VERSION ""

NS_ :

BS_:

BU_:  Inverter  Battery  Charger  Host

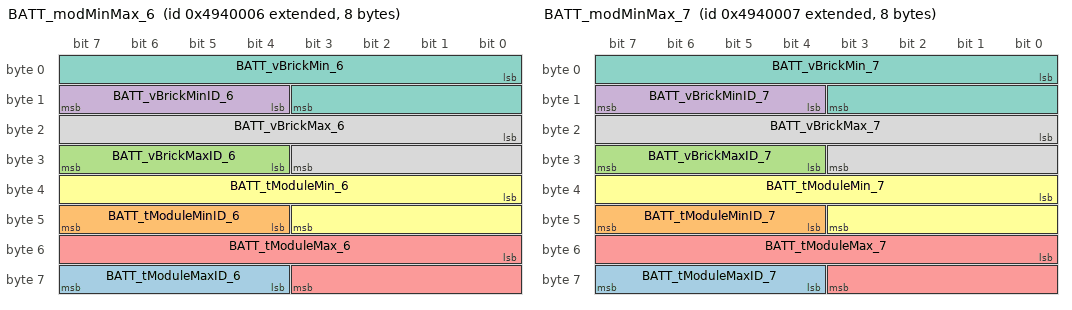
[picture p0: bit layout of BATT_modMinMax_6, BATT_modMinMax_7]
BO_ 2224291846 BATT_modMinMax_6: 8 Battery
 SG_ BATT_tModuleMaxID_6 : 60|4@1+ (1,0) [0|14] "" Battery,Host
 SG_ BATT_tModuleMinID_6 : 44|4@1+ (1,0) [0|14] "" Battery,Host
 SG_ BATT_vBrickMaxID_6 : 28|4@1+ (1,0) [0|14] "" Battery,Host
 SG_ BATT_vBrickMinID_6 : 12|4@1+ (1,0) [0|14] "" Battery,Host
 SG_ BATT_tModuleMax_6 : 48|12@1- (0.1,0) [-40|125] "deg C" Battery,Host
 SG_ BATT_tModuleMin_6 : 32|12@1- (0.1,0) [-40|125] "deg C" Battery,Host
 SG_ BATT_vBrickMin_6 : 0|12@1+ (0.002,0) [0|4.98066] "V" Battery,Host
 SG_ BATT_vBrickMax_6 : 16|12@1+ (0.002,0) [0|4.98066] "V" Battery,Host

BO_ 2224291847 BATT_modMinMax_7: 8 Battery
 SG_ BATT_tModuleMaxID_7 : 60|4@1+ (1,0) [0|14] "" Battery,Host
 SG_ BATT_tModuleMinID_7 : 44|4@1+ (1,0) [0|14] "" Battery,Host
 SG_ BATT_vBrickMaxID_7 : 28|4@1+ (1,0) [0|14] "" Battery,Host
 SG_ BATT_vBrickMinID_7 : 12|4@1+ (1,0) [0|14] "" Battery,Host
 SG_ BATT_tModuleMax_7 : 48|12@1- (0.1,0) [-40|125] "deg C" Battery,Host
 SG_ BATT_tModuleMin_7 : 32|12@1- (0.1,0) [-40|125] "deg C" Battery,Host
 SG_ BATT_vBrickMin_7 : 0|12@1+ (0.002,0) [0|4.98066] "V" Battery,Host
 SG_ BATT_vBrickMax_7 : 16|12@1+ (0.002,0) [0|4.98066] "V" Battery,Host

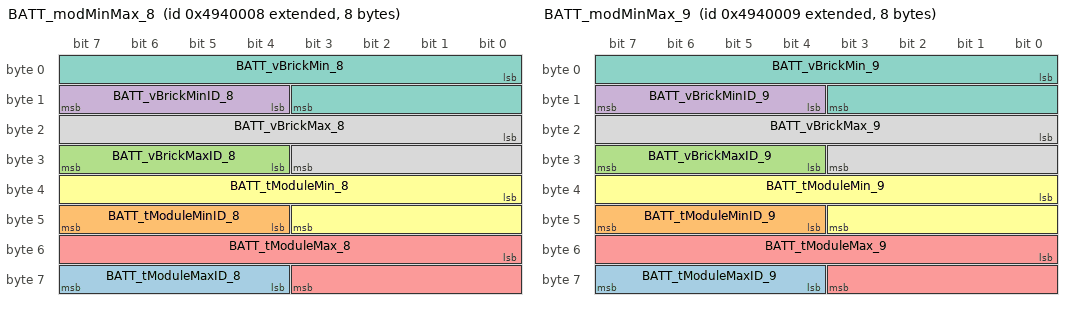
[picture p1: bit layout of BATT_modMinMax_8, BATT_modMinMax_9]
BO_ 2224291848 BATT_modMinMax_8: 8 Battery
 SG_ BATT_tModuleMaxID_8 : 60|4@1+ (1,0) [0|14] "" Battery,Host
 SG_ BATT_tModuleMinID_8 : 44|4@1+ (1,0) [0|14] "" Battery,Host
 SG_ BATT_vBrickMaxID_8 : 28|4@1+ (1,0) [0|14] "" Battery,Host
 SG_ BATT_vBrickMinID_8 : 12|4@1+ (1,0) [0|14] "" Battery,Host
 SG_ BATT_tModuleMax_8 : 48|12@1- (0.1,0) [-40|125] "deg C" Battery,Host
 SG_ BATT_tModuleMin_8 : 32|12@1- (0.1,0) [-40|125] "deg C" Battery,Host
 SG_ BATT_vBrickMin_8 : 0|12@1+ (0.002,0) [0|4.98066] "V" Battery,Host
 SG_ BATT_vBrickMax_8 : 16|12@1+ (0.002,0) [0|4.98066] "V" Battery,Host

BO_ 2224291849 BATT_modMinMax_9: 8 Battery
 SG_ BATT_tModuleMaxID_9 : 60|4@1+ (1,0) [0|14] "" Battery,Host
 SG_ BATT_tModuleMinID_9 : 44|4@1+ (1,0) [0|14] "" Battery,Host
 SG_ BATT_vBrickMaxID_9 : 28|4@1+ (1,0) [0|14] "" Battery,Host
 SG_ BATT_vBrickMinID_9 : 12|4@1+ (1,0) [0|14] "" Battery,Host
 SG_ BATT_tModuleMax_9 : 48|12@1- (0.1,0) [-40|125] "deg C" Battery,Host
 SG_ BATT_tModuleMin_9 : 32|12@1- (0.1,0) [-40|125] "deg C" Battery,Host
 SG_ BATT_vBrickMin_9 : 0|12@1+ (0.002,0) [0|4.98066] "V" Battery,Host
 SG_ BATT_vBrickMax_9 : 16|12@1+ (0.002,0) [0|4.98066] "V" Battery,Host

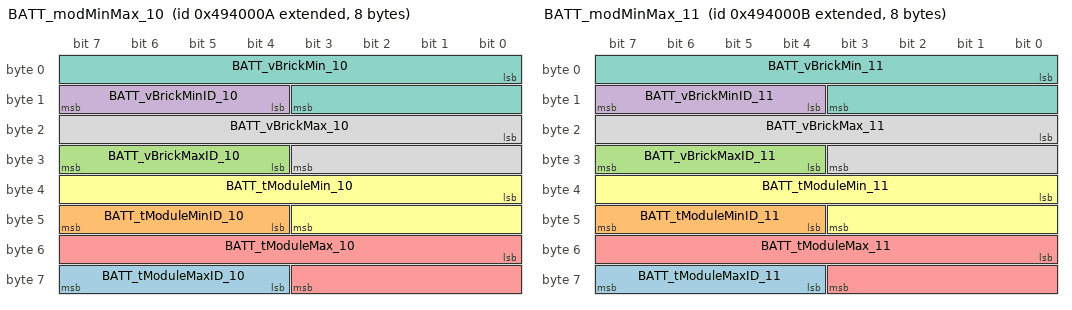
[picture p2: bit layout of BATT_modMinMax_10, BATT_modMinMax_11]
BO_ 2224291850 BATT_modMinMax_10: 8 Battery
 SG_ BATT_tModuleMaxID_10 : 60|4@1+ (1,0) [0|14] "" Battery,Host
 SG_ BATT_tModuleMinID_10 : 44|4@1+ (1,0) [0|14] "" Battery,Host
 SG_ BATT_vBrickMaxID_10 : 28|4@1+ (1,0) [0|14] "" Battery,Host
 SG_ BATT_vBrickMinID_10 : 12|4@1+ (1,0) [0|14] "" Battery,Host
 SG_ BATT_tModuleMax_10 : 48|12@1- (0.1,0) [-40|125] "deg C" Battery,Host
 SG_ BATT_tModuleMin_10 : 32|12@1- (0.1,0) [-40|125] "deg C" Battery,Host
 SG_ BATT_vBrickMin_10 : 0|12@1+ (0.002,0) [0|4.98066] "V" Battery,Host
 SG_ BATT_vBrickMax_10 : 16|12@1+ (0.002,0) [0|4.98066] "V" Battery,Host

BO_ 2224291851 BATT_modMinMax_11: 8 Battery
 SG_ BATT_tModuleMaxID_11 : 60|4@1+ (1,0) [0|14] "" Battery,Host
 SG_ BATT_tModuleMinID_11 : 44|4@1+ (1,0) [0|14] "" Battery,Host
 SG_ BATT_vBrickMaxID_11 : 28|4@1+ (1,0) [0|14] "" Battery,Host
 SG_ BATT_vBrickMinID_11 : 12|4@1+ (1,0) [0|14] "" Battery,Host
 SG_ BATT_tModuleMax_11 : 48|12@1- (0.1,0) [-40|125] "deg C" Battery,Host
 SG_ BATT_tModuleMin_11 : 32|12@1- (0.1,0) [-40|125] "deg C" Battery,Host
 SG_ BATT_vBrickMin_11 : 0|12@1+ (0.002,0) [0|4.98066] "V" Battery,Host
 SG_ BATT_vBrickMax_11 : 16|12@1+ (0.002,0) [0|4.98066] "V" Battery,Host

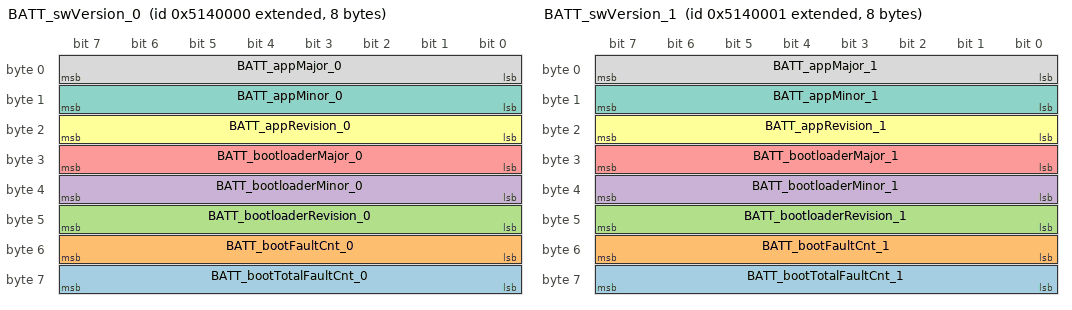
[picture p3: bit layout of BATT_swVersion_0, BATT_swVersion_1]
BO_ 2232680448 BATT_swVersion_0: 8 Battery
 SG_ BATT_bootTotalFaultCnt_0 : 56|8@1+ (1,0) [0|255] "" Host
 SG_ BATT_bootFaultCnt_0 : 48|8@1+ (1,0) [0|255] "" Host
 SG_ BATT_bootloaderRevision_0 : 40|8@1+ (1,0) [0|255] "" Host
 SG_ BATT_bootloaderMinor_0 : 32|8@1+ (1,0) [0|255] "" Host
 SG_ BATT_bootloaderMajor_0 : 24|8@1+ (1,0) [0|255] "" Host
 SG_ BATT_appRevision_0 : 16|8@1+ (1,0) [0|255] "" Host
 SG_ BATT_appMinor_0 : 8|8@1+ (1,0) [0|255] "" Host
 SG_ BATT_appMajor_0 : 0|8@1+ (1,0) [0|255] "" Host

BO_ 2232680449 BATT_swVersion_1: 8 Battery
 SG_ BATT_bootTotalFaultCnt_1 : 56|8@1+ (1,0) [0|255] "" Host
 SG_ BATT_bootFaultCnt_1 : 48|8@1+ (1,0) [0|255] "" Host
 SG_ BATT_bootloaderRevision_1 : 40|8@1+ (1,0) [0|255] "" Host
 SG_ BATT_bootloaderMinor_1 : 32|8@1+ (1,0) [0|255] "" Host
 SG_ BATT_bootloaderMajor_1 : 24|8@1+ (1,0) [0|255] "" Host
 SG_ BATT_appRevision_1 : 16|8@1+ (1,0) [0|255] "" Host
 SG_ BATT_appMinor_1 : 8|8@1+ (1,0) [0|255] "" Host
 SG_ BATT_appMajor_1 : 0|8@1+ (1,0) [0|255] "" Host

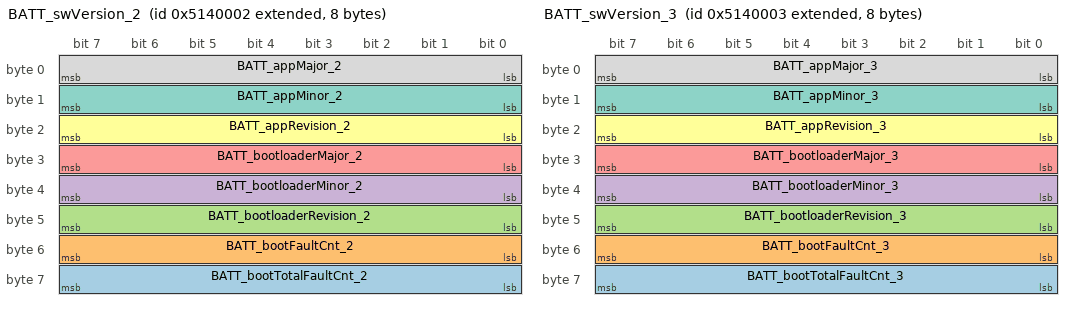
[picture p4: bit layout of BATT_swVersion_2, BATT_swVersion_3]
BO_ 2232680450 BATT_swVersion_2: 8 Battery
 SG_ BATT_bootTotalFaultCnt_2 : 56|8@1+ (1,0) [0|255] "" Host
 SG_ BATT_bootFaultCnt_2 : 48|8@1+ (1,0) [0|255] "" Host
 SG_ BATT_bootloaderRevision_2 : 40|8@1+ (1,0) [0|255] "" Host
 SG_ BATT_bootloaderMinor_2 : 32|8@1+ (1,0) [0|255] "" Host
 SG_ BATT_bootloaderMajor_2 : 24|8@1+ (1,0) [0|255] "" Host
 SG_ BATT_appRevision_2 : 16|8@1+ (1,0) [0|255] "" Host
 SG_ BATT_appMinor_2 : 8|8@1+ (1,0) [0|255] "" Host
 SG_ BATT_appMajor_2 : 0|8@1+ (1,0) [0|255] "" Host

BO_ 2232680451 BATT_swVersion_3: 8 Battery
 SG_ BATT_bootTotalFaultCnt_3 : 56|8@1+ (1,0) [0|255] "" Host
 SG_ BATT_bootFaultCnt_3 : 48|8@1+ (1,0) [0|255] "" Host
 SG_ BATT_bootloaderRevision_3 : 40|8@1+ (1,0) [0|255] "" Host
 SG_ BATT_bootloaderMinor_3 : 32|8@1+ (1,0) [0|255] "" Host
 SG_ BATT_bootloaderMajor_3 : 24|8@1+ (1,0) [0|255] "" Host
 SG_ BATT_appRevision_3 : 16|8@1+ (1,0) [0|255] "" Host
 SG_ BATT_appMinor_3 : 8|8@1+ (1,0) [0|255] "" Host
 SG_ BATT_appMajor_3 : 0|8@1+ (1,0) [0|255] "" Host

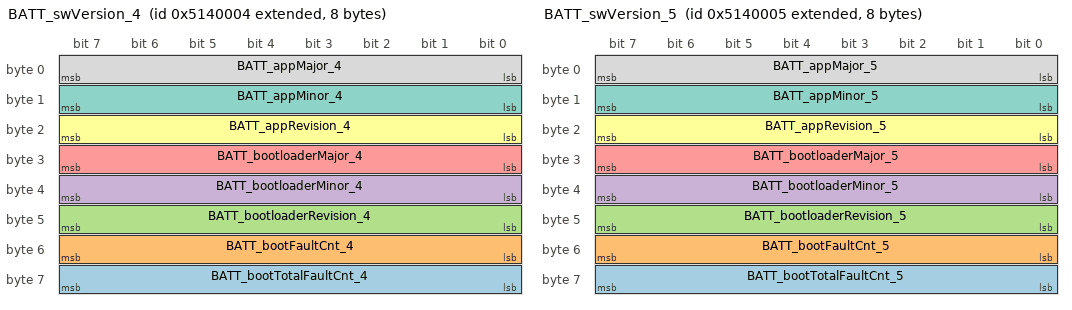
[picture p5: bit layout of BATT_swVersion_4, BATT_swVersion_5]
BO_ 2232680452 BATT_swVersion_4: 8 Battery
 SG_ BATT_bootTotalFaultCnt_4 : 56|8@1+ (1,0) [0|255] "" Host
 SG_ BATT_bootFaultCnt_4 : 48|8@1+ (1,0) [0|255] "" Host
 SG_ BATT_bootloaderRevision_4 : 40|8@1+ (1,0) [0|255] "" Host
 SG_ BATT_bootloaderMinor_4 : 32|8@1+ (1,0) [0|255] "" Host
 SG_ BATT_bootloaderMajor_4 : 24|8@1+ (1,0) [0|255] "" Host
 SG_ BATT_appRevision_4 : 16|8@1+ (1,0) [0|255] "" Host
 SG_ BATT_appMinor_4 : 8|8@1+ (1,0) [0|255] "" Host
 SG_ BATT_appMajor_4 : 0|8@1+ (1,0) [0|255] "" Host

BO_ 2232680453 BATT_swVersion_5: 8 Battery
 SG_ BATT_bootTotalFaultCnt_5 : 56|8@1+ (1,0) [0|255] "" Host
 SG_ BATT_bootFaultCnt_5 : 48|8@1+ (1,0) [0|255] "" Host
 SG_ BATT_bootloaderRevision_5 : 40|8@1+ (1,0) [0|255] "" Host
 SG_ BATT_bootloaderMinor_5 : 32|8@1+ (1,0) [0|255] "" Host
 SG_ BATT_bootloaderMajor_5 : 24|8@1+ (1,0) [0|255] "" Host
 SG_ BATT_appRevision_5 : 16|8@1+ (1,0) [0|255] "" Host
 SG_ BATT_appMinor_5 : 8|8@1+ (1,0) [0|255] "" Host
 SG_ BATT_appMajor_5 : 0|8@1+ (1,0) [0|255] "" Host

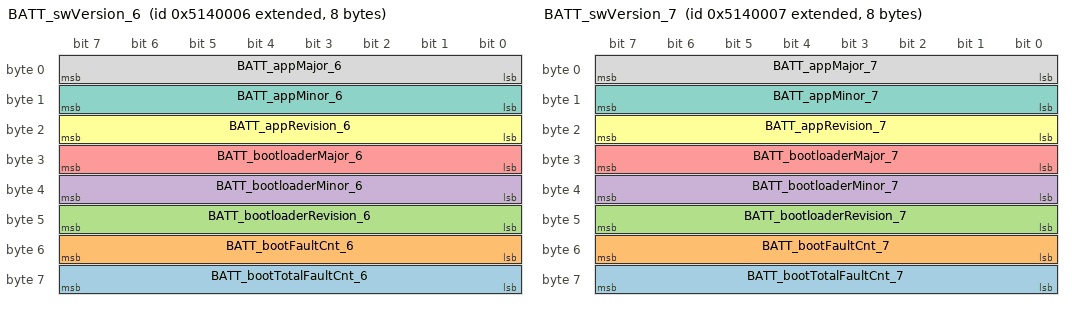
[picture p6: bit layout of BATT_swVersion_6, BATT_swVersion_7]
BO_ 2232680454 BATT_swVersion_6: 8 Battery
 SG_ BATT_bootTotalFaultCnt_6 : 56|8@1+ (1,0) [0|255] "" Host
 SG_ BATT_bootFaultCnt_6 : 48|8@1+ (1,0) [0|255] "" Host
 SG_ BATT_bootloaderRevision_6 : 40|8@1+ (1,0) [0|255] "" Host
 SG_ BATT_bootloaderMinor_6 : 32|8@1+ (1,0) [0|255] "" Host
 SG_ BATT_bootloaderMajor_6 : 24|8@1+ (1,0) [0|255] "" Host
 SG_ BATT_appRevision_6 : 16|8@1+ (1,0) [0|255] "" Host
 SG_ BATT_appMinor_6 : 8|8@1+ (1,0) [0|255] "" Host
 SG_ BATT_appMajor_6 : 0|8@1+ (1,0) [0|255] "" Host

BO_ 2232680455 BATT_swVersion_7: 8 Battery
 SG_ BATT_bootTotalFaultCnt_7 : 56|8@1+ (1,0) [0|255] "" Host
 SG_ BATT_bootFaultCnt_7 : 48|8@1+ (1,0) [0|255] "" Host
 SG_ BATT_bootloaderRevision_7 : 40|8@1+ (1,0) [0|255] "" Host
 SG_ BATT_bootloaderMinor_7 : 32|8@1+ (1,0) [0|255] "" Host
 SG_ BATT_bootloaderMajor_7 : 24|8@1+ (1,0) [0|255] "" Host
 SG_ BATT_appRevision_7 : 16|8@1+ (1,0) [0|255] "" Host
 SG_ BATT_appMinor_7 : 8|8@1+ (1,0) [0|255] "" Host
 SG_ BATT_appMajor_7 : 0|8@1+ (1,0) [0|255] "" Host

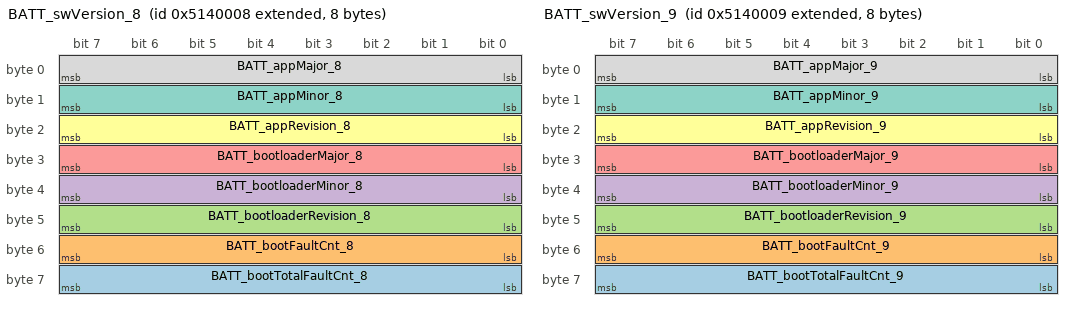
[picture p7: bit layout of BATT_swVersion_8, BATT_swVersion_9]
BO_ 2232680456 BATT_swVersion_8: 8 Battery
 SG_ BATT_bootTotalFaultCnt_8 : 56|8@1+ (1,0) [0|255] "" Host
 SG_ BATT_bootFaultCnt_8 : 48|8@1+ (1,0) [0|255] "" Host
 SG_ BATT_bootloaderRevision_8 : 40|8@1+ (1,0) [0|255] "" Host
 SG_ BATT_bootloaderMinor_8 : 32|8@1+ (1,0) [0|255] "" Host
 SG_ BATT_bootloaderMajor_8 : 24|8@1+ (1,0) [0|255] "" Host
 SG_ BATT_appRevision_8 : 16|8@1+ (1,0) [0|255] "" Host
 SG_ BATT_appMinor_8 : 8|8@1+ (1,0) [0|255] "" Host
 SG_ BATT_appMajor_8 : 0|8@1+ (1,0) [0|255] "" Host

BO_ 2232680457 BATT_swVersion_9: 8 Battery
 SG_ BATT_bootTotalFaultCnt_9 : 56|8@1+ (1,0) [0|255] "" Host
 SG_ BATT_bootFaultCnt_9 : 48|8@1+ (1,0) [0|255] "" Host
 SG_ BATT_bootloaderRevision_9 : 40|8@1+ (1,0) [0|255] "" Host
 SG_ BATT_bootloaderMinor_9 : 32|8@1+ (1,0) [0|255] "" Host
 SG_ BATT_bootloaderMajor_9 : 24|8@1+ (1,0) [0|255] "" Host
 SG_ BATT_appRevision_9 : 16|8@1+ (1,0) [0|255] "" Host
 SG_ BATT_appMinor_9 : 8|8@1+ (1,0) [0|255] "" Host
 SG_ BATT_appMajor_9 : 0|8@1+ (1,0) [0|255] "" Host

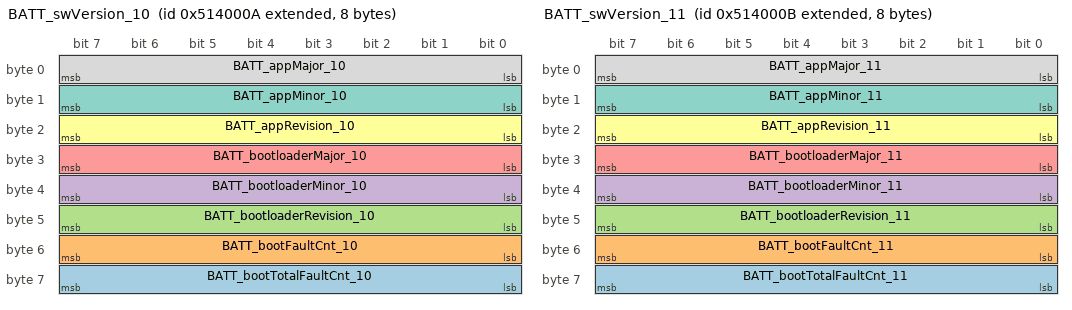
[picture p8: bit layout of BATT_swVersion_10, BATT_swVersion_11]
BO_ 2232680458 BATT_swVersion_10: 8 Battery
 SG_ BATT_bootTotalFaultCnt_10 : 56|8@1+ (1,0) [0|255] "" Host
 SG_ BATT_bootFaultCnt_10 : 48|8@1+ (1,0) [0|255] "" Host
 SG_ BATT_bootloaderRevision_10 : 40|8@1+ (1,0) [0|255] "" Host
 SG_ BATT_bootloaderMinor_10 : 32|8@1+ (1,0) [0|255] "" Host
 SG_ BATT_bootloaderMajor_10 : 24|8@1+ (1,0) [0|255] "" Host
 SG_ BATT_appRevision_10 : 16|8@1+ (1,0) [0|255] "" Host
 SG_ BATT_appMinor_10 : 8|8@1+ (1,0) [0|255] "" Host
 SG_ BATT_appMajor_10 : 0|8@1+ (1,0) [0|255] "" Host

BO_ 2232680459 BATT_swVersion_11: 8 Battery
 SG_ BATT_bootTotalFaultCnt_11 : 56|8@1+ (1,0) [0|255] "" Host
 SG_ BATT_bootFaultCnt_11 : 48|8@1+ (1,0) [0|255] "" Host
 SG_ BATT_bootloaderRevision_11 : 40|8@1+ (1,0) [0|255] "" Host
 SG_ BATT_bootloaderMinor_11 : 32|8@1+ (1,0) [0|255] "" Host
 SG_ BATT_bootloaderMajor_11 : 24|8@1+ (1,0) [0|255] "" Host
 SG_ BATT_appRevision_11 : 16|8@1+ (1,0) [0|255] "" Host
 SG_ BATT_appMinor_11 : 8|8@1+ (1,0) [0|255] "" Host
 SG_ BATT_appMajor_11 : 0|8@1+ (1,0) [0|255] "" Host

BO_ 2236874752 BATT_hardwareVersion_0: 8 Battery
 SG_ BATT_hardwareVersion_0 : 0|32@1+ (1,0) [0|4294967295] "" Host

BO_ 2236874753 BATT_hardwareVersion_1: 8 Battery
 SG_ BATT_hardwareVersion_1 : 0|32@1+ (1,0) [0|4294967295] "" Host

BO_ 2236874754 BATT_hardwareVersion_2: 8 Battery
 SG_ BATT_hardwareVersion_2 : 0|32@1+ (1,0) [0|4294967295] "" Host

BO_ 2236874755 BATT_hardwareVersion_3: 8 Battery
 SG_ BATT_hardwareVersion_3 : 0|32@1+ (1,0) [0|4294967295] "" Host

BO_ 2236874756 BATT_hardwareVersion_4: 8 Battery
 SG_ BATT_hardwareVersion_4 : 0|32@1+ (1,0) [0|4294967295] "" Host

BO_ 2236874757 BATT_hardwareVersion_5: 8 Battery
 SG_ BATT_hardwareVersion_5 : 0|32@1+ (1,0) [0|4294967295] "" Host

BO_ 2236874758 BATT_hardwareVersion_6: 8 Battery
 SG_ BATT_hardwareVersion_6 : 0|32@1+ (1,0) [0|4294967295] "" Host

BO_ 2236874759 BATT_hardwareVersion_7: 8 Battery
 SG_ BATT_hardwareVersion_7 : 0|32@1+ (1,0) [0|4294967295] "" Host

BO_ 2236874760 BATT_hardwareVersion_8: 8 Battery
 SG_ BATT_hardwareVersion_8 : 0|32@1+ (1,0) [0|4294967295] "" Host

BO_ 2236874761 BATT_hardwareVersion_9: 8 Battery
 SG_ BATT_hardwareVersion_9 : 0|32@1+ (1,0) [0|4294967295] "" Host

BO_ 2236874762 BATT_hardwareVersion_10: 8 Battery
 SG_ BATT_hardwareVersion_10 : 0|32@1+ (1,0) [0|4294967295] "" Host

BO_ 2236874763 BATT_hardwareVersion_11: 8 Battery
 SG_ BATT_hardwareVersion_11 : 0|32@1+ (1,0) [0|4294967295] "" Host

BO_ 2483290112 BATT_modStatus_0: 8 Battery
 SG_ BATT_modNumModsDataValid_0 : 60|4@1+ (1,0) [0|15] "" Battery,Host
 SG_ BATT_modNumModsOnNetwork_0 : 52|4@1+ (1,0) [0|15] "" Battery,Host
 SG_ BATT_modNumModsOnHvBus_0 : 56|4@1+ (1,0) [0|15] "" Battery,Host
 SG_ BATT_modNumModsConfigured_0 : 48|4@1+ (1,0) [0|15] "" Battery,Host
 SG_ BATT_ArbitrationComplete_0 : 15|1@1+ (1,0) [0|1] "" Battery,Host
 SG_ BATT_modStateRequested_0 : 46|2@1+ (1,0) [0|3] "" Battery,Host
 SG_ BATT_modDataValid_0 : 7|1@1+ (1,0) [0|1] "" Battery,Host
 SG_ BATT_prechargeState_0 : 43|3@1+ (1,0) [0|7] "" Battery,Host
 SG_ BATT_fetPchgCommand_0 : 42|1@1+ (1,0) [0|1] "" Battery,Host
 SG_ BATT_fetDsgCommand_0 : 40|1@1+ (1,0) [0|1] "" Battery,Host
 SG_ BATT_fetChgCommand_0 : 41|1@1+ (1,0) [0|1] "" Battery,Host
 SG_ BATT_fetDsgStatus_0 : 36|4@1+ (1,0) [0|15] "" Battery,Host
 SG_ BATT_fetChgStatus_0 : 32|4@1+ (1,0) [0|15] "" Battery,Host
 SG_ BATT_timeRampdown_0 : 24|6@1+ (1,0) [0|63] "seconds" Battery,Host
 SG_ BATT_inhRegen_0 : 31|1@1+ (1,0) [0|1] "" Battery,Host
 SG_ BATT_inhFullPower_0 : 23|1@1+ (1,0) [0|1] "" Battery,Host
 SG_ BATT_inhDriveEntry_0 : 22|1@1+ (1,0) [0|1] "" Battery,Host
 SG_ BATT_inhDrive_0 : 21|1@1+ (1,0) [0|1] "" Battery,Host
 SG_ BATT_inhContPower_0 : 30|1@1+ (1,0) [0|1] "" Battery,Host
 SG_ BATT_inhChargeEntry_0 : 19|1@1+ (1,0) [0|1] "" Battery,Host
 SG_ BATT_inhCharge_0 : 20|1@1+ (1,0) [0|1] "" Battery,Host
 SG_ BATT_modPackState_0 : 8|4@1+ (1,0) [0|15] "" Battery,Host
 SG_ BATT_modPchgChargeID_0 : 12|3@1+ (1,0) [0|7] "" Battery,Host
 SG_ BATT_modChildState_0 : 3|4@1+ (1,0) [0|15] "" Battery,Host
 SG_ BATT_modPchgDriveID_0 : 16|3@1+ (1,0) [0|7] "" Battery,Host
 SG_ BATT_modParentState_0 : 0|3@1+ (1,0) [0|4] "" Battery,Host

BO_ 2483290113 BATT_modStatus_1: 8 Battery
 SG_ BATT_modNumModsDataValid_1 : 60|4@1+ (1,0) [0|15] "" Battery,Host
 SG_ BATT_modNumModsOnNetwork_1 : 52|4@1+ (1,0) [0|15] "" Battery,Host
 SG_ BATT_modNumModsOnHvBus_1 : 56|4@1+ (1,0) [0|15] "" Battery,Host
 SG_ BATT_modNumModsConfigured_1 : 48|4@1+ (1,0) [0|15] "" Battery,Host
 SG_ BATT_ArbitrationComplete_1 : 15|1@1+ (1,0) [0|1] "" Battery,Host
 SG_ BATT_modStateRequested_1 : 46|2@1+ (1,0) [0|3] "" Battery,Host
 SG_ BATT_modDataValid_1 : 7|1@1+ (1,0) [0|1] "" Battery,Host
 SG_ BATT_prechargeState_1 : 43|3@1+ (1,0) [0|7] "" Battery,Host
 SG_ BATT_fetPchgCommand_1 : 42|1@1+ (1,0) [0|1] "" Battery,Host
 SG_ BATT_fetDsgCommand_1 : 40|1@1+ (1,0) [0|1] "" Battery,Host
 SG_ BATT_fetChgCommand_1 : 41|1@1+ (1,0) [0|1] "" Battery,Host
 SG_ BATT_fetDsgStatus_1 : 36|4@1+ (1,0) [0|15] "" Battery,Host
 SG_ BATT_fetChgStatus_1 : 32|4@1+ (1,0) [0|15] "" Battery,Host
 SG_ BATT_timeRampdown_1 : 24|6@1+ (1,0) [0|63] "seconds" Battery,Host
 SG_ BATT_inhRegen_1 : 31|1@1+ (1,0) [0|1] "" Battery,Host
 SG_ BATT_inhFullPower_1 : 23|1@1+ (1,0) [0|1] "" Battery,Host
 SG_ BATT_inhDriveEntry_1 : 22|1@1+ (1,0) [0|1] "" Battery,Host
 SG_ BATT_inhDrive_1 : 21|1@1+ (1,0) [0|1] "" Battery,Host
 SG_ BATT_inhContPower_1 : 30|1@1+ (1,0) [0|1] "" Battery,Host
 SG_ BATT_inhChargeEntry_1 : 19|1@1+ (1,0) [0|1] "" Battery,Host
 SG_ BATT_inhCharge_1 : 20|1@1+ (1,0) [0|1] "" Battery,Host
 SG_ BATT_modPackState_1 : 8|4@1+ (1,0) [0|15] "" Battery,Host
 SG_ BATT_modPchgChargeID_1 : 12|3@1+ (1,0) [0|7] "" Battery,Host
 SG_ BATT_modChildState_1 : 3|4@1+ (1,0) [0|15] "" Battery,Host
 SG_ BATT_modPchgDriveID_1 : 16|3@1+ (1,0) [0|7] "" Battery,Host
 SG_ BATT_modParentState_1 : 0|3@1+ (1,0) [0|4] "" Battery,Host

BO_ 2483290114 BATT_modStatus_2: 8 Battery
 SG_ BATT_modNumModsDataValid_2 : 60|4@1+ (1,0) [0|15] "" Battery,Host
 SG_ BATT_modNumModsOnNetwork_2 : 52|4@1+ (1,0) [0|15] "" Battery,Host
 SG_ BATT_modNumModsOnHvBus_2 : 56|4@1+ (1,0) [0|15] "" Battery,Host
 SG_ BATT_modNumModsConfigured_2 : 48|4@1+ (1,0) [0|15] "" Battery,Host
 SG_ BATT_ArbitrationComplete_2 : 15|1@1+ (1,0) [0|1] "" Battery,Host
 SG_ BATT_modStateRequested_2 : 46|2@1+ (1,0) [0|3] "" Battery,Host
 SG_ BATT_modDataValid_2 : 7|1@1+ (1,0) [0|1] "" Battery,Host
 SG_ BATT_prechargeState_2 : 43|3@1+ (1,0) [0|7] "" Battery,Host
 SG_ BATT_fetPchgCommand_2 : 42|1@1+ (1,0) [0|1] "" Battery,Host
 SG_ BATT_fetDsgCommand_2 : 40|1@1+ (1,0) [0|1] "" Battery,Host
 SG_ BATT_fetChgCommand_2 : 41|1@1+ (1,0) [0|1] "" Battery,Host
 SG_ BATT_fetDsgStatus_2 : 36|4@1+ (1,0) [0|15] "" Battery,Host
 SG_ BATT_fetChgStatus_2 : 32|4@1+ (1,0) [0|15] "" Battery,Host
 SG_ BATT_timeRampdown_2 : 24|6@1+ (1,0) [0|63] "seconds" Battery,Host
 SG_ BATT_inhRegen_2 : 31|1@1+ (1,0) [0|1] "" Battery,Host
 SG_ BATT_inhFullPower_2 : 23|1@1+ (1,0) [0|1] "" Battery,Host
 SG_ BATT_inhDriveEntry_2 : 22|1@1+ (1,0) [0|1] "" Battery,Host
 SG_ BATT_inhDrive_2 : 21|1@1+ (1,0) [0|1] "" Battery,Host
 SG_ BATT_inhContPower_2 : 30|1@1+ (1,0) [0|1] "" Battery,Host
 SG_ BATT_inhChargeEntry_2 : 19|1@1+ (1,0) [0|1] "" Battery,Host
 SG_ BATT_inhCharge_2 : 20|1@1+ (1,0) [0|1] "" Battery,Host
 SG_ BATT_modPackState_2 : 8|4@1+ (1,0) [0|15] "" Battery,Host
 SG_ BATT_modPchgChargeID_2 : 12|3@1+ (1,0) [0|7] "" Battery,Host
 SG_ BATT_modChildState_2 : 3|4@1+ (1,0) [0|15] "" Battery,Host
 SG_ BATT_modPchgDriveID_2 : 16|3@1+ (1,0) [0|7] "" Battery,Host
 SG_ BATT_modParentState_2 : 0|3@1+ (1,0) [0|4] "" Battery,Host

BO_ 2483290115 BATT_modStatus_3: 8 Battery
 SG_ BATT_modNumModsDataValid_3 : 60|4@1+ (1,0) [0|15] "" Battery,Host
 SG_ BATT_modNumModsOnNetwork_3 : 52|4@1+ (1,0) [0|15] "" Battery,Host
 SG_ BATT_modNumModsOnHvBus_3 : 56|4@1+ (1,0) [0|15] "" Battery,Host
 SG_ BATT_modNumModsConfigured_3 : 48|4@1+ (1,0) [0|15] "" Battery,Host
 SG_ BATT_ArbitrationComplete_3 : 15|1@1+ (1,0) [0|1] "" Battery,Host
 SG_ BATT_modStateRequested_3 : 46|2@1+ (1,0) [0|3] "" Battery,Host
 SG_ BATT_modDataValid_3 : 7|1@1+ (1,0) [0|1] "" Battery,Host
 SG_ BATT_prechargeState_3 : 43|3@1+ (1,0) [0|7] "" Battery,Host
 SG_ BATT_fetPchgCommand_3 : 42|1@1+ (1,0) [0|1] "" Battery,Host
 SG_ BATT_fetDsgCommand_3 : 40|1@1+ (1,0) [0|1] "" Battery,Host
 SG_ BATT_fetChgCommand_3 : 41|1@1+ (1,0) [0|1] "" Battery,Host
 SG_ BATT_fetDsgStatus_3 : 36|4@1+ (1,0) [0|15] "" Battery,Host
 SG_ BATT_fetChgStatus_3 : 32|4@1+ (1,0) [0|15] "" Battery,Host
 SG_ BATT_timeRampdown_3 : 24|6@1+ (1,0) [0|63] "seconds" Battery,Host
 SG_ BATT_inhRegen_3 : 31|1@1+ (1,0) [0|1] "" Battery,Host
 SG_ BATT_inhFullPower_3 : 23|1@1+ (1,0) [0|1] "" Battery,Host
 SG_ BATT_inhDriveEntry_3 : 22|1@1+ (1,0) [0|1] "" Battery,Host
 SG_ BATT_inhDrive_3 : 21|1@1+ (1,0) [0|1] "" Battery,Host
 SG_ BATT_inhContPower_3 : 30|1@1+ (1,0) [0|1] "" Battery,Host
 SG_ BATT_inhChargeEntry_3 : 19|1@1+ (1,0) [0|1] "" Battery,Host
 SG_ BATT_inhCharge_3 : 20|1@1+ (1,0) [0|1] "" Battery,Host
 SG_ BATT_modPackState_3 : 8|4@1+ (1,0) [0|15] "" Battery,Host
 SG_ BATT_modPchgChargeID_3 : 12|3@1+ (1,0) [0|7] "" Battery,Host
 SG_ BATT_modChildState_3 : 3|4@1+ (1,0) [0|15] "" Battery,Host
 SG_ BATT_modPchgDriveID_3 : 16|3@1+ (1,0) [0|7] "" Battery,Host
 SG_ BATT_modParentState_3 : 0|3@1+ (1,0) [0|4] "" Battery,Host

BO_ 2483290116 BATT_modStatus_4: 8 Battery
 SG_ BATT_modNumModsDataValid_4 : 60|4@1+ (1,0) [0|15] "" Battery,Host
 SG_ BATT_modNumModsOnNetwork_4 : 52|4@1+ (1,0) [0|15] "" Battery,Host
 SG_ BATT_modNumModsOnHvBus_4 : 56|4@1+ (1,0) [0|15] "" Battery,Host
 SG_ BATT_modNumModsConfigured_4 : 48|4@1+ (1,0) [0|15] "" Battery,Host
 SG_ BATT_ArbitrationComplete_4 : 15|1@1+ (1,0) [0|1] "" Battery,Host
 SG_ BATT_modStateRequested_4 : 46|2@1+ (1,0) [0|3] "" Battery,Host
 SG_ BATT_modDataValid_4 : 7|1@1+ (1,0) [0|1] "" Battery,Host
 SG_ BATT_prechargeState_4 : 43|3@1+ (1,0) [0|7] "" Battery,Host
 SG_ BATT_fetPchgCommand_4 : 42|1@1+ (1,0) [0|1] "" Battery,Host
 SG_ BATT_fetDsgCommand_4 : 40|1@1+ (1,0) [0|1] "" Battery,Host
 SG_ BATT_fetChgCommand_4 : 41|1@1+ (1,0) [0|1] "" Battery,Host
 SG_ BATT_fetDsgStatus_4 : 36|4@1+ (1,0) [0|15] "" Battery,Host
 SG_ BATT_fetChgStatus_4 : 32|4@1+ (1,0) [0|15] "" Battery,Host
 SG_ BATT_timeRampdown_4 : 24|6@1+ (1,0) [0|63] "seconds" Battery,Host
 SG_ BATT_inhRegen_4 : 31|1@1+ (1,0) [0|1] "" Battery,Host
 SG_ BATT_inhFullPower_4 : 23|1@1+ (1,0) [0|1] "" Battery,Host
 SG_ BATT_inhDriveEntry_4 : 22|1@1+ (1,0) [0|1] "" Battery,Host
 SG_ BATT_inhDrive_4 : 21|1@1+ (1,0) [0|1] "" Battery,Host
 SG_ BATT_inhContPower_4 : 30|1@1+ (1,0) [0|1] "" Battery,Host
 SG_ BATT_inhChargeEntry_4 : 19|1@1+ (1,0) [0|1] "" Battery,Host
 SG_ BATT_inhCharge_4 : 20|1@1+ (1,0) [0|1] "" Battery,Host
 SG_ BATT_modPackState_4 : 8|4@1+ (1,0) [0|15] "" Battery,Host
 SG_ BATT_modPchgChargeID_4 : 12|3@1+ (1,0) [0|7] "" Battery,Host
 SG_ BATT_modChildState_4 : 3|4@1+ (1,0) [0|15] "" Battery,Host
 SG_ BATT_modPchgDriveID_4 : 16|3@1+ (1,0) [0|7] "" Battery,Host
 SG_ BATT_modParentState_4 : 0|3@1+ (1,0) [0|4] "" Battery,Host

BO_ 2483290117 BATT_modStatus_5: 8 Battery
 SG_ BATT_modNumModsDataValid_5 : 60|4@1+ (1,0) [0|15] "" Battery,Host
 SG_ BATT_modNumModsOnNetwork_5 : 52|4@1+ (1,0) [0|15] "" Battery,Host
 SG_ BATT_modNumModsOnHvBus_5 : 56|4@1+ (1,0) [0|15] "" Battery,Host
 SG_ BATT_modNumModsConfigured_5 : 48|4@1+ (1,0) [0|15] "" Battery,Host
 SG_ BATT_ArbitrationComplete_5 : 15|1@1+ (1,0) [0|1] "" Battery,Host
 SG_ BATT_modStateRequested_5 : 46|2@1+ (1,0) [0|3] "" Battery,Host
 SG_ BATT_modDataValid_5 : 7|1@1+ (1,0) [0|1] "" Battery,Host
 SG_ BATT_prechargeState_5 : 43|3@1+ (1,0) [0|7] "" Battery,Host
 SG_ BATT_fetPchgCommand_5 : 42|1@1+ (1,0) [0|1] "" Battery,Host
 SG_ BATT_fetDsgCommand_5 : 40|1@1+ (1,0) [0|1] "" Battery,Host
 SG_ BATT_fetChgCommand_5 : 41|1@1+ (1,0) [0|1] "" Battery,Host
 SG_ BATT_fetDsgStatus_5 : 36|4@1+ (1,0) [0|15] "" Battery,Host
 SG_ BATT_fetChgStatus_5 : 32|4@1+ (1,0) [0|15] "" Battery,Host
 SG_ BATT_timeRampdown_5 : 24|6@1+ (1,0) [0|63] "seconds" Battery,Host
 SG_ BATT_inhRegen_5 : 31|1@1+ (1,0) [0|1] "" Battery,Host
 SG_ BATT_inhFullPower_5 : 23|1@1+ (1,0) [0|1] "" Battery,Host
 SG_ BATT_inhDriveEntry_5 : 22|1@1+ (1,0) [0|1] "" Battery,Host
 SG_ BATT_inhDrive_5 : 21|1@1+ (1,0) [0|1] "" Battery,Host
 SG_ BATT_inhContPower_5 : 30|1@1+ (1,0) [0|1] "" Battery,Host
 SG_ BATT_inhChargeEntry_5 : 19|1@1+ (1,0) [0|1] "" Battery,Host
 SG_ BATT_inhCharge_5 : 20|1@1+ (1,0) [0|1] "" Battery,Host
 SG_ BATT_modPackState_5 : 8|4@1+ (1,0) [0|15] "" Battery,Host
 SG_ BATT_modPchgChargeID_5 : 12|3@1+ (1,0) [0|7] "" Battery,Host
 SG_ BATT_modChildState_5 : 3|4@1+ (1,0) [0|15] "" Battery,Host
 SG_ BATT_modPchgDriveID_5 : 16|3@1+ (1,0) [0|7] "" Battery,Host
 SG_ BATT_modParentState_5 : 0|3@1+ (1,0) [0|4] "" Battery,Host

BO_ 2483290118 BATT_modStatus_6: 8 Battery
 SG_ BATT_modNumModsDataValid_6 : 60|4@1+ (1,0) [0|15] "" Battery,Host
 SG_ BATT_modNumModsOnNetwork_6 : 52|4@1+ (1,0) [0|15] "" Battery,Host
 SG_ BATT_modNumModsOnHvBus_6 : 56|4@1+ (1,0) [0|15] "" Battery,Host
 SG_ BATT_modNumModsConfigured_6 : 48|4@1+ (1,0) [0|15] "" Battery,Host
 SG_ BATT_ArbitrationComplete_6 : 15|1@1+ (1,0) [0|1] "" Battery,Host
 SG_ BATT_modStateRequested_6 : 46|2@1+ (1,0) [0|3] "" Battery,Host
 SG_ BATT_modDataValid_6 : 7|1@1+ (1,0) [0|1] "" Battery,Host
 SG_ BATT_prechargeState_6 : 43|3@1+ (1,0) [0|7] "" Battery,Host
 SG_ BATT_fetPchgCommand_6 : 42|1@1+ (1,0) [0|1] "" Battery,Host
 SG_ BATT_fetDsgCommand_6 : 40|1@1+ (1,0) [0|1] "" Battery,Host
 SG_ BATT_fetChgCommand_6 : 41|1@1+ (1,0) [0|1] "" Battery,Host
 SG_ BATT_fetDsgStatus_6 : 36|4@1+ (1,0) [0|15] "" Battery,Host
 SG_ BATT_fetChgStatus_6 : 32|4@1+ (1,0) [0|15] "" Battery,Host
 SG_ BATT_timeRampdown_6 : 24|6@1+ (1,0) [0|63] "seconds" Battery,Host
 SG_ BATT_inhRegen_6 : 31|1@1+ (1,0) [0|1] "" Battery,Host
 SG_ BATT_inhFullPower_6 : 23|1@1+ (1,0) [0|1] "" Battery,Host
 SG_ BATT_inhDriveEntry_6 : 22|1@1+ (1,0) [0|1] "" Battery,Host
 SG_ BATT_inhDrive_6 : 21|1@1+ (1,0) [0|1] "" Battery,Host
 SG_ BATT_inhContPower_6 : 30|1@1+ (1,0) [0|1] "" Battery,Host
 SG_ BATT_inhChargeEntry_6 : 19|1@1+ (1,0) [0|1] "" Battery,Host
 SG_ BATT_inhCharge_6 : 20|1@1+ (1,0) [0|1] "" Battery,Host
 SG_ BATT_modPackState_6 : 8|4@1+ (1,0) [0|15] "" Battery,Host
 SG_ BATT_modPchgChargeID_6 : 12|3@1+ (1,0) [0|7] "" Battery,Host
 SG_ BATT_modChildState_6 : 3|4@1+ (1,0) [0|15] "" Battery,Host
 SG_ BATT_modPchgDriveID_6 : 16|3@1+ (1,0) [0|7] "" Battery,Host
 SG_ BATT_modParentState_6 : 0|3@1+ (1,0) [0|4] "" Battery,Host

BO_ 2483290119 BATT_modStatus_7: 8 Battery
 SG_ BATT_modNumModsDataValid_7 : 60|4@1+ (1,0) [0|15] "" Battery,Host
 SG_ BATT_modNumModsOnNetwork_7 : 52|4@1+ (1,0) [0|15] "" Battery,Host
 SG_ BATT_modNumModsOnHvBus_7 : 56|4@1+ (1,0) [0|15] "" Battery,Host
 SG_ BATT_modNumModsConfigured_7 : 48|4@1+ (1,0) [0|15] "" Battery,Host
 SG_ BATT_ArbitrationComplete_7 : 15|1@1+ (1,0) [0|1] "" Battery,Host
 SG_ BATT_modStateRequested_7 : 46|2@1+ (1,0) [0|3] "" Battery,Host
 SG_ BATT_modDataValid_7 : 7|1@1+ (1,0) [0|1] "" Battery,Host
 SG_ BATT_prechargeState_7 : 43|3@1+ (1,0) [0|7] "" Battery,Host
 SG_ BATT_fetPchgCommand_7 : 42|1@1+ (1,0) [0|1] "" Battery,Host
 SG_ BATT_fetDsgCommand_7 : 40|1@1+ (1,0) [0|1] "" Battery,Host
 SG_ BATT_fetChgCommand_7 : 41|1@1+ (1,0) [0|1] "" Battery,Host
 SG_ BATT_fetDsgStatus_7 : 36|4@1+ (1,0) [0|15] "" Battery,Host
 SG_ BATT_fetChgStatus_7 : 32|4@1+ (1,0) [0|15] "" Battery,Host
 SG_ BATT_timeRampdown_7 : 24|6@1+ (1,0) [0|63] "seconds" Battery,Host
 SG_ BATT_inhRegen_7 : 31|1@1+ (1,0) [0|1] "" Battery,Host
 SG_ BATT_inhFullPower_7 : 23|1@1+ (1,0) [0|1] "" Battery,Host
 SG_ BATT_inhDriveEntry_7 : 22|1@1+ (1,0) [0|1] "" Battery,Host
 SG_ BATT_inhDrive_7 : 21|1@1+ (1,0) [0|1] "" Battery,Host
 SG_ BATT_inhContPower_7 : 30|1@1+ (1,0) [0|1] "" Battery,Host
 SG_ BATT_inhChargeEntry_7 : 19|1@1+ (1,0) [0|1] "" Battery,Host
 SG_ BATT_inhCharge_7 : 20|1@1+ (1,0) [0|1] "" Battery,Host
 SG_ BATT_modPackState_7 : 8|4@1+ (1,0) [0|15] "" Battery,Host
 SG_ BATT_modPchgChargeID_7 : 12|3@1+ (1,0) [0|7] "" Battery,Host
 SG_ BATT_modChildState_7 : 3|4@1+ (1,0) [0|15] "" Battery,Host
 SG_ BATT_modPchgDriveID_7 : 16|3@1+ (1,0) [0|7] "" Battery,Host
 SG_ BATT_modParentState_7 : 0|3@1+ (1,0) [0|4] "" Battery,Host

BO_ 2483290120 BATT_modStatus_8: 8 Battery
 SG_ BATT_modNumModsDataValid_8 : 60|4@1+ (1,0) [0|15] "" Battery,Host
 SG_ BATT_modNumModsOnNetwork_8 : 52|4@1+ (1,0) [0|15] "" Battery,Host
 SG_ BATT_modNumModsOnHvBus_8 : 56|4@1+ (1,0) [0|15] "" Battery,Host
 SG_ BATT_modNumModsConfigured_8 : 48|4@1+ (1,0) [0|15] "" Battery,Host
 SG_ BATT_ArbitrationComplete_8 : 15|1@1+ (1,0) [0|1] "" Battery,Host
 SG_ BATT_modStateRequested_8 : 46|2@1+ (1,0) [0|3] "" Battery,Host
 SG_ BATT_modDataValid_8 : 7|1@1+ (1,0) [0|1] "" Battery,Host
 SG_ BATT_prechargeState_8 : 43|3@1+ (1,0) [0|7] "" Battery,Host
 SG_ BATT_fetPchgCommand_8 : 42|1@1+ (1,0) [0|1] "" Battery,Host
 SG_ BATT_fetDsgCommand_8 : 40|1@1+ (1,0) [0|1] "" Battery,Host
 SG_ BATT_fetChgCommand_8 : 41|1@1+ (1,0) [0|1] "" Battery,Host
 SG_ BATT_fetDsgStatus_8 : 36|4@1+ (1,0) [0|15] "" Battery,Host
 SG_ BATT_fetChgStatus_8 : 32|4@1+ (1,0) [0|15] "" Battery,Host
 SG_ BATT_timeRampdown_8 : 24|6@1+ (1,0) [0|63] "seconds" Battery,Host
 SG_ BATT_inhRegen_8 : 31|1@1+ (1,0) [0|1] "" Battery,Host
 SG_ BATT_inhFullPower_8 : 23|1@1+ (1,0) [0|1] "" Battery,Host
 SG_ BATT_inhDriveEntry_8 : 22|1@1+ (1,0) [0|1] "" Battery,Host
 SG_ BATT_inhDrive_8 : 21|1@1+ (1,0) [0|1] "" Battery,Host
 SG_ BATT_inhContPower_8 : 30|1@1+ (1,0) [0|1] "" Battery,Host
 SG_ BATT_inhChargeEntry_8 : 19|1@1+ (1,0) [0|1] "" Battery,Host
 SG_ BATT_inhCharge_8 : 20|1@1+ (1,0) [0|1] "" Battery,Host
 SG_ BATT_modPackState_8 : 8|4@1+ (1,0) [0|15] "" Battery,Host
 SG_ BATT_modPchgChargeID_8 : 12|3@1+ (1,0) [0|7] "" Battery,Host
 SG_ BATT_modChildState_8 : 3|4@1+ (1,0) [0|15] "" Battery,Host
 SG_ BATT_modPchgDriveID_8 : 16|3@1+ (1,0) [0|7] "" Battery,Host
 SG_ BATT_modParentState_8 : 0|3@1+ (1,0) [0|4] "" Battery,Host

BO_ 2483290121 BATT_modStatus_9: 8 Battery
 SG_ BATT_modNumModsDataValid_9 : 60|4@1+ (1,0) [0|15] "" Battery,Host
 SG_ BATT_modNumModsOnNetwork_9 : 52|4@1+ (1,0) [0|15] "" Battery,Host
 SG_ BATT_modNumModsOnHvBus_9 : 56|4@1+ (1,0) [0|15] "" Battery,Host
 SG_ BATT_modNumModsConfigured_9 : 48|4@1+ (1,0) [0|15] "" Battery,Host
 SG_ BATT_ArbitrationComplete_9 : 15|1@1+ (1,0) [0|1] "" Battery,Host
 SG_ BATT_modStateRequested_9 : 46|2@1+ (1,0) [0|3] "" Battery,Host
 SG_ BATT_modDataValid_9 : 7|1@1+ (1,0) [0|1] "" Battery,Host
 SG_ BATT_prechargeState_9 : 43|3@1+ (1,0) [0|7] "" Battery,Host
 SG_ BATT_fetPchgCommand_9 : 42|1@1+ (1,0) [0|1] "" Battery,Host
 SG_ BATT_fetDsgCommand_9 : 40|1@1+ (1,0) [0|1] "" Battery,Host
 SG_ BATT_fetChgCommand_9 : 41|1@1+ (1,0) [0|1] "" Battery,Host
 SG_ BATT_fetDsgStatus_9 : 36|4@1+ (1,0) [0|15] "" Battery,Host
 SG_ BATT_fetChgStatus_9 : 32|4@1+ (1,0) [0|15] "" Battery,Host
 SG_ BATT_timeRampdown_9 : 24|6@1+ (1,0) [0|63] "seconds" Battery,Host
 SG_ BATT_inhRegen_9 : 31|1@1+ (1,0) [0|1] "" Battery,Host
 SG_ BATT_inhFullPower_9 : 23|1@1+ (1,0) [0|1] "" Battery,Host
 SG_ BATT_inhDriveEntry_9 : 22|1@1+ (1,0) [0|1] "" Battery,Host
 SG_ BATT_inhDrive_9 : 21|1@1+ (1,0) [0|1] "" Battery,Host
 SG_ BATT_inhContPower_9 : 30|1@1+ (1,0) [0|1] "" Battery,Host
 SG_ BATT_inhChargeEntry_9 : 19|1@1+ (1,0) [0|1] "" Battery,Host
 SG_ BATT_inhCharge_9 : 20|1@1+ (1,0) [0|1] "" Battery,Host
 SG_ BATT_modPackState_9 : 8|4@1+ (1,0) [0|15] "" Battery,Host
 SG_ BATT_modPchgChargeID_9 : 12|3@1+ (1,0) [0|7] "" Battery,Host
 SG_ BATT_modChildState_9 : 3|4@1+ (1,0) [0|15] "" Battery,Host
 SG_ BATT_modPchgDriveID_9 : 16|3@1+ (1,0) [0|7] "" Battery,Host
 SG_ BATT_modParentState_9 : 0|3@1+ (1,0) [0|4] "" Battery,Host

BO_ 2483290122 BATT_modStatus_10: 8 Battery
 SG_ BATT_modNumModsDataValid_10 : 60|4@1+ (1,0) [0|15] "" Battery,Host
 SG_ BATT_modNumModsOnNetwork_10 : 52|4@1+ (1,0) [0|15] "" Battery,Host
 SG_ BATT_modNumModsOnHvBus_10 : 56|4@1+ (1,0) [0|15] "" Battery,Host
 SG_ BATT_modNumModsConfigured_10 : 48|4@1+ (1,0) [0|15] "" Battery,Host
 SG_ BATT_ArbitrationComplete_10 : 15|1@1+ (1,0) [0|1] "" Battery,Host
 SG_ BATT_modStateRequested_10 : 46|2@1+ (1,0) [0|3] "" Battery,Host
 SG_ BATT_modDataValid_10 : 7|1@1+ (1,0) [0|1] "" Battery,Host
 SG_ BATT_prechargeState_10 : 43|3@1+ (1,0) [0|7] "" Battery,Host
 SG_ BATT_fetPchgCommand_10 : 42|1@1+ (1,0) [0|1] "" Battery,Host
 SG_ BATT_fetDsgCommand_10 : 40|1@1+ (1,0) [0|1] "" Battery,Host
 SG_ BATT_fetChgCommand_10 : 41|1@1+ (1,0) [0|1] "" Battery,Host
 SG_ BATT_fetDsgStatus_10 : 36|4@1+ (1,0) [0|15] "" Battery,Host
 SG_ BATT_fetChgStatus_10 : 32|4@1+ (1,0) [0|15] "" Battery,Host
 SG_ BATT_timeRampdown_10 : 24|6@1+ (1,0) [0|63] "seconds" Battery,Host
 SG_ BATT_inhRegen_10 : 31|1@1+ (1,0) [0|1] "" Battery,Host
 SG_ BATT_inhFullPower_10 : 23|1@1+ (1,0) [0|1] "" Battery,Host
 SG_ BATT_inhDriveEntry_10 : 22|1@1+ (1,0) [0|1] "" Battery,Host
 SG_ BATT_inhDrive_10 : 21|1@1+ (1,0) [0|1] "" Battery,Host
 SG_ BATT_inhContPower_10 : 30|1@1+ (1,0) [0|1] "" Battery,Host
 SG_ BATT_inhChargeEntry_10 : 19|1@1+ (1,0) [0|1] "" Battery,Host
 SG_ BATT_inhCharge_10 : 20|1@1+ (1,0) [0|1] "" Battery,Host
 SG_ BATT_modPackState_10 : 8|4@1+ (1,0) [0|15] "" Battery,Host
 SG_ BATT_modPchgChargeID_10 : 12|3@1+ (1,0) [0|7] "" Battery,Host
 SG_ BATT_modChildState_10 : 3|4@1+ (1,0) [0|15] "" Battery,Host
 SG_ BATT_modPchgDriveID_10 : 16|3@1+ (1,0) [0|7] "" Battery,Host
 SG_ BATT_modParentState_10 : 0|3@1+ (1,0) [0|4] "" Battery,Host

BO_ 2483290123 BATT_modStatus_11: 8 Battery
 SG_ BATT_modNumModsDataValid_11 : 60|4@1+ (1,0) [0|15] "" Battery,Host
 SG_ BATT_modNumModsOnNetwork_11 : 52|4@1+ (1,0) [0|15] "" Battery,Host
 SG_ BATT_modNumModsOnHvBus_11 : 56|4@1+ (1,0) [0|15] "" Battery,Host
 SG_ BATT_modNumModsConfigured_11 : 48|4@1+ (1,0) [0|15] "" Battery,Host
 SG_ BATT_ArbitrationComplete_11 : 15|1@1+ (1,0) [0|1] "" Battery,Host
 SG_ BATT_modStateRequested_11 : 46|2@1+ (1,0) [0|3] "" Battery,Host
 SG_ BATT_modDataValid_11 : 7|1@1+ (1,0) [0|1] "" Battery,Host
 SG_ BATT_prechargeState_11 : 43|3@1+ (1,0) [0|7] "" Battery,Host
 SG_ BATT_fetPchgCommand_11 : 42|1@1+ (1,0) [0|1] "" Battery,Host
 SG_ BATT_fetDsgCommand_11 : 40|1@1+ (1,0) [0|1] "" Battery,Host
 SG_ BATT_fetChgCommand_11 : 41|1@1+ (1,0) [0|1] "" Battery,Host
 SG_ BATT_fetDsgStatus_11 : 36|4@1+ (1,0) [0|15] "" Battery,Host
 SG_ BATT_fetChgStatus_11 : 32|4@1+ (1,0) [0|15] "" Battery,Host
 SG_ BATT_timeRampdown_11 : 24|6@1+ (1,0) [0|63] "seconds" Battery,Host
 SG_ BATT_inhRegen_11 : 31|1@1+ (1,0) [0|1] "" Battery,Host
 SG_ BATT_inhFullPower_11 : 23|1@1+ (1,0) [0|1] "" Battery,Host
 SG_ BATT_inhDriveEntry_11 : 22|1@1+ (1,0) [0|1] "" Battery,Host
 SG_ BATT_inhDrive_11 : 21|1@1+ (1,0) [0|1] "" Battery,Host
 SG_ BATT_inhContPower_11 : 30|1@1+ (1,0) [0|1] "" Battery,Host
 SG_ BATT_inhChargeEntry_11 : 19|1@1+ (1,0) [0|1] "" Battery,Host
 SG_ BATT_inhCharge_11 : 20|1@1+ (1,0) [0|1] "" Battery,Host
 SG_ BATT_modPackState_11 : 8|4@1+ (1,0) [0|15] "" Battery,Host
 SG_ BATT_modPchgChargeID_11 : 12|3@1+ (1,0) [0|7] "" Battery,Host
 SG_ BATT_modChildState_11 : 3|4@1+ (1,0) [0|15] "" Battery,Host
 SG_ BATT_modPchgDriveID_11 : 16|3@1+ (1,0) [0|7] "" Battery,Host
 SG_ BATT_modParentState_11 : 0|3@1+ (1,0) [0|4] "" Battery,Host

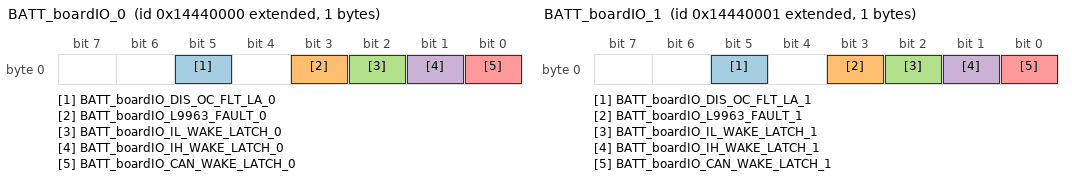
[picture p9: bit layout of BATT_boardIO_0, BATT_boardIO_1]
BO_ 2487484416 BATT_boardIO_0: 1 Battery
 SG_ BATT_boardIO_DIS_OC_FLT_LA_0 : 5|1@1+ (1,0) [0|1] "" Host
 SG_ BATT_boardIO_L9963_FAULT_0 : 3|1@1+ (1,0) [0|1] "" Host
 SG_ BATT_boardIO_IL_WAKE_LATCH_0 : 2|1@1+ (1,0) [0|1] "" Host
 SG_ BATT_boardIO_IH_WAKE_LATCH_0 : 1|1@1+ (1,0) [0|1] "" Host
 SG_ BATT_boardIO_CAN_WAKE_LATCH_0 : 0|1@1+ (1,0) [0|1] "" Host

BO_ 2487484417 BATT_boardIO_1: 1 Battery
 SG_ BATT_boardIO_DIS_OC_FLT_LA_1 : 5|1@1+ (1,0) [0|1] "" Host
 SG_ BATT_boardIO_L9963_FAULT_1 : 3|1@1+ (1,0) [0|1] "" Host
 SG_ BATT_boardIO_IL_WAKE_LATCH_1 : 2|1@1+ (1,0) [0|1] "" Host
 SG_ BATT_boardIO_IH_WAKE_LATCH_1 : 1|1@1+ (1,0) [0|1] "" Host
 SG_ BATT_boardIO_CAN_WAKE_LATCH_1 : 0|1@1+ (1,0) [0|1] "" Host

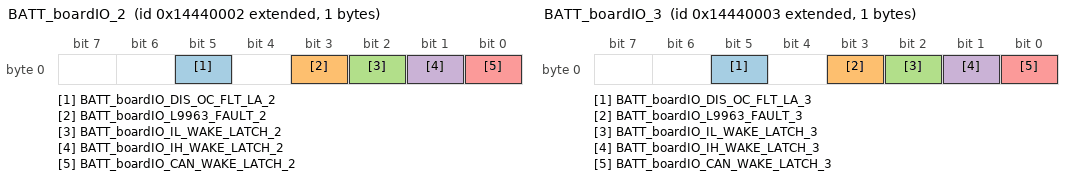
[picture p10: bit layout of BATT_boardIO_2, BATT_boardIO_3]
BO_ 2487484418 BATT_boardIO_2: 1 Battery
 SG_ BATT_boardIO_DIS_OC_FLT_LA_2 : 5|1@1+ (1,0) [0|1] "" Host
 SG_ BATT_boardIO_L9963_FAULT_2 : 3|1@1+ (1,0) [0|1] "" Host
 SG_ BATT_boardIO_IL_WAKE_LATCH_2 : 2|1@1+ (1,0) [0|1] "" Host
 SG_ BATT_boardIO_IH_WAKE_LATCH_2 : 1|1@1+ (1,0) [0|1] "" Host
 SG_ BATT_boardIO_CAN_WAKE_LATCH_2 : 0|1@1+ (1,0) [0|1] "" Host

BO_ 2487484419 BATT_boardIO_3: 1 Battery
 SG_ BATT_boardIO_DIS_OC_FLT_LA_3 : 5|1@1+ (1,0) [0|1] "" Host
 SG_ BATT_boardIO_L9963_FAULT_3 : 3|1@1+ (1,0) [0|1] "" Host
 SG_ BATT_boardIO_IL_WAKE_LATCH_3 : 2|1@1+ (1,0) [0|1] "" Host
 SG_ BATT_boardIO_IH_WAKE_LATCH_3 : 1|1@1+ (1,0) [0|1] "" Host
 SG_ BATT_boardIO_CAN_WAKE_LATCH_3 : 0|1@1+ (1,0) [0|1] "" Host

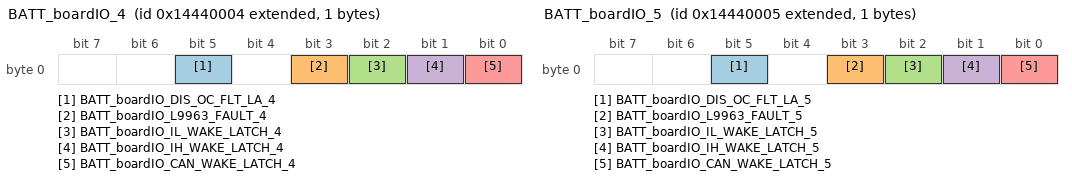
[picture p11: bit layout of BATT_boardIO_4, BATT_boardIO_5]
BO_ 2487484420 BATT_boardIO_4: 1 Battery
 SG_ BATT_boardIO_DIS_OC_FLT_LA_4 : 5|1@1+ (1,0) [0|1] "" Host
 SG_ BATT_boardIO_L9963_FAULT_4 : 3|1@1+ (1,0) [0|1] "" Host
 SG_ BATT_boardIO_IL_WAKE_LATCH_4 : 2|1@1+ (1,0) [0|1] "" Host
 SG_ BATT_boardIO_IH_WAKE_LATCH_4 : 1|1@1+ (1,0) [0|1] "" Host
 SG_ BATT_boardIO_CAN_WAKE_LATCH_4 : 0|1@1+ (1,0) [0|1] "" Host

BO_ 2487484421 BATT_boardIO_5: 1 Battery
 SG_ BATT_boardIO_DIS_OC_FLT_LA_5 : 5|1@1+ (1,0) [0|1] "" Host
 SG_ BATT_boardIO_L9963_FAULT_5 : 3|1@1+ (1,0) [0|1] "" Host
 SG_ BATT_boardIO_IL_WAKE_LATCH_5 : 2|1@1+ (1,0) [0|1] "" Host
 SG_ BATT_boardIO_IH_WAKE_LATCH_5 : 1|1@1+ (1,0) [0|1] "" Host
 SG_ BATT_boardIO_CAN_WAKE_LATCH_5 : 0|1@1+ (1,0) [0|1] "" Host

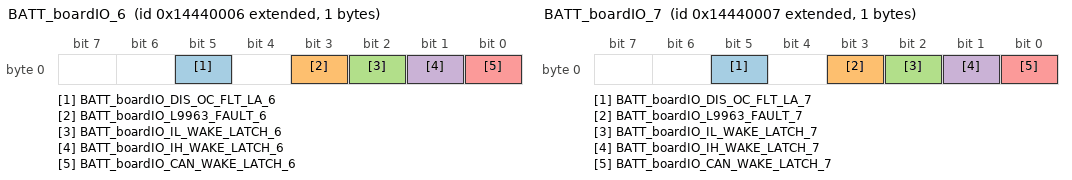
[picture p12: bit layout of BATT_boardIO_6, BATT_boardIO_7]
BO_ 2487484422 BATT_boardIO_6: 1 Battery
 SG_ BATT_boardIO_DIS_OC_FLT_LA_6 : 5|1@1+ (1,0) [0|1] "" Host
 SG_ BATT_boardIO_L9963_FAULT_6 : 3|1@1+ (1,0) [0|1] "" Host
 SG_ BATT_boardIO_IL_WAKE_LATCH_6 : 2|1@1+ (1,0) [0|1] "" Host
 SG_ BATT_boardIO_IH_WAKE_LATCH_6 : 1|1@1+ (1,0) [0|1] "" Host
 SG_ BATT_boardIO_CAN_WAKE_LATCH_6 : 0|1@1+ (1,0) [0|1] "" Host

BO_ 2487484423 BATT_boardIO_7: 1 Battery
 SG_ BATT_boardIO_DIS_OC_FLT_LA_7 : 5|1@1+ (1,0) [0|1] "" Host
 SG_ BATT_boardIO_L9963_FAULT_7 : 3|1@1+ (1,0) [0|1] "" Host
 SG_ BATT_boardIO_IL_WAKE_LATCH_7 : 2|1@1+ (1,0) [0|1] "" Host
 SG_ BATT_boardIO_IH_WAKE_LATCH_7 : 1|1@1+ (1,0) [0|1] "" Host
 SG_ BATT_boardIO_CAN_WAKE_LATCH_7 : 0|1@1+ (1,0) [0|1] "" Host

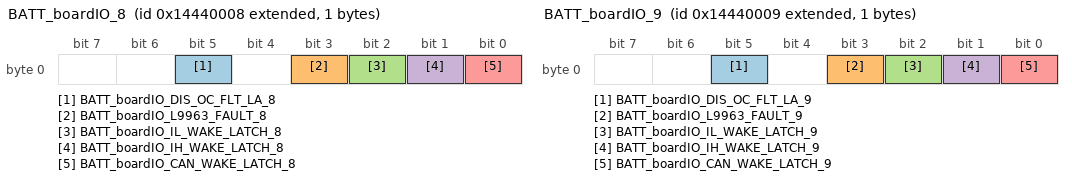
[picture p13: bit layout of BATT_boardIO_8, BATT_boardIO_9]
BO_ 2487484424 BATT_boardIO_8: 1 Battery
 SG_ BATT_boardIO_DIS_OC_FLT_LA_8 : 5|1@1+ (1,0) [0|1] "" Host
 SG_ BATT_boardIO_L9963_FAULT_8 : 3|1@1+ (1,0) [0|1] "" Host
 SG_ BATT_boardIO_IL_WAKE_LATCH_8 : 2|1@1+ (1,0) [0|1] "" Host
 SG_ BATT_boardIO_IH_WAKE_LATCH_8 : 1|1@1+ (1,0) [0|1] "" Host
 SG_ BATT_boardIO_CAN_WAKE_LATCH_8 : 0|1@1+ (1,0) [0|1] "" Host

BO_ 2487484425 BATT_boardIO_9: 1 Battery
 SG_ BATT_boardIO_DIS_OC_FLT_LA_9 : 5|1@1+ (1,0) [0|1] "" Host
 SG_ BATT_boardIO_L9963_FAULT_9 : 3|1@1+ (1,0) [0|1] "" Host
 SG_ BATT_boardIO_IL_WAKE_LATCH_9 : 2|1@1+ (1,0) [0|1] "" Host
 SG_ BATT_boardIO_IH_WAKE_LATCH_9 : 1|1@1+ (1,0) [0|1] "" Host
 SG_ BATT_boardIO_CAN_WAKE_LATCH_9 : 0|1@1+ (1,0) [0|1] "" Host

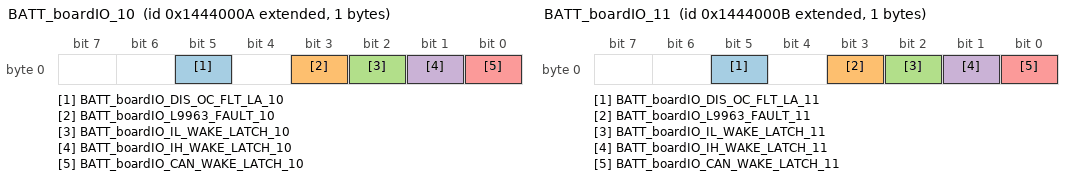
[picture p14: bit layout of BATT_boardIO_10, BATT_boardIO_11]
BO_ 2487484426 BATT_boardIO_10: 1 Battery
 SG_ BATT_boardIO_DIS_OC_FLT_LA_10 : 5|1@1+ (1,0) [0|1] "" Host
 SG_ BATT_boardIO_L9963_FAULT_10 : 3|1@1+ (1,0) [0|1] "" Host
 SG_ BATT_boardIO_IL_WAKE_LATCH_10 : 2|1@1+ (1,0) [0|1] "" Host
 SG_ BATT_boardIO_IH_WAKE_LATCH_10 : 1|1@1+ (1,0) [0|1] "" Host
 SG_ BATT_boardIO_CAN_WAKE_LATCH_10 : 0|1@1+ (1,0) [0|1] "" Host

BO_ 2487484427 BATT_boardIO_11: 1 Battery
 SG_ BATT_boardIO_DIS_OC_FLT_LA_11 : 5|1@1+ (1,0) [0|1] "" Host
 SG_ BATT_boardIO_L9963_FAULT_11 : 3|1@1+ (1,0) [0|1] "" Host
 SG_ BATT_boardIO_IL_WAKE_LATCH_11 : 2|1@1+ (1,0) [0|1] "" Host
 SG_ BATT_boardIO_IH_WAKE_LATCH_11 : 1|1@1+ (1,0) [0|1] "" Host
 SG_ BATT_boardIO_CAN_WAKE_LATCH_11 : 0|1@1+ (1,0) [0|1] "" Host

BO_ 2508193792 BATT_bootUp_0: 6 Battery
 SG_ BATT_bootloaderRevision_bootup_0 : 40|8@1+ (1,0) [0|255] "" Host
 SG_ BATT_bootloaderMinor_bootup_0 : 32|8@1+ (1,0) [0|255] "" Host
 SG_ BATT_bootloaderMajor_bootup_0 : 24|8@1+ (1,0) [0|255] "" Host
 SG_ BATT_appRevision_bootup_0 : 16|8@1+ (1,0) [0|255] "" Host
 SG_ BATT_appMinor_bootup_0 : 8|8@1+ (1,0) [0|255] "" Host
 SG_ BATT_appMajor_bootup_0 : 0|8@1+ (1,0) [0|255] "" Host

BO_ 2508193793 BATT_bootUp_1: 6 Battery
 SG_ BATT_bootloaderRevision_bootup_1 : 40|8@1+ (1,0) [0|255] "" Host
 SG_ BATT_bootloaderMinor_bootup_1 : 32|8@1+ (1,0) [0|255] "" Host
 SG_ BATT_bootloaderMajor_bootup_1 : 24|8@1+ (1,0) [0|255] "" Host
 SG_ BATT_appRevision_bootup_1 : 16|8@1+ (1,0) [0|255] "" Host
 SG_ BATT_appMinor_bootup_1 : 8|8@1+ (1,0) [0|255] "" Host
 SG_ BATT_appMajor_bootup_1 : 0|8@1+ (1,0) [0|255] "" Host

BO_ 2508193794 BATT_bootUp_2: 6 Battery
 SG_ BATT_bootloaderRevision_bootup_2 : 40|8@1+ (1,0) [0|255] "" Host
 SG_ BATT_bootloaderMinor_bootup_2 : 32|8@1+ (1,0) [0|255] "" Host
 SG_ BATT_bootloaderMajor_bootup_2 : 24|8@1+ (1,0) [0|255] "" Host
 SG_ BATT_appRevision_bootup_2 : 16|8@1+ (1,0) [0|255] "" Host
 SG_ BATT_appMinor_bootup_2 : 8|8@1+ (1,0) [0|255] "" Host
 SG_ BATT_appMajor_bootup_2 : 0|8@1+ (1,0) [0|255] "" Host

BO_ 2508193795 BATT_bootUp_3: 6 Battery
 SG_ BATT_bootloaderRevision_bootup_3 : 40|8@1+ (1,0) [0|255] "" Host
 SG_ BATT_bootloaderMinor_bootup_3 : 32|8@1+ (1,0) [0|255] "" Host
 SG_ BATT_bootloaderMajor_bootup_3 : 24|8@1+ (1,0) [0|255] "" Host
 SG_ BATT_appRevision_bootup_3 : 16|8@1+ (1,0) [0|255] "" Host
 SG_ BATT_appMinor_bootup_3 : 8|8@1+ (1,0) [0|255] "" Host
 SG_ BATT_appMajor_bootup_3 : 0|8@1+ (1,0) [0|255] "" Host

BO_ 2508193796 BATT_bootUp_4: 6 Battery
 SG_ BATT_bootloaderRevision_bootup_4 : 40|8@1+ (1,0) [0|255] "" Host
 SG_ BATT_bootloaderMinor_bootup_4 : 32|8@1+ (1,0) [0|255] "" Host
 SG_ BATT_bootloaderMajor_bootup_4 : 24|8@1+ (1,0) [0|255] "" Host
 SG_ BATT_appRevision_bootup_4 : 16|8@1+ (1,0) [0|255] "" Host
 SG_ BATT_appMinor_bootup_4 : 8|8@1+ (1,0) [0|255] "" Host
 SG_ BATT_appMajor_bootup_4 : 0|8@1+ (1,0) [0|255] "" Host

BO_ 2508193797 BATT_bootUp_5: 6 Battery
 SG_ BATT_bootloaderRevision_bootup_5 : 40|8@1+ (1,0) [0|255] "" Host
 SG_ BATT_bootloaderMinor_bootup_5 : 32|8@1+ (1,0) [0|255] "" Host
 SG_ BATT_bootloaderMajor_bootup_5 : 24|8@1+ (1,0) [0|255] "" Host
 SG_ BATT_appRevision_bootup_5 : 16|8@1+ (1,0) [0|255] "" Host
 SG_ BATT_appMinor_bootup_5 : 8|8@1+ (1,0) [0|255] "" Host
 SG_ BATT_appMajor_bootup_5 : 0|8@1+ (1,0) [0|255] "" Host

BO_ 2508193798 BATT_bootUp_6: 6 Battery
 SG_ BATT_bootloaderRevision_bootup_6 : 40|8@1+ (1,0) [0|255] "" Host
 SG_ BATT_bootloaderMinor_bootup_6 : 32|8@1+ (1,0) [0|255] "" Host
 SG_ BATT_bootloaderMajor_bootup_6 : 24|8@1+ (1,0) [0|255] "" Host
 SG_ BATT_appRevision_bootup_6 : 16|8@1+ (1,0) [0|255] "" Host
 SG_ BATT_appMinor_bootup_6 : 8|8@1+ (1,0) [0|255] "" Host
 SG_ BATT_appMajor_bootup_6 : 0|8@1+ (1,0) [0|255] "" Host

BO_ 2508193799 BATT_bootUp_7: 6 Battery
 SG_ BATT_bootloaderRevision_bootup_7 : 40|8@1+ (1,0) [0|255] "" Host
 SG_ BATT_bootloaderMinor_bootup_7 : 32|8@1+ (1,0) [0|255] "" Host
 SG_ BATT_bootloaderMajor_bootup_7 : 24|8@1+ (1,0) [0|255] "" Host
 SG_ BATT_appRevision_bootup_7 : 16|8@1+ (1,0) [0|255] "" Host
 SG_ BATT_appMinor_bootup_7 : 8|8@1+ (1,0) [0|255] "" Host
 SG_ BATT_appMajor_bootup_7 : 0|8@1+ (1,0) [0|255] "" Host

BO_ 2508193800 BATT_bootUp_8: 6 Battery
 SG_ BATT_bootloaderRevision_bootup_8 : 40|8@1+ (1,0) [0|255] "" Host
 SG_ BATT_bootloaderMinor_bootup_8 : 32|8@1+ (1,0) [0|255] "" Host
 SG_ BATT_bootloaderMajor_bootup_8 : 24|8@1+ (1,0) [0|255] "" Host
 SG_ BATT_appRevision_bootup_8 : 16|8@1+ (1,0) [0|255] "" Host
 SG_ BATT_appMinor_bootup_8 : 8|8@1+ (1,0) [0|255] "" Host
 SG_ BATT_appMajor_bootup_8 : 0|8@1+ (1,0) [0|255] "" Host

BO_ 2508193801 BATT_bootUp_9: 6 Battery
 SG_ BATT_bootloaderRevision_bootup_9 : 40|8@1+ (1,0) [0|255] "" Host
 SG_ BATT_bootloaderMinor_bootup_9 : 32|8@1+ (1,0) [0|255] "" Host
 SG_ BATT_bootloaderMajor_bootup_9 : 24|8@1+ (1,0) [0|255] "" Host
 SG_ BATT_appRevision_bootup_9 : 16|8@1+ (1,0) [0|255] "" Host
 SG_ BATT_appMinor_bootup_9 : 8|8@1+ (1,0) [0|255] "" Host
 SG_ BATT_appMajor_bootup_9 : 0|8@1+ (1,0) [0|255] "" Host

BO_ 2508193802 BATT_bootUp_10: 6 Battery
 SG_ BATT_bootloaderRevision_bootup_10 : 40|8@1+ (1,0) [0|255] "" Host
 SG_ BATT_bootloaderMinor_bootup_10 : 32|8@1+ (1,0) [0|255] "" Host
 SG_ BATT_bootloaderMajor_bootup_10 : 24|8@1+ (1,0) [0|255] "" Host
 SG_ BATT_appRevision_bootup_10 : 16|8@1+ (1,0) [0|255] "" Host
 SG_ BATT_appMinor_bootup_10 : 8|8@1+ (1,0) [0|255] "" Host
 SG_ BATT_appMajor_bootup_10 : 0|8@1+ (1,0) [0|255] "" Host

BO_ 2508193803 BATT_bootUp_11: 6 Battery
 SG_ BATT_bootloaderRevision_bootup_11 : 40|8@1+ (1,0) [0|255] "" Host
 SG_ BATT_bootloaderMinor_bootup_11 : 32|8@1+ (1,0) [0|255] "" Host
 SG_ BATT_bootloaderMajor_bootup_11 : 24|8@1+ (1,0) [0|255] "" Host
 SG_ BATT_appRevision_bootup_11 : 16|8@1+ (1,0) [0|255] "" Host
 SG_ BATT_appMinor_bootup_11 : 8|8@1+ (1,0) [0|255] "" Host
 SG_ BATT_appMajor_bootup_11 : 0|8@1+ (1,0) [0|255] "" Host

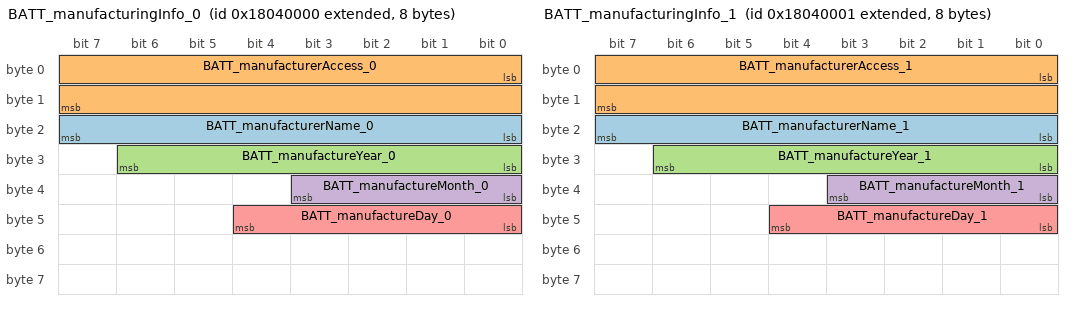
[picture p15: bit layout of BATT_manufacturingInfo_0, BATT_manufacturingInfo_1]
BO_ 2550398976 BATT_manufacturingInfo_0: 8 Battery
 SG_ BATT_manufacturerName_0 : 16|8@1+ (1,0) [0|255] "STRING" Host
 SG_ BATT_manufacturerAccess_0 : 0|16@1+ (1,0) [0|65535] "" Host
 SG_ BATT_manufactureYear_0 : 24|7@1+ (1,0) [0|127] "" Host
 SG_ BATT_manufactureMonth_0 : 32|4@1+ (1,0) [1|12] "" Host
 SG_ BATT_manufactureDay_0 : 40|5@1+ (1,0) [1|31] "" Host

BO_ 2550398977 BATT_manufacturingInfo_1: 8 Battery
 SG_ BATT_manufacturerName_1 : 16|8@1+ (1,0) [0|255] "STRING" Host
 SG_ BATT_manufacturerAccess_1 : 0|16@1+ (1,0) [0|65535] "" Host
 SG_ BATT_manufactureYear_1 : 24|7@1+ (1,0) [0|127] "" Host
 SG_ BATT_manufactureMonth_1 : 32|4@1+ (1,0) [1|12] "" Host
 SG_ BATT_manufactureDay_1 : 40|5@1+ (1,0) [1|31] "" Host

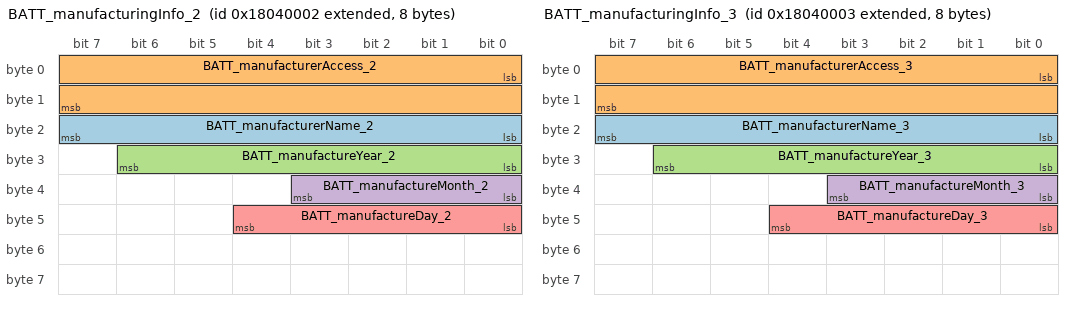
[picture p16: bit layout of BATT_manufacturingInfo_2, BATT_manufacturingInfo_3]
BO_ 2550398978 BATT_manufacturingInfo_2: 8 Battery
 SG_ BATT_manufacturerName_2 : 16|8@1+ (1,0) [0|255] "STRING" Host
 SG_ BATT_manufacturerAccess_2 : 0|16@1+ (1,0) [0|65535] "" Host
 SG_ BATT_manufactureYear_2 : 24|7@1+ (1,0) [0|127] "" Host
 SG_ BATT_manufactureMonth_2 : 32|4@1+ (1,0) [1|12] "" Host
 SG_ BATT_manufactureDay_2 : 40|5@1+ (1,0) [1|31] "" Host

BO_ 2550398979 BATT_manufacturingInfo_3: 8 Battery
 SG_ BATT_manufacturerName_3 : 16|8@1+ (1,0) [0|255] "STRING" Host
 SG_ BATT_manufacturerAccess_3 : 0|16@1+ (1,0) [0|65535] "" Host
 SG_ BATT_manufactureYear_3 : 24|7@1+ (1,0) [0|127] "" Host
 SG_ BATT_manufactureMonth_3 : 32|4@1+ (1,0) [1|12] "" Host
 SG_ BATT_manufactureDay_3 : 40|5@1+ (1,0) [1|31] "" Host

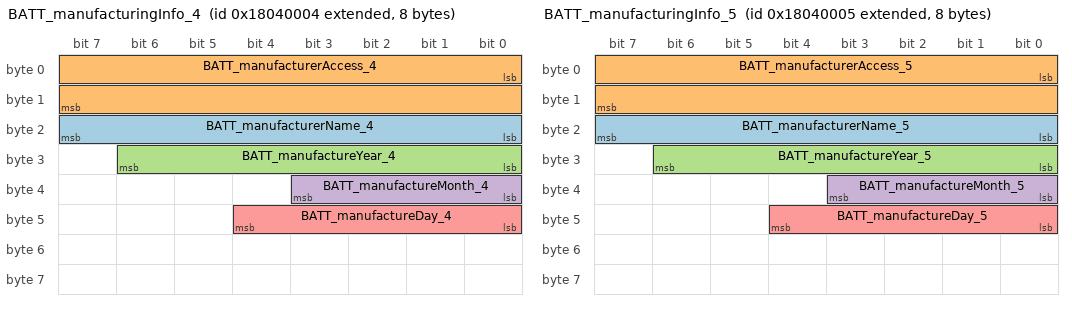
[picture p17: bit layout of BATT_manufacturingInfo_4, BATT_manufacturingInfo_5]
BO_ 2550398980 BATT_manufacturingInfo_4: 8 Battery
 SG_ BATT_manufacturerName_4 : 16|8@1+ (1,0) [0|255] "STRING" Host
 SG_ BATT_manufacturerAccess_4 : 0|16@1+ (1,0) [0|65535] "" Host
 SG_ BATT_manufactureYear_4 : 24|7@1+ (1,0) [0|127] "" Host
 SG_ BATT_manufactureMonth_4 : 32|4@1+ (1,0) [1|12] "" Host
 SG_ BATT_manufactureDay_4 : 40|5@1+ (1,0) [1|31] "" Host

BO_ 2550398981 BATT_manufacturingInfo_5: 8 Battery
 SG_ BATT_manufacturerName_5 : 16|8@1+ (1,0) [0|255] "STRING" Host
 SG_ BATT_manufacturerAccess_5 : 0|16@1+ (1,0) [0|65535] "" Host
 SG_ BATT_manufactureYear_5 : 24|7@1+ (1,0) [0|127] "" Host
 SG_ BATT_manufactureMonth_5 : 32|4@1+ (1,0) [1|12] "" Host
 SG_ BATT_manufactureDay_5 : 40|5@1+ (1,0) [1|31] "" Host

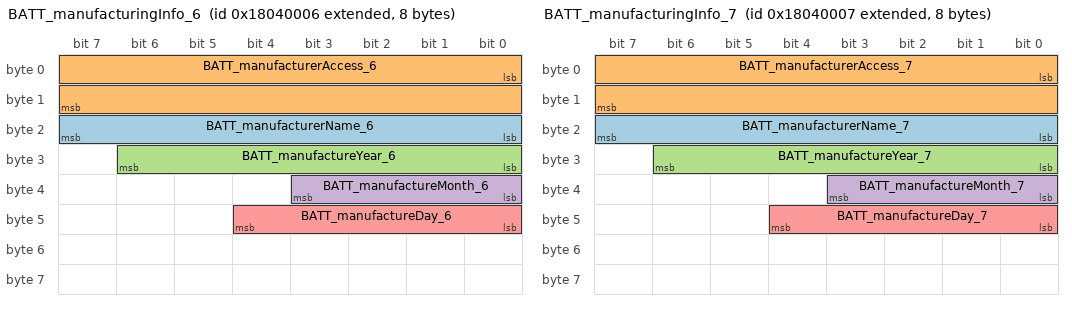
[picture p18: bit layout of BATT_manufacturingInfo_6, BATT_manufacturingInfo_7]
BO_ 2550398982 BATT_manufacturingInfo_6: 8 Battery
 SG_ BATT_manufacturerName_6 : 16|8@1+ (1,0) [0|255] "STRING" Host
 SG_ BATT_manufacturerAccess_6 : 0|16@1+ (1,0) [0|65535] "" Host
 SG_ BATT_manufactureYear_6 : 24|7@1+ (1,0) [0|127] "" Host
 SG_ BATT_manufactureMonth_6 : 32|4@1+ (1,0) [1|12] "" Host
 SG_ BATT_manufactureDay_6 : 40|5@1+ (1,0) [1|31] "" Host

BO_ 2550398983 BATT_manufacturingInfo_7: 8 Battery
 SG_ BATT_manufacturerName_7 : 16|8@1+ (1,0) [0|255] "STRING" Host
 SG_ BATT_manufacturerAccess_7 : 0|16@1+ (1,0) [0|65535] "" Host
 SG_ BATT_manufactureYear_7 : 24|7@1+ (1,0) [0|127] "" Host
 SG_ BATT_manufactureMonth_7 : 32|4@1+ (1,0) [1|12] "" Host
 SG_ BATT_manufactureDay_7 : 40|5@1+ (1,0) [1|31] "" Host

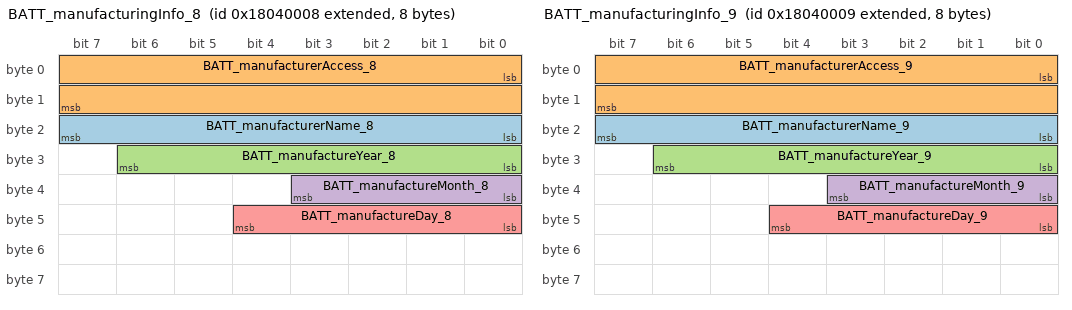
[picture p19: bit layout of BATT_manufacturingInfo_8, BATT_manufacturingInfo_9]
BO_ 2550398984 BATT_manufacturingInfo_8: 8 Battery
 SG_ BATT_manufacturerName_8 : 16|8@1+ (1,0) [0|255] "STRING" Host
 SG_ BATT_manufacturerAccess_8 : 0|16@1+ (1,0) [0|65535] "" Host
 SG_ BATT_manufactureYear_8 : 24|7@1+ (1,0) [0|127] "" Host
 SG_ BATT_manufactureMonth_8 : 32|4@1+ (1,0) [1|12] "" Host
 SG_ BATT_manufactureDay_8 : 40|5@1+ (1,0) [1|31] "" Host

BO_ 2550398985 BATT_manufacturingInfo_9: 8 Battery
 SG_ BATT_manufacturerName_9 : 16|8@1+ (1,0) [0|255] "STRING" Host
 SG_ BATT_manufacturerAccess_9 : 0|16@1+ (1,0) [0|65535] "" Host
 SG_ BATT_manufactureYear_9 : 24|7@1+ (1,0) [0|127] "" Host
 SG_ BATT_manufactureMonth_9 : 32|4@1+ (1,0) [1|12] "" Host
 SG_ BATT_manufactureDay_9 : 40|5@1+ (1,0) [1|31] "" Host

BO_ 2550398986 BATT_manufacturingInfo_10: 8 Battery
 SG_ BATT_manufacturerName_10 : 16|8@1+ (1,0) [0|255] "STRING" Host
 SG_ BATT_manufacturerAccess_10 : 0|16@1+ (1,0) [0|65535] "" Host
 SG_ BATT_manufactureYear_10 : 24|7@1+ (1,0) [0|127] "" Host
 SG_ BATT_manufactureMonth_10 : 32|4@1+ (1,0) [1|12] "" Host
 SG_ BATT_manufactureDay_10 : 40|5@1+ (1,0) [1|31] "" Host

BO_ 2550398987 BATT_manufacturingInfo_11: 8 Battery
 SG_ BATT_manufacturerName_11 : 16|8@1+ (1,0) [0|255] "STRING" Host
 SG_ BATT_manufacturerAccess_11 : 0|16@1+ (1,0) [0|65535] "" Host
 SG_ BATT_manufactureYear_11 : 24|7@1+ (1,0) [0|127] "" Host
 SG_ BATT_manufactureMonth_11 : 32|4@1+ (1,0) [1|12] "" Host
 SG_ BATT_manufactureDay_11 : 40|5@1+ (1,0) [1|31] "" Host

BO_ 2550661120 BATT_deviceInfo_0: 8 Battery
 SG_ BATT_IGNLO_Status_0 : 13|2@1+ (1,0) [0|3] "" Battery,Host
 SG_ BATT_serialNumber_0 : 16|48@1+ (1,0) [0|281474976710655] "" Battery,Host
 SG_ BATT_expectedModule_0 : 8|4@1+ (1,0) [0|15] "" Battery,Host
 SG_ BATT_deviceChemistry_0 : 0|8@1+ (1,0) [0|255] "" Battery,Host

BO_ 2550661121 BATT_deviceInfo_1: 8 Battery
 SG_ BATT_IGNLO_Status_1 : 13|2@1+ (1,0) [0|3] "" Battery,Host
 SG_ BATT_serialNumber_1 : 16|48@1+ (1,0) [0|281474976710655] "" Battery,Host
 SG_ BATT_expectedModule_1 : 8|4@1+ (1,0) [0|15] "" Battery,Host
 SG_ BATT_deviceChemistry_1 : 0|8@1+ (1,0) [0|255] "" Battery,Host

BO_ 2550661122 BATT_deviceInfo_2: 8 Battery
 SG_ BATT_IGNLO_Status_2 : 13|2@1+ (1,0) [0|3] "" Battery,Host
 SG_ BATT_serialNumber_2 : 16|48@1+ (1,0) [0|281474976710655] "" Battery,Host
 SG_ BATT_expectedModule_2 : 8|4@1+ (1,0) [0|15] "" Battery,Host
 SG_ BATT_deviceChemistry_2 : 0|8@1+ (1,0) [0|255] "" Battery,Host

BO_ 2550661123 BATT_deviceInfo_3: 8 Battery
 SG_ BATT_IGNLO_Status_3 : 13|2@1+ (1,0) [0|3] "" Battery,Host
 SG_ BATT_serialNumber_3 : 16|48@1+ (1,0) [0|281474976710655] "" Battery,Host
 SG_ BATT_expectedModule_3 : 8|4@1+ (1,0) [0|15] "" Battery,Host
 SG_ BATT_deviceChemistry_3 : 0|8@1+ (1,0) [0|255] "" Battery,Host

BO_ 2550661124 BATT_deviceInfo_4: 8 Battery
 SG_ BATT_IGNLO_Status_4 : 13|2@1+ (1,0) [0|3] "" Battery,Host
 SG_ BATT_serialNumber_4 : 16|48@1+ (1,0) [0|281474976710655] "" Battery,Host
 SG_ BATT_expectedModule_4 : 8|4@1+ (1,0) [0|15] "" Battery,Host
 SG_ BATT_deviceChemistry_4 : 0|8@1+ (1,0) [0|255] "" Battery,Host

BO_ 2550661125 BATT_deviceInfo_5: 8 Battery
 SG_ BATT_IGNLO_Status_5 : 13|2@1+ (1,0) [0|3] "" Battery,Host
 SG_ BATT_serialNumber_5 : 16|48@1+ (1,0) [0|281474976710655] "" Battery,Host
 SG_ BATT_expectedModule_5 : 8|4@1+ (1,0) [0|15] "" Battery,Host
 SG_ BATT_deviceChemistry_5 : 0|8@1+ (1,0) [0|255] "" Battery,Host

BO_ 2550661126 BATT_deviceInfo_6: 8 Battery
 SG_ BATT_IGNLO_Status_6 : 13|2@1+ (1,0) [0|3] "" Battery,Host
 SG_ BATT_serialNumber_6 : 16|48@1+ (1,0) [0|281474976710655] "" Battery,Host
 SG_ BATT_expectedModule_6 : 8|4@1+ (1,0) [0|15] "" Battery,Host
 SG_ BATT_deviceChemistry_6 : 0|8@1+ (1,0) [0|255] "" Battery,Host

BO_ 2550661127 BATT_deviceInfo_7: 8 Battery
 SG_ BATT_IGNLO_Status_7 : 13|2@1+ (1,0) [0|3] "" Battery,Host
 SG_ BATT_serialNumber_7 : 16|48@1+ (1,0) [0|281474976710655] "" Battery,Host
 SG_ BATT_expectedModule_7 : 8|4@1+ (1,0) [0|15] "" Battery,Host
 SG_ BATT_deviceChemistry_7 : 0|8@1+ (1,0) [0|255] "" Battery,Host

BO_ 2550661128 BATT_deviceInfo_8: 8 Battery
 SG_ BATT_IGNLO_Status_8 : 13|2@1+ (1,0) [0|3] "" Battery,Host
 SG_ BATT_serialNumber_8 : 16|48@1+ (1,0) [0|281474976710655] "" Battery,Host
 SG_ BATT_expectedModule_8 : 8|4@1+ (1,0) [0|15] "" Battery,Host
 SG_ BATT_deviceChemistry_8 : 0|8@1+ (1,0) [0|255] "" Battery,Host

BO_ 2550661129 BATT_deviceInfo_9: 8 Battery
 SG_ BATT_IGNLO_Status_9 : 13|2@1+ (1,0) [0|3] "" Battery,Host
 SG_ BATT_serialNumber_9 : 16|48@1+ (1,0) [0|281474976710655] "" Battery,Host
 SG_ BATT_expectedModule_9 : 8|4@1+ (1,0) [0|15] "" Battery,Host
 SG_ BATT_deviceChemistry_9 : 0|8@1+ (1,0) [0|255] "" Battery,Host

BO_ 2550661130 BATT_deviceInfo_10: 8 Battery
 SG_ BATT_IGNLO_Status_10 : 13|2@1+ (1,0) [0|3] "" Battery,Host
 SG_ BATT_serialNumber_10 : 16|48@1+ (1,0) [0|281474976710655] "" Battery,Host
 SG_ BATT_expectedModule_10 : 8|4@1+ (1,0) [0|15] "" Battery,Host
 SG_ BATT_deviceChemistry_10 : 0|8@1+ (1,0) [0|255] "" Battery,Host

BO_ 2550661131 BATT_deviceInfo_11: 8 Battery
 SG_ BATT_IGNLO_Status_11 : 13|2@1+ (1,0) [0|3] "" Battery,Host
 SG_ BATT_serialNumber_11 : 16|48@1+ (1,0) [0|281474976710655] "" Battery,Host
 SG_ BATT_expectedModule_11 : 8|4@1+ (1,0) [0|15] "" Battery,Host
 SG_ BATT_deviceChemistry_11 : 0|8@1+ (1,0) [0|255] "" Battery,Host

BO_ 2551447552 BATT_rtcTimeDate_0: 8 Battery
 SG_ BATT_rtcSeconds_0 : 48|8@1+ (1,0) [0|59] "" Host
 SG_ BATT_rtcMinutes_0 : 40|8@1+ (1,0) [0|59] "" Host
 SG_ BATT_rtcHour_0 : 32|8@1+ (1,0) [0|23] "" Host
 SG_ BATT_rtcDay_0 : 24|8@1+ (1,0) [1|31] "" Host
 SG_ BATT_rtcMonth_0 : 16|8@1+ (1,0) [1|12] "" Host
 SG_ BATT_rtcYear_0 : 0|16@1+ (1,0) [2016|2099] "" Host

BO_ 2551447553 BATT_rtcTimeDate_1: 8 Battery
 SG_ BATT_rtcSeconds_1 : 48|8@1+ (1,0) [0|59] "" Host
 SG_ BATT_rtcMinutes_1 : 40|8@1+ (1,0) [0|59] "" Host
 SG_ BATT_rtcHour_1 : 32|8@1+ (1,0) [0|23] "" Host
 SG_ BATT_rtcDay_1 : 24|8@1+ (1,0) [1|31] "" Host
 SG_ BATT_rtcMonth_1 : 16|8@1+ (1,0) [1|12] "" Host
 SG_ BATT_rtcYear_1 : 0|16@1+ (1,0) [2016|2099] "" Host

BO_ 2551447554 BATT_rtcTimeDate_2: 8 Battery
 SG_ BATT_rtcSeconds_2 : 48|8@1+ (1,0) [0|59] "" Host
 SG_ BATT_rtcMinutes_2 : 40|8@1+ (1,0) [0|59] "" Host
 SG_ BATT_rtcHour_2 : 32|8@1+ (1,0) [0|23] "" Host
 SG_ BATT_rtcDay_2 : 24|8@1+ (1,0) [1|31] "" Host
 SG_ BATT_rtcMonth_2 : 16|8@1+ (1,0) [1|12] "" Host
 SG_ BATT_rtcYear_2 : 0|16@1+ (1,0) [2016|2099] "" Host

BO_ 2551447555 BATT_rtcTimeDate_3: 8 Battery
 SG_ BATT_rtcSeconds_3 : 48|8@1+ (1,0) [0|59] "" Host
 SG_ BATT_rtcMinutes_3 : 40|8@1+ (1,0) [0|59] "" Host
 SG_ BATT_rtcHour_3 : 32|8@1+ (1,0) [0|23] "" Host
 SG_ BATT_rtcDay_3 : 24|8@1+ (1,0) [1|31] "" Host
 SG_ BATT_rtcMonth_3 : 16|8@1+ (1,0) [1|12] "" Host
 SG_ BATT_rtcYear_3 : 0|16@1+ (1,0) [2016|2099] "" Host

BO_ 2551447556 BATT_rtcTimeDate_4: 8 Battery
 SG_ BATT_rtcSeconds_4 : 48|8@1+ (1,0) [0|59] "" Host
 SG_ BATT_rtcMinutes_4 : 40|8@1+ (1,0) [0|59] "" Host
 SG_ BATT_rtcHour_4 : 32|8@1+ (1,0) [0|23] "" Host
 SG_ BATT_rtcDay_4 : 24|8@1+ (1,0) [1|31] "" Host
 SG_ BATT_rtcMonth_4 : 16|8@1+ (1,0) [1|12] "" Host
 SG_ BATT_rtcYear_4 : 0|16@1+ (1,0) [2016|2099] "" Host

BO_ 2551447557 BATT_rtcTimeDate_5: 8 Battery
 SG_ BATT_rtcSeconds_5 : 48|8@1+ (1,0) [0|59] "" Host
 SG_ BATT_rtcMinutes_5 : 40|8@1+ (1,0) [0|59] "" Host
 SG_ BATT_rtcHour_5 : 32|8@1+ (1,0) [0|23] "" Host
 SG_ BATT_rtcDay_5 : 24|8@1+ (1,0) [1|31] "" Host
 SG_ BATT_rtcMonth_5 : 16|8@1+ (1,0) [1|12] "" Host
 SG_ BATT_rtcYear_5 : 0|16@1+ (1,0) [2016|2099] "" Host

BO_ 2551447558 BATT_rtcTimeDate_6: 8 Battery
 SG_ BATT_rtcSeconds_6 : 48|8@1+ (1,0) [0|59] "" Host
 SG_ BATT_rtcMinutes_6 : 40|8@1+ (1,0) [0|59] "" Host
 SG_ BATT_rtcHour_6 : 32|8@1+ (1,0) [0|23] "" Host
 SG_ BATT_rtcDay_6 : 24|8@1+ (1,0) [1|31] "" Host
 SG_ BATT_rtcMonth_6 : 16|8@1+ (1,0) [1|12] "" Host
 SG_ BATT_rtcYear_6 : 0|16@1+ (1,0) [2016|2099] "" Host

BO_ 2551447559 BATT_rtcTimeDate_7: 8 Battery
 SG_ BATT_rtcSeconds_7 : 48|8@1+ (1,0) [0|59] "" Host
 SG_ BATT_rtcMinutes_7 : 40|8@1+ (1,0) [0|59] "" Host
 SG_ BATT_rtcHour_7 : 32|8@1+ (1,0) [0|23] "" Host
 SG_ BATT_rtcDay_7 : 24|8@1+ (1,0) [1|31] "" Host
 SG_ BATT_rtcMonth_7 : 16|8@1+ (1,0) [1|12] "" Host
 SG_ BATT_rtcYear_7 : 0|16@1+ (1,0) [2016|2099] "" Host

BO_ 2551447560 BATT_rtcTimeDate_8: 8 Battery
 SG_ BATT_rtcSeconds_8 : 48|8@1+ (1,0) [0|59] "" Host
 SG_ BATT_rtcMinutes_8 : 40|8@1+ (1,0) [0|59] "" Host
 SG_ BATT_rtcHour_8 : 32|8@1+ (1,0) [0|23] "" Host
 SG_ BATT_rtcDay_8 : 24|8@1+ (1,0) [1|31] "" Host
 SG_ BATT_rtcMonth_8 : 16|8@1+ (1,0) [1|12] "" Host
 SG_ BATT_rtcYear_8 : 0|16@1+ (1,0) [2016|2099] "" Host

BO_ 2551447561 BATT_rtcTimeDate_9: 8 Battery
 SG_ BATT_rtcSeconds_9 : 48|8@1+ (1,0) [0|59] "" Host
 SG_ BATT_rtcMinutes_9 : 40|8@1+ (1,0) [0|59] "" Host
 SG_ BATT_rtcHour_9 : 32|8@1+ (1,0) [0|23] "" Host
 SG_ BATT_rtcDay_9 : 24|8@1+ (1,0) [1|31] "" Host
 SG_ BATT_rtcMonth_9 : 16|8@1+ (1,0) [1|12] "" Host
 SG_ BATT_rtcYear_9 : 0|16@1+ (1,0) [2016|2099] "" Host

BO_ 2551447562 BATT_rtcTimeDate_10: 8 Battery
 SG_ BATT_rtcSeconds_10 : 48|8@1+ (1,0) [0|59] "" Host
 SG_ BATT_rtcMinutes_10 : 40|8@1+ (1,0) [0|59] "" Host
 SG_ BATT_rtcHour_10 : 32|8@1+ (1,0) [0|23] "" Host
 SG_ BATT_rtcDay_10 : 24|8@1+ (1,0) [1|31] "" Host
 SG_ BATT_rtcMonth_10 : 16|8@1+ (1,0) [1|12] "" Host
 SG_ BATT_rtcYear_10 : 0|16@1+ (1,0) [2016|2099] "" Host

BO_ 2551447563 BATT_rtcTimeDate_11: 8 Battery
 SG_ BATT_rtcSeconds_11 : 48|8@1+ (1,0) [0|59] "" Host
 SG_ BATT_rtcMinutes_11 : 40|8@1+ (1,0) [0|59] "" Host
 SG_ BATT_rtcHour_11 : 32|8@1+ (1,0) [0|23] "" Host
 SG_ BATT_rtcDay_11 : 24|8@1+ (1,0) [1|31] "" Host
 SG_ BATT_rtcMonth_11 : 16|8@1+ (1,0) [1|12] "" Host
 SG_ BATT_rtcYear_11 : 0|16@1+ (1,0) [2016|2099] "" Host

CM_ BO_ 2224291846 "Battery min-max data";
CM_ SG_ 2224291846 BATT_tModuleMaxID_6 "ID of maximum Battery temperature ";
CM_ SG_ 2224291846 BATT_tModuleMinID_6 "ID of minimum Battery temperature ";
CM_ SG_ 2224291846 BATT_vBrickMaxID_6 "ID of maximum brick voltage ";
CM_ SG_ 2224291846 BATT_vBrickMinID_6 "ID of minimum brick voltage ";
CM_ SG_ 2224291846 BATT_tModuleMax_6 "Maximum Battery temperature";
CM_ SG_ 2224291846 BATT_tModuleMin_6 "Minimum Battery temperature";
CM_ SG_ 2224291846 BATT_vBrickMin_6 "Minimum brick voltage ";
CM_ SG_ 2224291846 BATT_vBrickMax_6 "Maximum brick voltage ";
CM_ BO_ 2224291847 "Battery min-max data";
CM_ SG_ 2224291847 BATT_tModuleMaxID_7 "ID of maximum Battery temperature ";
CM_ SG_ 2224291847 BATT_tModuleMinID_7 "ID of minimum Battery temperature ";
CM_ SG_ 2224291847 BATT_vBrickMaxID_7 "ID of maximum brick voltage ";
CM_ SG_ 2224291847 BATT_vBrickMinID_7 "ID of minimum brick voltage ";
CM_ SG_ 2224291847 BATT_tModuleMax_7 "Maximum Battery temperature";
CM_ SG_ 2224291847 BATT_tModuleMin_7 "Minimum Battery temperature";
CM_ SG_ 2224291847 BATT_vBrickMin_7 "Minimum brick voltage ";
CM_ SG_ 2224291847 BATT_vBrickMax_7 "Maximum brick voltage ";
CM_ BO_ 2224291848 "Battery min-max data";
CM_ SG_ 2224291848 BATT_tModuleMaxID_8 "ID of maximum Battery temperature ";
CM_ SG_ 2224291848 BATT_tModuleMinID_8 "ID of minimum Battery temperature ";
CM_ SG_ 2224291848 BATT_vBrickMaxID_8 "ID of maximum brick voltage ";
CM_ SG_ 2224291848 BATT_vBrickMinID_8 "ID of minimum brick voltage ";
CM_ SG_ 2224291848 BATT_tModuleMax_8 "Maximum Battery temperature";
CM_ SG_ 2224291848 BATT_tModuleMin_8 "Minimum Battery temperature";
CM_ SG_ 2224291848 BATT_vBrickMin_8 "Minimum brick voltage ";
CM_ SG_ 2224291848 BATT_vBrickMax_8 "Maximum brick voltage ";
CM_ BO_ 2224291849 "Battery min-max data";
CM_ SG_ 2224291849 BATT_tModuleMaxID_9 "ID of maximum Battery temperature ";
CM_ SG_ 2224291849 BATT_tModuleMinID_9 "ID of minimum Battery temperature ";
CM_ SG_ 2224291849 BATT_vBrickMaxID_9 "ID of maximum brick voltage ";
CM_ SG_ 2224291849 BATT_vBrickMinID_9 "ID of minimum brick voltage ";
CM_ SG_ 2224291849 BATT_tModuleMax_9 "Maximum Battery temperature";
CM_ SG_ 2224291849 BATT_tModuleMin_9 "Minimum Battery temperature";
CM_ SG_ 2224291849 BATT_vBrickMin_9 "Minimum brick voltage ";
CM_ SG_ 2224291849 BATT_vBrickMax_9 "Maximum brick voltage ";
CM_ BO_ 2224291850 "Battery min-max data";
CM_ SG_ 2224291850 BATT_tModuleMaxID_10 "ID of maximum Battery temperature ";
CM_ SG_ 2224291850 BATT_tModuleMinID_10 "ID of minimum Battery temperature ";
CM_ SG_ 2224291850 BATT_vBrickMaxID_10 "ID of maximum brick voltage ";
CM_ SG_ 2224291850 BATT_vBrickMinID_10 "ID of minimum brick voltage ";
CM_ SG_ 2224291850 BATT_tModuleMax_10 "Maximum Battery temperature";
CM_ SG_ 2224291850 BATT_tModuleMin_10 "Minimum Battery temperature";
CM_ SG_ 2224291850 BATT_vBrickMin_10 "Minimum brick voltage ";
CM_ SG_ 2224291850 BATT_vBrickMax_10 "Maximum brick voltage ";
CM_ BO_ 2224291851 "Battery min-max data";
CM_ SG_ 2224291851 BATT_tModuleMaxID_11 "ID of maximum Battery temperature ";
CM_ SG_ 2224291851 BATT_tModuleMinID_11 "ID of minimum Battery temperature ";
CM_ SG_ 2224291851 BATT_vBrickMaxID_11 "ID of maximum brick voltage ";
CM_ SG_ 2224291851 BATT_vBrickMinID_11 "ID of minimum brick voltage ";
CM_ SG_ 2224291851 BATT_tModuleMax_11 "Maximum Battery temperature";
CM_ SG_ 2224291851 BATT_tModuleMin_11 "Minimum Battery temperature";
CM_ SG_ 2224291851 BATT_vBrickMin_11 "Minimum brick voltage ";
CM_ SG_ 2224291851 BATT_vBrickMax_11 "Maximum brick voltage ";
CM_ BO_ 2232680448 "BMS application firmware versions
0 - 2 bytes = Application version
3 - 5 bytes = Bootloader version
6 - 7 bytes =  Build revision";
CM_ SG_ 2232680448 BATT_bootTotalFaultCnt_0 "Total Boot fault cnt ";
CM_ SG_ 2232680448 BATT_bootFaultCnt_0 "Boot fault cnt (block app jump from bootloader if cnt >=3)";
CM_ SG_ 2232680448 BATT_bootloaderRevision_0 "Revision bootloader version for BMS";
CM_ SG_ 2232680448 BATT_bootloaderMinor_0 "Minor bootloader version for BMS";
CM_ SG_ 2232680448 BATT_bootloaderMajor_0 "Major bootloader version for BMS";
CM_ SG_ 2232680448 BATT_appRevision_0 "Revision app version for BMS";
CM_ SG_ 2232680448 BATT_appMinor_0 "Minor app version for BMS";
CM_ SG_ 2232680448 BATT_appMajor_0 "Major app version for BMS";
CM_ BO_ 2232680449 "BMS application firmware versions
0 - 2 bytes = Application version
3 - 5 bytes = Bootloader version
6 - 7 bytes =  Build revision";
CM_ SG_ 2232680449 BATT_bootTotalFaultCnt_1 "Total Boot fault cnt ";
CM_ SG_ 2232680449 BATT_bootFaultCnt_1 "Boot fault cnt (block app jump from bootloader if cnt >=3)";
CM_ SG_ 2232680449 BATT_bootloaderRevision_1 "Revision bootloader version for BMS";
CM_ SG_ 2232680449 BATT_bootloaderMinor_1 "Minor bootloader version for BMS";
CM_ SG_ 2232680449 BATT_bootloaderMajor_1 "Major bootloader version for BMS";
CM_ SG_ 2232680449 BATT_appRevision_1 "Revision app version for BMS";
CM_ SG_ 2232680449 BATT_appMinor_1 "Minor app version for BMS";
CM_ SG_ 2232680449 BATT_appMajor_1 "Major app version for BMS";
CM_ BO_ 2232680450 "BMS application firmware versions
0 - 2 bytes = Application version
3 - 5 bytes = Bootloader version
6 - 7 bytes =  Build revision";
CM_ SG_ 2232680450 BATT_bootTotalFaultCnt_2 "Total Boot fault cnt ";
CM_ SG_ 2232680450 BATT_bootFaultCnt_2 "Boot fault cnt (block app jump from bootloader if cnt >=3)";
CM_ SG_ 2232680450 BATT_bootloaderRevision_2 "Revision bootloader version for BMS";
CM_ SG_ 2232680450 BATT_bootloaderMinor_2 "Minor bootloader version for BMS";
CM_ SG_ 2232680450 BATT_bootloaderMajor_2 "Major bootloader version for BMS";
CM_ SG_ 2232680450 BATT_appRevision_2 "Revision app version for BMS";
CM_ SG_ 2232680450 BATT_appMinor_2 "Minor app version for BMS";
CM_ SG_ 2232680450 BATT_appMajor_2 "Major app version for BMS";
CM_ BO_ 2232680451 "BMS application firmware versions
0 - 2 bytes = Application version
3 - 5 bytes = Bootloader version
6 - 7 bytes =  Build revision";
CM_ SG_ 2232680451 BATT_bootTotalFaultCnt_3 "Total Boot fault cnt ";
CM_ SG_ 2232680451 BATT_bootFaultCnt_3 "Boot fault cnt (block app jump from bootloader if cnt >=3)";
CM_ SG_ 2232680451 BATT_bootloaderRevision_3 "Revision bootloader version for BMS";
CM_ SG_ 2232680451 BATT_bootloaderMinor_3 "Minor bootloader version for BMS";
CM_ SG_ 2232680451 BATT_bootloaderMajor_3 "Major bootloader version for BMS";
CM_ SG_ 2232680451 BATT_appRevision_3 "Revision app version for BMS";
CM_ SG_ 2232680451 BATT_appMinor_3 "Minor app version for BMS";
CM_ SG_ 2232680451 BATT_appMajor_3 "Major app version for BMS";
CM_ BO_ 2232680452 "BMS application firmware versions
0 - 2 bytes = Application version
3 - 5 bytes = Bootloader version
6 - 7 bytes =  Build revision";
CM_ SG_ 2232680452 BATT_bootTotalFaultCnt_4 "Total Boot fault cnt ";
CM_ SG_ 2232680452 BATT_bootFaultCnt_4 "Boot fault cnt (block app jump from bootloader if cnt >=3)";
CM_ SG_ 2232680452 BATT_bootloaderRevision_4 "Revision bootloader version for BMS";
CM_ SG_ 2232680452 BATT_bootloaderMinor_4 "Minor bootloader version for BMS";
CM_ SG_ 2232680452 BATT_bootloaderMajor_4 "Major bootloader version for BMS";
CM_ SG_ 2232680452 BATT_appRevision_4 "Revision app version for BMS";
CM_ SG_ 2232680452 BATT_appMinor_4 "Minor app version for BMS";
CM_ SG_ 2232680452 BATT_appMajor_4 "Major app version for BMS";
CM_ BO_ 2232680453 "BMS application firmware versions
0 - 2 bytes = Application version
3 - 5 bytes = Bootloader version
6 - 7 bytes =  Build revision";
CM_ SG_ 2232680453 BATT_bootTotalFaultCnt_5 "Total Boot fault cnt ";
CM_ SG_ 2232680453 BATT_bootFaultCnt_5 "Boot fault cnt (block app jump from bootloader if cnt >=3)";
CM_ SG_ 2232680453 BATT_bootloaderRevision_5 "Revision bootloader version for BMS";
CM_ SG_ 2232680453 BATT_bootloaderMinor_5 "Minor bootloader version for BMS";
CM_ SG_ 2232680453 BATT_bootloaderMajor_5 "Major bootloader version for BMS";
CM_ SG_ 2232680453 BATT_appRevision_5 "Revision app version for BMS";
CM_ SG_ 2232680453 BATT_appMinor_5 "Minor app version for BMS";
CM_ SG_ 2232680453 BATT_appMajor_5 "Major app version for BMS";
CM_ BO_ 2232680454 "BMS application firmware versions
0 - 2 bytes = Application version
3 - 5 bytes = Bootloader version
6 - 7 bytes =  Build revision";
CM_ SG_ 2232680454 BATT_bootTotalFaultCnt_6 "Total Boot fault cnt ";
CM_ SG_ 2232680454 BATT_bootFaultCnt_6 "Boot fault cnt (block app jump from bootloader if cnt >=3)";
CM_ SG_ 2232680454 BATT_bootloaderRevision_6 "Revision bootloader version for BMS";
CM_ SG_ 2232680454 BATT_bootloaderMinor_6 "Minor bootloader version for BMS";
CM_ SG_ 2232680454 BATT_bootloaderMajor_6 "Major bootloader version for BMS";
CM_ SG_ 2232680454 BATT_appRevision_6 "Revision app version for BMS";
CM_ SG_ 2232680454 BATT_appMinor_6 "Minor app version for BMS";
CM_ SG_ 2232680454 BATT_appMajor_6 "Major app version for BMS";
CM_ BO_ 2232680455 "BMS application firmware versions
0 - 2 bytes = Application version
3 - 5 bytes = Bootloader version
6 - 7 bytes =  Build revision";
CM_ SG_ 2232680455 BATT_bootTotalFaultCnt_7 "Total Boot fault cnt ";
CM_ SG_ 2232680455 BATT_bootFaultCnt_7 "Boot fault cnt (block app jump from bootloader if cnt >=3)";
CM_ SG_ 2232680455 BATT_bootloaderRevision_7 "Revision bootloader version for BMS";
CM_ SG_ 2232680455 BATT_bootloaderMinor_7 "Minor bootloader version for BMS";
CM_ SG_ 2232680455 BATT_bootloaderMajor_7 "Major bootloader version for BMS";
CM_ SG_ 2232680455 BATT_appRevision_7 "Revision app version for BMS";
CM_ SG_ 2232680455 BATT_appMinor_7 "Minor app version for BMS";
CM_ SG_ 2232680455 BATT_appMajor_7 "Major app version for BMS";
CM_ BO_ 2232680456 "BMS application firmware versions
0 - 2 bytes = Application version
3 - 5 bytes = Bootloader version
6 - 7 bytes =  Build revision";
CM_ SG_ 2232680456 BATT_bootTotalFaultCnt_8 "Total Boot fault cnt ";
CM_ SG_ 2232680456 BATT_bootFaultCnt_8 "Boot fault cnt (block app jump from bootloader if cnt >=3)";
CM_ SG_ 2232680456 BATT_bootloaderRevision_8 "Revision bootloader version for BMS";
CM_ SG_ 2232680456 BATT_bootloaderMinor_8 "Minor bootloader version for BMS";
CM_ SG_ 2232680456 BATT_bootloaderMajor_8 "Major bootloader version for BMS";
CM_ SG_ 2232680456 BATT_appRevision_8 "Revision app version for BMS";
CM_ SG_ 2232680456 BATT_appMinor_8 "Minor app version for BMS";
CM_ SG_ 2232680456 BATT_appMajor_8 "Major app version for BMS";
CM_ BO_ 2232680457 "BMS application firmware versions
0 - 2 bytes = Application version
3 - 5 bytes = Bootloader version
6 - 7 bytes =  Build revision";
CM_ SG_ 2232680457 BATT_bootTotalFaultCnt_9 "Total Boot fault cnt ";
CM_ SG_ 2232680457 BATT_bootFaultCnt_9 "Boot fault cnt (block app jump from bootloader if cnt >=3)";
CM_ SG_ 2232680457 BATT_bootloaderRevision_9 "Revision bootloader version for BMS";
CM_ SG_ 2232680457 BATT_bootloaderMinor_9 "Minor bootloader version for BMS";
CM_ SG_ 2232680457 BATT_bootloaderMajor_9 "Major bootloader version for BMS";
CM_ SG_ 2232680457 BATT_appRevision_9 "Revision app version for BMS";
CM_ SG_ 2232680457 BATT_appMinor_9 "Minor app version for BMS";
CM_ SG_ 2232680457 BATT_appMajor_9 "Major app version for BMS";
CM_ BO_ 2232680458 "BMS application firmware versions
0 - 2 bytes = Application version
3 - 5 bytes = Bootloader version
6 - 7 bytes =  Build revision";
CM_ SG_ 2232680458 BATT_bootTotalFaultCnt_10 "Total Boot fault cnt ";
CM_ SG_ 2232680458 BATT_bootFaultCnt_10 "Boot fault cnt (block app jump from bootloader if cnt >=3)";
CM_ SG_ 2232680458 BATT_bootloaderRevision_10 "Revision bootloader version for BMS";
CM_ SG_ 2232680458 BATT_bootloaderMinor_10 "Minor bootloader version for BMS";
CM_ SG_ 2232680458 BATT_bootloaderMajor_10 "Major bootloader version for BMS";
CM_ SG_ 2232680458 BATT_appRevision_10 "Revision app version for BMS";
CM_ SG_ 2232680458 BATT_appMinor_10 "Minor app version for BMS";
CM_ SG_ 2232680458 BATT_appMajor_10 "Major app version for BMS";
CM_ BO_ 2232680459 "BMS application firmware versions
0 - 2 bytes = Application version
3 - 5 bytes = Bootloader version
6 - 7 bytes =  Build revision";
CM_ SG_ 2232680459 BATT_bootTotalFaultCnt_11 "Total Boot fault cnt ";
CM_ SG_ 2232680459 BATT_bootFaultCnt_11 "Boot fault cnt (block app jump from bootloader if cnt >=3)";
CM_ SG_ 2232680459 BATT_bootloaderRevision_11 "Revision bootloader version for BMS";
CM_ SG_ 2232680459 BATT_bootloaderMinor_11 "Minor bootloader version for BMS";
CM_ SG_ 2232680459 BATT_bootloaderMajor_11 "Major bootloader version for BMS";
CM_ SG_ 2232680459 BATT_appRevision_11 "Revision app version for BMS";
CM_ SG_ 2232680459 BATT_appMinor_11 "Minor app version for BMS";
CM_ SG_ 2232680459 BATT_appMajor_11 "Major app version for BMS";
CM_ SG_ 2236874752 BATT_hardwareVersion_0 "Hardware version for BMS";
CM_ SG_ 2236874753 BATT_hardwareVersion_1 "Hardware version for BMS";
CM_ SG_ 2236874754 BATT_hardwareVersion_2 "Hardware version for BMS";
CM_ SG_ 2236874755 BATT_hardwareVersion_3 "Hardware version for BMS";
CM_ SG_ 2236874756 BATT_hardwareVersion_4 "Hardware version for BMS";
CM_ SG_ 2236874757 BATT_hardwareVersion_5 "Hardware version for BMS";
CM_ SG_ 2236874758 BATT_hardwareVersion_6 "Hardware version for BMS";
CM_ SG_ 2236874759 BATT_hardwareVersion_7 "Hardware version for BMS";
CM_ SG_ 2236874760 BATT_hardwareVersion_8 "Hardware version for BMS";
CM_ SG_ 2236874761 BATT_hardwareVersion_9 "Hardware version for BMS";
CM_ SG_ 2236874762 BATT_hardwareVersion_10 "Hardware version for BMS";
CM_ SG_ 2236874763 BATT_hardwareVersion_11 "Hardware version for BMS";
CM_ BO_ 2483290112 "Battery status";
CM_ SG_ 2483290112 BATT_modNumModsDataValid_0 "Number of parallel modules with valid data";
CM_ SG_ 2483290112 BATT_modNumModsOnNetwork_0 "Number of modules on the network";
CM_ SG_ 2483290112 BATT_modNumModsOnHvBus_0 "Number of modules on the HV bus";
CM_ SG_ 2483290112 BATT_modNumModsConfigured_0 "Number of parallel modules configured for the Module";
CM_ SG_ 2483290112 BATT_ArbitrationComplete_0 "1 - Node ID Arbitration Completed (default)
0 - Node ID Arbitration Active";
CM_ SG_ 2483290112 BATT_modStateRequested_0 "Reports the requested battery state ";
CM_ SG_ 2483290112 BATT_modDataValid_0 "Module data valid";
CM_ SG_ 2483290112 BATT_prechargeState_0 "Precharge state";
CM_ SG_ 2483290112 BATT_fetPchgCommand_0 "PCHG FET commanded state";
CM_ SG_ 2483290112 BATT_fetDsgCommand_0 "DSG FETs commanded state";
CM_ SG_ 2483290112 BATT_fetChgCommand_0 "CHG FETs commanded state";
CM_ SG_ 2483290112 BATT_fetDsgStatus_0 "DSG FETs status";
CM_ SG_ 2483290112 BATT_fetChgStatus_0 "CHG FETs status";
CM_ SG_ 2483290112 BATT_timeRampdown_0 "Ramp down time";
CM_ SG_ 2483290112 BATT_inhRegen_0 "Inhibit Regen";
CM_ SG_ 2483290112 BATT_inhFullPower_0 "Inhibit Full Power";
CM_ SG_ 2483290112 BATT_inhDriveEntry_0 "Inhibit Drive Entry";
CM_ SG_ 2483290112 BATT_inhDrive_0 "Inhibit Drive";
CM_ SG_ 2483290112 BATT_inhContPower_0 "Inhibit Continuous Power";
CM_ SG_ 2483290112 BATT_inhChargeEntry_0 "Inhibit Charge Entry";
CM_ SG_ 2483290112 BATT_inhCharge_0 "Inhibit Charge";
CM_ SG_ 2483290112 BATT_modPackState_0 "Module reported pack state";
CM_ SG_ 2483290112 BATT_modPchgChargeID_0 "ID of module calculated to do pre-charge";
CM_ SG_ 2483290112 BATT_modChildState_0 "Reports the current state of the battery";
CM_ SG_ 2483290112 BATT_modPchgDriveID_0 "ID of module calculated to do pre-charge";
CM_ SG_ 2483290112 BATT_modParentState_0 "Reports the current state of the battery";
CM_ BO_ 2483290113 "Battery status";
CM_ SG_ 2483290113 BATT_modNumModsDataValid_1 "Number of parallel modules with valid data";
CM_ SG_ 2483290113 BATT_modNumModsOnNetwork_1 "Number of modules on the network";
CM_ SG_ 2483290113 BATT_modNumModsOnHvBus_1 "Number of modules on the HV bus";
CM_ SG_ 2483290113 BATT_modNumModsConfigured_1 "Number of parallel modules configured for the Module";
CM_ SG_ 2483290113 BATT_ArbitrationComplete_1 "1 - Node ID Arbitration Completed (default)
0 - Node ID Arbitration Active";
CM_ SG_ 2483290113 BATT_modStateRequested_1 "Reports the requested battery state ";
CM_ SG_ 2483290113 BATT_modDataValid_1 "Module data valid";
CM_ SG_ 2483290113 BATT_prechargeState_1 "Precharge state";
CM_ SG_ 2483290113 BATT_fetPchgCommand_1 "PCHG FET commanded state";
CM_ SG_ 2483290113 BATT_fetDsgCommand_1 "DSG FETs commanded state";
CM_ SG_ 2483290113 BATT_fetChgCommand_1 "CHG FETs commanded state";
CM_ SG_ 2483290113 BATT_fetDsgStatus_1 "DSG FETs status";
CM_ SG_ 2483290113 BATT_fetChgStatus_1 "CHG FETs status";
CM_ SG_ 2483290113 BATT_timeRampdown_1 "Ramp down time";
CM_ SG_ 2483290113 BATT_inhRegen_1 "Inhibit Regen";
CM_ SG_ 2483290113 BATT_inhFullPower_1 "Inhibit Full Power";
CM_ SG_ 2483290113 BATT_inhDriveEntry_1 "Inhibit Drive Entry";
CM_ SG_ 2483290113 BATT_inhDrive_1 "Inhibit Drive";
CM_ SG_ 2483290113 BATT_inhContPower_1 "Inhibit Continuous Power";
CM_ SG_ 2483290113 BATT_inhChargeEntry_1 "Inhibit Charge Entry";
CM_ SG_ 2483290113 BATT_inhCharge_1 "Inhibit Charge";
CM_ SG_ 2483290113 BATT_modPackState_1 "Module reported pack state";
CM_ SG_ 2483290113 BATT_modPchgChargeID_1 "ID of module calculated to do pre-charge";
CM_ SG_ 2483290113 BATT_modChildState_1 "Reports the current state of the battery";
CM_ SG_ 2483290113 BATT_modPchgDriveID_1 "ID of module calculated to do pre-charge";
CM_ SG_ 2483290113 BATT_modParentState_1 "Reports the current state of the battery";
CM_ BO_ 2483290114 "Battery status";
CM_ SG_ 2483290114 BATT_modNumModsDataValid_2 "Number of parallel modules with valid data";
CM_ SG_ 2483290114 BATT_modNumModsOnNetwork_2 "Number of modules on the network";
CM_ SG_ 2483290114 BATT_modNumModsOnHvBus_2 "Number of modules on the HV bus";
CM_ SG_ 2483290114 BATT_modNumModsConfigured_2 "Number of parallel modules configured for the Module";
CM_ SG_ 2483290114 BATT_ArbitrationComplete_2 "1 - Node ID Arbitration Completed (default)
0 - Node ID Arbitration Active";
CM_ SG_ 2483290114 BATT_modStateRequested_2 "Reports the requested battery state ";
CM_ SG_ 2483290114 BATT_modDataValid_2 "Module data valid";
CM_ SG_ 2483290114 BATT_prechargeState_2 "Precharge state";
CM_ SG_ 2483290114 BATT_fetPchgCommand_2 "PCHG FET commanded state";
CM_ SG_ 2483290114 BATT_fetDsgCommand_2 "DSG FETs commanded state";
CM_ SG_ 2483290114 BATT_fetChgCommand_2 "CHG FETs commanded state";
CM_ SG_ 2483290114 BATT_fetDsgStatus_2 "DSG FETs status";
CM_ SG_ 2483290114 BATT_fetChgStatus_2 "CHG FETs status";
CM_ SG_ 2483290114 BATT_timeRampdown_2 "Ramp down time";
CM_ SG_ 2483290114 BATT_inhRegen_2 "Inhibit Regen";
CM_ SG_ 2483290114 BATT_inhFullPower_2 "Inhibit Full Power";
CM_ SG_ 2483290114 BATT_inhDriveEntry_2 "Inhibit Drive Entry";
CM_ SG_ 2483290114 BATT_inhDrive_2 "Inhibit Drive";
CM_ SG_ 2483290114 BATT_inhContPower_2 "Inhibit Continuous Power";
CM_ SG_ 2483290114 BATT_inhChargeEntry_2 "Inhibit Charge Entry";
CM_ SG_ 2483290114 BATT_inhCharge_2 "Inhibit Charge";
CM_ SG_ 2483290114 BATT_modPackState_2 "Module reported pack state";
CM_ SG_ 2483290114 BATT_modPchgChargeID_2 "ID of module calculated to do pre-charge";
CM_ SG_ 2483290114 BATT_modChildState_2 "Reports the current state of the battery";
CM_ SG_ 2483290114 BATT_modPchgDriveID_2 "ID of module calculated to do pre-charge";
CM_ SG_ 2483290114 BATT_modParentState_2 "Reports the current state of the battery";
CM_ BO_ 2483290115 "Battery status";
CM_ SG_ 2483290115 BATT_modNumModsDataValid_3 "Number of parallel modules with valid data";
CM_ SG_ 2483290115 BATT_modNumModsOnNetwork_3 "Number of modules on the network";
CM_ SG_ 2483290115 BATT_modNumModsOnHvBus_3 "Number of modules on the HV bus";
CM_ SG_ 2483290115 BATT_modNumModsConfigured_3 "Number of parallel modules configured for the Module";
CM_ SG_ 2483290115 BATT_ArbitrationComplete_3 "1 - Node ID Arbitration Completed (default)
0 - Node ID Arbitration Active";
CM_ SG_ 2483290115 BATT_modStateRequested_3 "Reports the requested battery state ";
CM_ SG_ 2483290115 BATT_modDataValid_3 "Module data valid";
CM_ SG_ 2483290115 BATT_prechargeState_3 "Precharge state";
CM_ SG_ 2483290115 BATT_fetPchgCommand_3 "PCHG FET commanded state";
CM_ SG_ 2483290115 BATT_fetDsgCommand_3 "DSG FETs commanded state";
CM_ SG_ 2483290115 BATT_fetChgCommand_3 "CHG FETs commanded state";
CM_ SG_ 2483290115 BATT_fetDsgStatus_3 "DSG FETs status";
CM_ SG_ 2483290115 BATT_fetChgStatus_3 "CHG FETs status";
CM_ SG_ 2483290115 BATT_timeRampdown_3 "Ramp down time";
CM_ SG_ 2483290115 BATT_inhRegen_3 "Inhibit Regen";
CM_ SG_ 2483290115 BATT_inhFullPower_3 "Inhibit Full Power";
CM_ SG_ 2483290115 BATT_inhDriveEntry_3 "Inhibit Drive Entry";
CM_ SG_ 2483290115 BATT_inhDrive_3 "Inhibit Drive";
CM_ SG_ 2483290115 BATT_inhContPower_3 "Inhibit Continuous Power";
CM_ SG_ 2483290115 BATT_inhChargeEntry_3 "Inhibit Charge Entry";
CM_ SG_ 2483290115 BATT_inhCharge_3 "Inhibit Charge";
CM_ SG_ 2483290115 BATT_modPackState_3 "Module reported pack state";
CM_ SG_ 2483290115 BATT_modPchgChargeID_3 "ID of module calculated to do pre-charge";
CM_ SG_ 2483290115 BATT_modChildState_3 "Reports the current state of the battery";
CM_ SG_ 2483290115 BATT_modPchgDriveID_3 "ID of module calculated to do pre-charge";
CM_ SG_ 2483290115 BATT_modParentState_3 "Reports the current state of the battery";
CM_ BO_ 2483290116 "Battery status";
CM_ SG_ 2483290116 BATT_modNumModsDataValid_4 "Number of parallel modules with valid data";
CM_ SG_ 2483290116 BATT_modNumModsOnNetwork_4 "Number of modules on the network";
CM_ SG_ 2483290116 BATT_modNumModsOnHvBus_4 "Number of modules on the HV bus";
CM_ SG_ 2483290116 BATT_modNumModsConfigured_4 "Number of parallel modules configured for the Module";
CM_ SG_ 2483290116 BATT_ArbitrationComplete_4 "1 - Node ID Arbitration Completed (default)
0 - Node ID Arbitration Active";
CM_ SG_ 2483290116 BATT_modStateRequested_4 "Reports the requested battery state ";
CM_ SG_ 2483290116 BATT_modDataValid_4 "Module data valid";
CM_ SG_ 2483290116 BATT_prechargeState_4 "Precharge state";
CM_ SG_ 2483290116 BATT_fetPchgCommand_4 "PCHG FET commanded state";
CM_ SG_ 2483290116 BATT_fetDsgCommand_4 "DSG FETs commanded state";
CM_ SG_ 2483290116 BATT_fetChgCommand_4 "CHG FETs commanded state";
CM_ SG_ 2483290116 BATT_fetDsgStatus_4 "DSG FETs status";
CM_ SG_ 2483290116 BATT_fetChgStatus_4 "CHG FETs status";
CM_ SG_ 2483290116 BATT_timeRampdown_4 "Ramp down time";
CM_ SG_ 2483290116 BATT_inhRegen_4 "Inhibit Regen";
CM_ SG_ 2483290116 BATT_inhFullPower_4 "Inhibit Full Power";
CM_ SG_ 2483290116 BATT_inhDriveEntry_4 "Inhibit Drive Entry";
CM_ SG_ 2483290116 BATT_inhDrive_4 "Inhibit Drive";
CM_ SG_ 2483290116 BATT_inhContPower_4 "Inhibit Continuous Power";
CM_ SG_ 2483290116 BATT_inhChargeEntry_4 "Inhibit Charge Entry";
CM_ SG_ 2483290116 BATT_inhCharge_4 "Inhibit Charge";
CM_ SG_ 2483290116 BATT_modPackState_4 "Module reported pack state";
CM_ SG_ 2483290116 BATT_modPchgChargeID_4 "ID of module calculated to do pre-charge";
CM_ SG_ 2483290116 BATT_modChildState_4 "Reports the current state of the battery";
CM_ SG_ 2483290116 BATT_modPchgDriveID_4 "ID of module calculated to do pre-charge";
CM_ SG_ 2483290116 BATT_modParentState_4 "Reports the current state of the battery";
CM_ BO_ 2483290117 "Battery status";
CM_ SG_ 2483290117 BATT_modNumModsDataValid_5 "Number of parallel modules with valid data";
CM_ SG_ 2483290117 BATT_modNumModsOnNetwork_5 "Number of modules on the network";
CM_ SG_ 2483290117 BATT_modNumModsOnHvBus_5 "Number of modules on the HV bus";
CM_ SG_ 2483290117 BATT_modNumModsConfigured_5 "Number of parallel modules configured for the Module";
CM_ SG_ 2483290117 BATT_ArbitrationComplete_5 "1 - Node ID Arbitration Completed (default)
0 - Node ID Arbitration Active";
CM_ SG_ 2483290117 BATT_modStateRequested_5 "Reports the requested battery state ";
CM_ SG_ 2483290117 BATT_modDataValid_5 "Module data valid";
CM_ SG_ 2483290117 BATT_prechargeState_5 "Precharge state";
CM_ SG_ 2483290117 BATT_fetPchgCommand_5 "PCHG FET commanded state";
CM_ SG_ 2483290117 BATT_fetDsgCommand_5 "DSG FETs commanded state";
CM_ SG_ 2483290117 BATT_fetChgCommand_5 "CHG FETs commanded state";
CM_ SG_ 2483290117 BATT_fetDsgStatus_5 "DSG FETs status";
CM_ SG_ 2483290117 BATT_fetChgStatus_5 "CHG FETs status";
CM_ SG_ 2483290117 BATT_timeRampdown_5 "Ramp down time";
CM_ SG_ 2483290117 BATT_inhRegen_5 "Inhibit Regen";
CM_ SG_ 2483290117 BATT_inhFullPower_5 "Inhibit Full Power";
CM_ SG_ 2483290117 BATT_inhDriveEntry_5 "Inhibit Drive Entry";
CM_ SG_ 2483290117 BATT_inhDrive_5 "Inhibit Drive";
CM_ SG_ 2483290117 BATT_inhContPower_5 "Inhibit Continuous Power";
CM_ SG_ 2483290117 BATT_inhChargeEntry_5 "Inhibit Charge Entry";
CM_ SG_ 2483290117 BATT_inhCharge_5 "Inhibit Charge";
CM_ SG_ 2483290117 BATT_modPackState_5 "Module reported pack state";
CM_ SG_ 2483290117 BATT_modPchgChargeID_5 "ID of module calculated to do pre-charge";
CM_ SG_ 2483290117 BATT_modChildState_5 "Reports the current state of the battery";
CM_ SG_ 2483290117 BATT_modPchgDriveID_5 "ID of module calculated to do pre-charge";
CM_ SG_ 2483290117 BATT_modParentState_5 "Reports the current state of the battery";
CM_ BO_ 2483290118 "Battery status";
CM_ SG_ 2483290118 BATT_modNumModsDataValid_6 "Number of parallel modules with valid data";
CM_ SG_ 2483290118 BATT_modNumModsOnNetwork_6 "Number of modules on the network";
CM_ SG_ 2483290118 BATT_modNumModsOnHvBus_6 "Number of modules on the HV bus";
CM_ SG_ 2483290118 BATT_modNumModsConfigured_6 "Number of parallel modules configured for the Module";
CM_ SG_ 2483290118 BATT_ArbitrationComplete_6 "1 - Node ID Arbitration Completed (default)
0 - Node ID Arbitration Active";
CM_ SG_ 2483290118 BATT_modStateRequested_6 "Reports the requested battery state ";
CM_ SG_ 2483290118 BATT_modDataValid_6 "Module data valid";
CM_ SG_ 2483290118 BATT_prechargeState_6 "Precharge state";
CM_ SG_ 2483290118 BATT_fetPchgCommand_6 "PCHG FET commanded state";
CM_ SG_ 2483290118 BATT_fetDsgCommand_6 "DSG FETs commanded state";
CM_ SG_ 2483290118 BATT_fetChgCommand_6 "CHG FETs commanded state";
CM_ SG_ 2483290118 BATT_fetDsgStatus_6 "DSG FETs status";
CM_ SG_ 2483290118 BATT_fetChgStatus_6 "CHG FETs status";
CM_ SG_ 2483290118 BATT_timeRampdown_6 "Ramp down time";
CM_ SG_ 2483290118 BATT_inhRegen_6 "Inhibit Regen";
CM_ SG_ 2483290118 BATT_inhFullPower_6 "Inhibit Full Power";
CM_ SG_ 2483290118 BATT_inhDriveEntry_6 "Inhibit Drive Entry";
CM_ SG_ 2483290118 BATT_inhDrive_6 "Inhibit Drive";
CM_ SG_ 2483290118 BATT_inhContPower_6 "Inhibit Continuous Power";
CM_ SG_ 2483290118 BATT_inhChargeEntry_6 "Inhibit Charge Entry";
CM_ SG_ 2483290118 BATT_inhCharge_6 "Inhibit Charge";
CM_ SG_ 2483290118 BATT_modPackState_6 "Module reported pack state";
CM_ SG_ 2483290118 BATT_modPchgChargeID_6 "ID of module calculated to do pre-charge";
CM_ SG_ 2483290118 BATT_modChildState_6 "Reports the current state of the battery";
CM_ SG_ 2483290118 BATT_modPchgDriveID_6 "ID of module calculated to do pre-charge";
CM_ SG_ 2483290118 BATT_modParentState_6 "Reports the current state of the battery";
CM_ BO_ 2483290119 "Battery status";
CM_ SG_ 2483290119 BATT_modNumModsDataValid_7 "Number of parallel modules with valid data";
CM_ SG_ 2483290119 BATT_modNumModsOnNetwork_7 "Number of modules on the network";
CM_ SG_ 2483290119 BATT_modNumModsOnHvBus_7 "Number of modules on the HV bus";
CM_ SG_ 2483290119 BATT_modNumModsConfigured_7 "Number of parallel modules configured for the Module";
CM_ SG_ 2483290119 BATT_ArbitrationComplete_7 "1 - Node ID Arbitration Completed (default)
0 - Node ID Arbitration Active";
CM_ SG_ 2483290119 BATT_modStateRequested_7 "Reports the requested battery state ";
CM_ SG_ 2483290119 BATT_modDataValid_7 "Module data valid";
CM_ SG_ 2483290119 BATT_prechargeState_7 "Precharge state";
CM_ SG_ 2483290119 BATT_fetPchgCommand_7 "PCHG FET commanded state";
CM_ SG_ 2483290119 BATT_fetDsgCommand_7 "DSG FETs commanded state";
CM_ SG_ 2483290119 BATT_fetChgCommand_7 "CHG FETs commanded state";
CM_ SG_ 2483290119 BATT_fetDsgStatus_7 "DSG FETs status";
CM_ SG_ 2483290119 BATT_fetChgStatus_7 "CHG FETs status";
CM_ SG_ 2483290119 BATT_timeRampdown_7 "Ramp down time";
CM_ SG_ 2483290119 BATT_inhRegen_7 "Inhibit Regen";
CM_ SG_ 2483290119 BATT_inhFullPower_7 "Inhibit Full Power";
CM_ SG_ 2483290119 BATT_inhDriveEntry_7 "Inhibit Drive Entry";
CM_ SG_ 2483290119 BATT_inhDrive_7 "Inhibit Drive";
CM_ SG_ 2483290119 BATT_inhContPower_7 "Inhibit Continuous Power";
CM_ SG_ 2483290119 BATT_inhChargeEntry_7 "Inhibit Charge Entry";
CM_ SG_ 2483290119 BATT_inhCharge_7 "Inhibit Charge";
CM_ SG_ 2483290119 BATT_modPackState_7 "Module reported pack state";
CM_ SG_ 2483290119 BATT_modPchgChargeID_7 "ID of module calculated to do pre-charge";
CM_ SG_ 2483290119 BATT_modChildState_7 "Reports the current state of the battery";
CM_ SG_ 2483290119 BATT_modPchgDriveID_7 "ID of module calculated to do pre-charge";
CM_ SG_ 2483290119 BATT_modParentState_7 "Reports the current state of the battery";
CM_ BO_ 2483290120 "Battery status";
CM_ SG_ 2483290120 BATT_modNumModsDataValid_8 "Number of parallel modules with valid data";
CM_ SG_ 2483290120 BATT_modNumModsOnNetwork_8 "Number of modules on the network";
CM_ SG_ 2483290120 BATT_modNumModsOnHvBus_8 "Number of modules on the HV bus";
CM_ SG_ 2483290120 BATT_modNumModsConfigured_8 "Number of parallel modules configured for the Module";
CM_ SG_ 2483290120 BATT_ArbitrationComplete_8 "1 - Node ID Arbitration Completed (default)
0 - Node ID Arbitration Active";
CM_ SG_ 2483290120 BATT_modStateRequested_8 "Reports the requested battery state ";
CM_ SG_ 2483290120 BATT_modDataValid_8 "Module data valid";
CM_ SG_ 2483290120 BATT_prechargeState_8 "Precharge state";
CM_ SG_ 2483290120 BATT_fetPchgCommand_8 "PCHG FET commanded state";
CM_ SG_ 2483290120 BATT_fetDsgCommand_8 "DSG FETs commanded state";
CM_ SG_ 2483290120 BATT_fetChgCommand_8 "CHG FETs commanded state";
CM_ SG_ 2483290120 BATT_fetDsgStatus_8 "DSG FETs status";
CM_ SG_ 2483290120 BATT_fetChgStatus_8 "CHG FETs status";
CM_ SG_ 2483290120 BATT_timeRampdown_8 "Ramp down time";
CM_ SG_ 2483290120 BATT_inhRegen_8 "Inhibit Regen";
CM_ SG_ 2483290120 BATT_inhFullPower_8 "Inhibit Full Power";
CM_ SG_ 2483290120 BATT_inhDriveEntry_8 "Inhibit Drive Entry";
CM_ SG_ 2483290120 BATT_inhDrive_8 "Inhibit Drive";
CM_ SG_ 2483290120 BATT_inhContPower_8 "Inhibit Continuous Power";
CM_ SG_ 2483290120 BATT_inhChargeEntry_8 "Inhibit Charge Entry";
CM_ SG_ 2483290120 BATT_inhCharge_8 "Inhibit Charge";
CM_ SG_ 2483290120 BATT_modPackState_8 "Module reported pack state";
CM_ SG_ 2483290120 BATT_modPchgChargeID_8 "ID of module calculated to do pre-charge";
CM_ SG_ 2483290120 BATT_modChildState_8 "Reports the current state of the battery";
CM_ SG_ 2483290120 BATT_modPchgDriveID_8 "ID of module calculated to do pre-charge";
CM_ SG_ 2483290120 BATT_modParentState_8 "Reports the current state of the battery";
CM_ BO_ 2483290121 "Battery status";
CM_ SG_ 2483290121 BATT_modNumModsDataValid_9 "Number of parallel modules with valid data";
CM_ SG_ 2483290121 BATT_modNumModsOnNetwork_9 "Number of modules on the network";
CM_ SG_ 2483290121 BATT_modNumModsOnHvBus_9 "Number of modules on the HV bus";
CM_ SG_ 2483290121 BATT_modNumModsConfigured_9 "Number of parallel modules configured for the Module";
CM_ SG_ 2483290121 BATT_ArbitrationComplete_9 "1 - Node ID Arbitration Completed (default)
0 - Node ID Arbitration Active";
CM_ SG_ 2483290121 BATT_modStateRequested_9 "Reports the requested battery state ";
CM_ SG_ 2483290121 BATT_modDataValid_9 "Module data valid";
CM_ SG_ 2483290121 BATT_prechargeState_9 "Precharge state";
CM_ SG_ 2483290121 BATT_fetPchgCommand_9 "PCHG FET commanded state";
CM_ SG_ 2483290121 BATT_fetDsgCommand_9 "DSG FETs commanded state";
CM_ SG_ 2483290121 BATT_fetChgCommand_9 "CHG FETs commanded state";
CM_ SG_ 2483290121 BATT_fetDsgStatus_9 "DSG FETs status";
CM_ SG_ 2483290121 BATT_fetChgStatus_9 "CHG FETs status";
CM_ SG_ 2483290121 BATT_timeRampdown_9 "Ramp down time";
CM_ SG_ 2483290121 BATT_inhRegen_9 "Inhibit Regen";
CM_ SG_ 2483290121 BATT_inhFullPower_9 "Inhibit Full Power";
CM_ SG_ 2483290121 BATT_inhDriveEntry_9 "Inhibit Drive Entry";
CM_ SG_ 2483290121 BATT_inhDrive_9 "Inhibit Drive";
CM_ SG_ 2483290121 BATT_inhContPower_9 "Inhibit Continuous Power";
CM_ SG_ 2483290121 BATT_inhChargeEntry_9 "Inhibit Charge Entry";
CM_ SG_ 2483290121 BATT_inhCharge_9 "Inhibit Charge";
CM_ SG_ 2483290121 BATT_modPackState_9 "Module reported pack state";
CM_ SG_ 2483290121 BATT_modPchgChargeID_9 "ID of module calculated to do pre-charge";
CM_ SG_ 2483290121 BATT_modChildState_9 "Reports the current state of the battery";
CM_ SG_ 2483290121 BATT_modPchgDriveID_9 "ID of module calculated to do pre-charge";
CM_ SG_ 2483290121 BATT_modParentState_9 "Reports the current state of the battery";
CM_ BO_ 2483290122 "Battery status";
CM_ SG_ 2483290122 BATT_modNumModsDataValid_10 "Number of parallel modules with valid data";
CM_ SG_ 2483290122 BATT_modNumModsOnNetwork_10 "Number of modules on the network";
CM_ SG_ 2483290122 BATT_modNumModsOnHvBus_10 "Number of modules on the HV bus";
CM_ SG_ 2483290122 BATT_modNumModsConfigured_10 "Number of parallel modules configured for the Module";
CM_ SG_ 2483290122 BATT_ArbitrationComplete_10 "1 - Node ID Arbitration Completed (default)
0 - Node ID Arbitration Active";
CM_ SG_ 2483290122 BATT_modStateRequested_10 "Reports the requested battery state ";
CM_ SG_ 2483290122 BATT_modDataValid_10 "Module data valid";
CM_ SG_ 2483290122 BATT_prechargeState_10 "Precharge state";
CM_ SG_ 2483290122 BATT_fetPchgCommand_10 "PCHG FET commanded state";
CM_ SG_ 2483290122 BATT_fetDsgCommand_10 "DSG FETs commanded state";
CM_ SG_ 2483290122 BATT_fetChgCommand_10 "CHG FETs commanded state";
CM_ SG_ 2483290122 BATT_fetDsgStatus_10 "DSG FETs status";
CM_ SG_ 2483290122 BATT_fetChgStatus_10 "CHG FETs status";
CM_ SG_ 2483290122 BATT_timeRampdown_10 "Ramp down time";
CM_ SG_ 2483290122 BATT_inhRegen_10 "Inhibit Regen";
CM_ SG_ 2483290122 BATT_inhFullPower_10 "Inhibit Full Power";
CM_ SG_ 2483290122 BATT_inhDriveEntry_10 "Inhibit Drive Entry";
CM_ SG_ 2483290122 BATT_inhDrive_10 "Inhibit Drive";
CM_ SG_ 2483290122 BATT_inhContPower_10 "Inhibit Continuous Power";
CM_ SG_ 2483290122 BATT_inhChargeEntry_10 "Inhibit Charge Entry";
CM_ SG_ 2483290122 BATT_inhCharge_10 "Inhibit Charge";
CM_ SG_ 2483290122 BATT_modPackState_10 "Module reported pack state";
CM_ SG_ 2483290122 BATT_modPchgChargeID_10 "ID of module calculated to do pre-charge";
CM_ SG_ 2483290122 BATT_modChildState_10 "Reports the current state of the battery";
CM_ SG_ 2483290122 BATT_modPchgDriveID_10 "ID of module calculated to do pre-charge";
CM_ SG_ 2483290122 BATT_modParentState_10 "Reports the current state of the battery";
CM_ BO_ 2483290123 "Battery status";
CM_ SG_ 2483290123 BATT_modNumModsDataValid_11 "Number of parallel modules with valid data";
CM_ SG_ 2483290123 BATT_modNumModsOnNetwork_11 "Number of modules on the network";
CM_ SG_ 2483290123 BATT_modNumModsOnHvBus_11 "Number of modules on the HV bus";
CM_ SG_ 2483290123 BATT_modNumModsConfigured_11 "Number of parallel modules configured for the Module";
CM_ SG_ 2483290123 BATT_ArbitrationComplete_11 "1 - Node ID Arbitration Completed (default)
0 - Node ID Arbitration Active";
CM_ SG_ 2483290123 BATT_modStateRequested_11 "Reports the requested battery state ";
CM_ SG_ 2483290123 BATT_modDataValid_11 "Module data valid";
CM_ SG_ 2483290123 BATT_prechargeState_11 "Precharge state";
CM_ SG_ 2483290123 BATT_fetPchgCommand_11 "PCHG FET commanded state";
CM_ SG_ 2483290123 BATT_fetDsgCommand_11 "DSG FETs commanded state";
CM_ SG_ 2483290123 BATT_fetChgCommand_11 "CHG FETs commanded state";
CM_ SG_ 2483290123 BATT_fetDsgStatus_11 "DSG FETs status";
CM_ SG_ 2483290123 BATT_fetChgStatus_11 "CHG FETs status";
CM_ SG_ 2483290123 BATT_timeRampdown_11 "Ramp down time";
CM_ SG_ 2483290123 BATT_inhRegen_11 "Inhibit Regen";
CM_ SG_ 2483290123 BATT_inhFullPower_11 "Inhibit Full Power";
CM_ SG_ 2483290123 BATT_inhDriveEntry_11 "Inhibit Drive Entry";
CM_ SG_ 2483290123 BATT_inhDrive_11 "Inhibit Drive";
CM_ SG_ 2483290123 BATT_inhContPower_11 "Inhibit Continuous Power";
CM_ SG_ 2483290123 BATT_inhChargeEntry_11 "Inhibit Charge Entry";
CM_ SG_ 2483290123 BATT_inhCharge_11 "Inhibit Charge";
CM_ SG_ 2483290123 BATT_modPackState_11 "Module reported pack state";
CM_ SG_ 2483290123 BATT_modPchgChargeID_11 "ID of module calculated to do pre-charge";
CM_ SG_ 2483290123 BATT_modChildState_11 "Reports the current state of the battery";
CM_ SG_ 2483290123 BATT_modPchgDriveID_11 "ID of module calculated to do pre-charge";
CM_ SG_ 2483290123 BATT_modParentState_11 "Reports the current state of the battery";
CM_ SG_ 2487484416 BATT_boardIO_DIS_OC_FLT_LA_0 "DIS_OC_FLT_LA input signal status";
CM_ SG_ 2487484416 BATT_boardIO_L9963_FAULT_0 "L9963_FAULT input signal status";
CM_ SG_ 2487484416 BATT_boardIO_IL_WAKE_LATCH_0 "IL_WAKE_LATCH input signal status";
CM_ SG_ 2487484416 BATT_boardIO_IH_WAKE_LATCH_0 "IH_WAKE_LATCH input signal status";
CM_ SG_ 2487484416 BATT_boardIO_CAN_WAKE_LATCH_0 "CAN_WAKE_LATCH input signal status";
CM_ SG_ 2487484417 BATT_boardIO_DIS_OC_FLT_LA_1 "DIS_OC_FLT_LA input signal status";
CM_ SG_ 2487484417 BATT_boardIO_L9963_FAULT_1 "L9963_FAULT input signal status";
CM_ SG_ 2487484417 BATT_boardIO_IL_WAKE_LATCH_1 "IL_WAKE_LATCH input signal status";
CM_ SG_ 2487484417 BATT_boardIO_IH_WAKE_LATCH_1 "IH_WAKE_LATCH input signal status";
CM_ SG_ 2487484417 BATT_boardIO_CAN_WAKE_LATCH_1 "CAN_WAKE_LATCH input signal status";
CM_ SG_ 2487484418 BATT_boardIO_DIS_OC_FLT_LA_2 "DIS_OC_FLT_LA input signal status";
CM_ SG_ 2487484418 BATT_boardIO_L9963_FAULT_2 "L9963_FAULT input signal status";
CM_ SG_ 2487484418 BATT_boardIO_IL_WAKE_LATCH_2 "IL_WAKE_LATCH input signal status";
CM_ SG_ 2487484418 BATT_boardIO_IH_WAKE_LATCH_2 "IH_WAKE_LATCH input signal status";
CM_ SG_ 2487484418 BATT_boardIO_CAN_WAKE_LATCH_2 "CAN_WAKE_LATCH input signal status";
CM_ SG_ 2487484419 BATT_boardIO_DIS_OC_FLT_LA_3 "DIS_OC_FLT_LA input signal status";
CM_ SG_ 2487484419 BATT_boardIO_L9963_FAULT_3 "L9963_FAULT input signal status";
CM_ SG_ 2487484419 BATT_boardIO_IL_WAKE_LATCH_3 "IL_WAKE_LATCH input signal status";
CM_ SG_ 2487484419 BATT_boardIO_IH_WAKE_LATCH_3 "IH_WAKE_LATCH input signal status";
CM_ SG_ 2487484419 BATT_boardIO_CAN_WAKE_LATCH_3 "CAN_WAKE_LATCH input signal status";
CM_ SG_ 2487484420 BATT_boardIO_DIS_OC_FLT_LA_4 "DIS_OC_FLT_LA input signal status";
CM_ SG_ 2487484420 BATT_boardIO_L9963_FAULT_4 "L9963_FAULT input signal status";
CM_ SG_ 2487484420 BATT_boardIO_IL_WAKE_LATCH_4 "IL_WAKE_LATCH input signal status";
CM_ SG_ 2487484420 BATT_boardIO_IH_WAKE_LATCH_4 "IH_WAKE_LATCH input signal status";
CM_ SG_ 2487484420 BATT_boardIO_CAN_WAKE_LATCH_4 "CAN_WAKE_LATCH input signal status";
CM_ SG_ 2487484421 BATT_boardIO_DIS_OC_FLT_LA_5 "DIS_OC_FLT_LA input signal status";
CM_ SG_ 2487484421 BATT_boardIO_L9963_FAULT_5 "L9963_FAULT input signal status";
CM_ SG_ 2487484421 BATT_boardIO_IL_WAKE_LATCH_5 "IL_WAKE_LATCH input signal status";
CM_ SG_ 2487484421 BATT_boardIO_IH_WAKE_LATCH_5 "IH_WAKE_LATCH input signal status";
CM_ SG_ 2487484421 BATT_boardIO_CAN_WAKE_LATCH_5 "CAN_WAKE_LATCH input signal status";
CM_ SG_ 2487484422 BATT_boardIO_DIS_OC_FLT_LA_6 "DIS_OC_FLT_LA input signal status";
CM_ SG_ 2487484422 BATT_boardIO_L9963_FAULT_6 "L9963_FAULT input signal status";
CM_ SG_ 2487484422 BATT_boardIO_IL_WAKE_LATCH_6 "IL_WAKE_LATCH input signal status";
CM_ SG_ 2487484422 BATT_boardIO_IH_WAKE_LATCH_6 "IH_WAKE_LATCH input signal status";
CM_ SG_ 2487484422 BATT_boardIO_CAN_WAKE_LATCH_6 "CAN_WAKE_LATCH input signal status";
CM_ SG_ 2487484423 BATT_boardIO_DIS_OC_FLT_LA_7 "DIS_OC_FLT_LA input signal status";
CM_ SG_ 2487484423 BATT_boardIO_L9963_FAULT_7 "L9963_FAULT input signal status";
CM_ SG_ 2487484423 BATT_boardIO_IL_WAKE_LATCH_7 "IL_WAKE_LATCH input signal status";
CM_ SG_ 2487484423 BATT_boardIO_IH_WAKE_LATCH_7 "IH_WAKE_LATCH input signal status";
CM_ SG_ 2487484423 BATT_boardIO_CAN_WAKE_LATCH_7 "CAN_WAKE_LATCH input signal status";
CM_ SG_ 2487484424 BATT_boardIO_DIS_OC_FLT_LA_8 "DIS_OC_FLT_LA input signal status";
CM_ SG_ 2487484424 BATT_boardIO_L9963_FAULT_8 "L9963_FAULT input signal status";
CM_ SG_ 2487484424 BATT_boardIO_IL_WAKE_LATCH_8 "IL_WAKE_LATCH input signal status";
CM_ SG_ 2487484424 BATT_boardIO_IH_WAKE_LATCH_8 "IH_WAKE_LATCH input signal status";
CM_ SG_ 2487484424 BATT_boardIO_CAN_WAKE_LATCH_8 "CAN_WAKE_LATCH input signal status";
CM_ SG_ 2487484425 BATT_boardIO_DIS_OC_FLT_LA_9 "DIS_OC_FLT_LA input signal status";
CM_ SG_ 2487484425 BATT_boardIO_L9963_FAULT_9 "L9963_FAULT input signal status";
CM_ SG_ 2487484425 BATT_boardIO_IL_WAKE_LATCH_9 "IL_WAKE_LATCH input signal status";
CM_ SG_ 2487484425 BATT_boardIO_IH_WAKE_LATCH_9 "IH_WAKE_LATCH input signal status";
CM_ SG_ 2487484425 BATT_boardIO_CAN_WAKE_LATCH_9 "CAN_WAKE_LATCH input signal status";
CM_ SG_ 2487484426 BATT_boardIO_DIS_OC_FLT_LA_10 "DIS_OC_FLT_LA input signal status";
CM_ SG_ 2487484426 BATT_boardIO_L9963_FAULT_10 "L9963_FAULT input signal status";
CM_ SG_ 2487484426 BATT_boardIO_IL_WAKE_LATCH_10 "IL_WAKE_LATCH input signal status";
CM_ SG_ 2487484426 BATT_boardIO_IH_WAKE_LATCH_10 "IH_WAKE_LATCH input signal status";
CM_ SG_ 2487484426 BATT_boardIO_CAN_WAKE_LATCH_10 "CAN_WAKE_LATCH input signal status";
CM_ SG_ 2487484427 BATT_boardIO_DIS_OC_FLT_LA_11 "DIS_OC_FLT_LA input signal status";
CM_ SG_ 2487484427 BATT_boardIO_L9963_FAULT_11 "L9963_FAULT input signal status";
CM_ SG_ 2487484427 BATT_boardIO_IL_WAKE_LATCH_11 "IL_WAKE_LATCH input signal status";
CM_ SG_ 2487484427 BATT_boardIO_IH_WAKE_LATCH_11 "IH_WAKE_LATCH input signal status";
CM_ SG_ 2487484427 BATT_boardIO_CAN_WAKE_LATCH_11 "CAN_WAKE_LATCH input signal status";
CM_ BO_ 2508193792 "Bootloader and BMS application firmware versions";
CM_ SG_ 2508193792 BATT_bootloaderRevision_bootup_0 "Revision bootloader version for BMS";
CM_ SG_ 2508193792 BATT_bootloaderMinor_bootup_0 "Minor bootloader version for BMS";
CM_ SG_ 2508193792 BATT_bootloaderMajor_bootup_0 "Major bootloader version for BMS";
CM_ SG_ 2508193792 BATT_appRevision_bootup_0 "Revision app version for BMS";
CM_ SG_ 2508193792 BATT_appMinor_bootup_0 "Minor app version for BMS";
CM_ SG_ 2508193792 BATT_appMajor_bootup_0 "Major app version for BMS";
CM_ BO_ 2508193793 "Bootloader and BMS application firmware versions";
CM_ SG_ 2508193793 BATT_bootloaderRevision_bootup_1 "Revision bootloader version for BMS";
CM_ SG_ 2508193793 BATT_bootloaderMinor_bootup_1 "Minor bootloader version for BMS";
CM_ SG_ 2508193793 BATT_bootloaderMajor_bootup_1 "Major bootloader version for BMS";
CM_ SG_ 2508193793 BATT_appRevision_bootup_1 "Revision app version for BMS";
CM_ SG_ 2508193793 BATT_appMinor_bootup_1 "Minor app version for BMS";
CM_ SG_ 2508193793 BATT_appMajor_bootup_1 "Major app version for BMS";
CM_ BO_ 2508193794 "Bootloader and BMS application firmware versions";
CM_ SG_ 2508193794 BATT_bootloaderRevision_bootup_2 "Revision bootloader version for BMS";
CM_ SG_ 2508193794 BATT_bootloaderMinor_bootup_2 "Minor bootloader version for BMS";
CM_ SG_ 2508193794 BATT_bootloaderMajor_bootup_2 "Major bootloader version for BMS";
CM_ SG_ 2508193794 BATT_appRevision_bootup_2 "Revision app version for BMS";
CM_ SG_ 2508193794 BATT_appMinor_bootup_2 "Minor app version for BMS";
CM_ SG_ 2508193794 BATT_appMajor_bootup_2 "Major app version for BMS";
CM_ BO_ 2508193795 "Bootloader and BMS application firmware versions";
CM_ SG_ 2508193795 BATT_bootloaderRevision_bootup_3 "Revision bootloader version for BMS";
CM_ SG_ 2508193795 BATT_bootloaderMinor_bootup_3 "Minor bootloader version for BMS";
CM_ SG_ 2508193795 BATT_bootloaderMajor_bootup_3 "Major bootloader version for BMS";
CM_ SG_ 2508193795 BATT_appRevision_bootup_3 "Revision app version for BMS";
CM_ SG_ 2508193795 BATT_appMinor_bootup_3 "Minor app version for BMS";
CM_ SG_ 2508193795 BATT_appMajor_bootup_3 "Major app version for BMS";
CM_ BO_ 2508193796 "Bootloader and BMS application firmware versions";
CM_ SG_ 2508193796 BATT_bootloaderRevision_bootup_4 "Revision bootloader version for BMS";
CM_ SG_ 2508193796 BATT_bootloaderMinor_bootup_4 "Minor bootloader version for BMS";
CM_ SG_ 2508193796 BATT_bootloaderMajor_bootup_4 "Major bootloader version for BMS";
CM_ SG_ 2508193796 BATT_appRevision_bootup_4 "Revision app version for BMS";
CM_ SG_ 2508193796 BATT_appMinor_bootup_4 "Minor app version for BMS";
CM_ SG_ 2508193796 BATT_appMajor_bootup_4 "Major app version for BMS";
CM_ BO_ 2508193797 "Bootloader and BMS application firmware versions";
CM_ SG_ 2508193797 BATT_bootloaderRevision_bootup_5 "Revision bootloader version for BMS";
CM_ SG_ 2508193797 BATT_bootloaderMinor_bootup_5 "Minor bootloader version for BMS";
CM_ SG_ 2508193797 BATT_bootloaderMajor_bootup_5 "Major bootloader version for BMS";
CM_ SG_ 2508193797 BATT_appRevision_bootup_5 "Revision app version for BMS";
CM_ SG_ 2508193797 BATT_appMinor_bootup_5 "Minor app version for BMS";
CM_ SG_ 2508193797 BATT_appMajor_bootup_5 "Major app version for BMS";
CM_ BO_ 2508193798 "Bootloader and BMS application firmware versions";
CM_ SG_ 2508193798 BATT_bootloaderRevision_bootup_6 "Revision bootloader version for BMS";
CM_ SG_ 2508193798 BATT_bootloaderMinor_bootup_6 "Minor bootloader version for BMS";
CM_ SG_ 2508193798 BATT_bootloaderMajor_bootup_6 "Major bootloader version for BMS";
CM_ SG_ 2508193798 BATT_appRevision_bootup_6 "Revision app version for BMS";
CM_ SG_ 2508193798 BATT_appMinor_bootup_6 "Minor app version for BMS";
CM_ SG_ 2508193798 BATT_appMajor_bootup_6 "Major app version for BMS";
CM_ BO_ 2508193799 "Bootloader and BMS application firmware versions";
CM_ SG_ 2508193799 BATT_bootloaderRevision_bootup_7 "Revision bootloader version for BMS";
CM_ SG_ 2508193799 BATT_bootloaderMinor_bootup_7 "Minor bootloader version for BMS";
CM_ SG_ 2508193799 BATT_bootloaderMajor_bootup_7 "Major bootloader version for BMS";
CM_ SG_ 2508193799 BATT_appRevision_bootup_7 "Revision app version for BMS";
CM_ SG_ 2508193799 BATT_appMinor_bootup_7 "Minor app version for BMS";
CM_ SG_ 2508193799 BATT_appMajor_bootup_7 "Major app version for BMS";
CM_ BO_ 2508193800 "Bootloader and BMS application firmware versions";
CM_ SG_ 2508193800 BATT_bootloaderRevision_bootup_8 "Revision bootloader version for BMS";
CM_ SG_ 2508193800 BATT_bootloaderMinor_bootup_8 "Minor bootloader version for BMS";
CM_ SG_ 2508193800 BATT_bootloaderMajor_bootup_8 "Major bootloader version for BMS";
CM_ SG_ 2508193800 BATT_appRevision_bootup_8 "Revision app version for BMS";
CM_ SG_ 2508193800 BATT_appMinor_bootup_8 "Minor app version for BMS";
CM_ SG_ 2508193800 BATT_appMajor_bootup_8 "Major app version for BMS";
CM_ BO_ 2508193801 "Bootloader and BMS application firmware versions";
CM_ SG_ 2508193801 BATT_bootloaderRevision_bootup_9 "Revision bootloader version for BMS";
CM_ SG_ 2508193801 BATT_bootloaderMinor_bootup_9 "Minor bootloader version for BMS";
CM_ SG_ 2508193801 BATT_bootloaderMajor_bootup_9 "Major bootloader version for BMS";
CM_ SG_ 2508193801 BATT_appRevision_bootup_9 "Revision app version for BMS";
CM_ SG_ 2508193801 BATT_appMinor_bootup_9 "Minor app version for BMS";
CM_ SG_ 2508193801 BATT_appMajor_bootup_9 "Major app version for BMS";
CM_ BO_ 2508193802 "Bootloader and BMS application firmware versions";
CM_ SG_ 2508193802 BATT_bootloaderRevision_bootup_10 "Revision bootloader version for BMS";
CM_ SG_ 2508193802 BATT_bootloaderMinor_bootup_10 "Minor bootloader version for BMS";
CM_ SG_ 2508193802 BATT_bootloaderMajor_bootup_10 "Major bootloader version for BMS";
CM_ SG_ 2508193802 BATT_appRevision_bootup_10 "Revision app version for BMS";
CM_ SG_ 2508193802 BATT_appMinor_bootup_10 "Minor app version for BMS";
CM_ SG_ 2508193802 BATT_appMajor_bootup_10 "Major app version for BMS";
CM_ BO_ 2508193803 "Bootloader and BMS application firmware versions";
CM_ SG_ 2508193803 BATT_bootloaderRevision_bootup_11 "Revision bootloader version for BMS";
CM_ SG_ 2508193803 BATT_bootloaderMinor_bootup_11 "Minor bootloader version for BMS";
CM_ SG_ 2508193803 BATT_bootloaderMajor_bootup_11 "Major bootloader version for BMS";
CM_ SG_ 2508193803 BATT_appRevision_bootup_11 "Revision app version for BMS";
CM_ SG_ 2508193803 BATT_appMinor_bootup_11 "Minor app version for BMS";
CM_ SG_ 2508193803 BATT_appMajor_bootup_11 "Major app version for BMS";
CM_ SG_ 2550398976 BATT_manufacturerName_0 "Manufacturer name string. Length prefixed strings will work for strict SMBus and SPI, how to handle for CAN?";
CM_ SG_ 2550398976 BATT_manufacturerAccess_0 "Content determined by the Smart Battery's manufacturer";
CM_ SG_ 2550398976 BATT_manufactureYear_0 "Manufacture year biased by 1980";
CM_ SG_ 2550398976 BATT_manufactureMonth_0 "Manufacture month";
CM_ SG_ 2550398976 BATT_manufactureDay_0 "Manufacture day";
CM_ SG_ 2550398977 BATT_manufacturerName_1 "Manufacturer name string. Length prefixed strings will work for strict SMBus and SPI, how to handle for CAN?";
CM_ SG_ 2550398977 BATT_manufacturerAccess_1 "Content determined by the Smart Battery's manufacturer";
CM_ SG_ 2550398977 BATT_manufactureYear_1 "Manufacture year biased by 1980";
CM_ SG_ 2550398977 BATT_manufactureMonth_1 "Manufacture month";
CM_ SG_ 2550398977 BATT_manufactureDay_1 "Manufacture day";
CM_ SG_ 2550398978 BATT_manufacturerName_2 "Manufacturer name string. Length prefixed strings will work for strict SMBus and SPI, how to handle for CAN?";
CM_ SG_ 2550398978 BATT_manufacturerAccess_2 "Content determined by the Smart Battery's manufacturer";
CM_ SG_ 2550398978 BATT_manufactureYear_2 "Manufacture year biased by 1980";
CM_ SG_ 2550398978 BATT_manufactureMonth_2 "Manufacture month";
CM_ SG_ 2550398978 BATT_manufactureDay_2 "Manufacture day";
CM_ SG_ 2550398979 BATT_manufacturerName_3 "Manufacturer name string. Length prefixed strings will work for strict SMBus and SPI, how to handle for CAN?";
CM_ SG_ 2550398979 BATT_manufacturerAccess_3 "Content determined by the Smart Battery's manufacturer";
CM_ SG_ 2550398979 BATT_manufactureYear_3 "Manufacture year biased by 1980";
CM_ SG_ 2550398979 BATT_manufactureMonth_3 "Manufacture month";
CM_ SG_ 2550398979 BATT_manufactureDay_3 "Manufacture day";
CM_ SG_ 2550398980 BATT_manufacturerName_4 "Manufacturer name string. Length prefixed strings will work for strict SMBus and SPI, how to handle for CAN?";
CM_ SG_ 2550398980 BATT_manufacturerAccess_4 "Content determined by the Smart Battery's manufacturer";
CM_ SG_ 2550398980 BATT_manufactureYear_4 "Manufacture year biased by 1980";
CM_ SG_ 2550398980 BATT_manufactureMonth_4 "Manufacture month";
CM_ SG_ 2550398980 BATT_manufactureDay_4 "Manufacture day";
CM_ SG_ 2550398981 BATT_manufacturerName_5 "Manufacturer name string. Length prefixed strings will work for strict SMBus and SPI, how to handle for CAN?";
CM_ SG_ 2550398981 BATT_manufacturerAccess_5 "Content determined by the Smart Battery's manufacturer";
CM_ SG_ 2550398981 BATT_manufactureYear_5 "Manufacture year biased by 1980";
CM_ SG_ 2550398981 BATT_manufactureMonth_5 "Manufacture month";
CM_ SG_ 2550398981 BATT_manufactureDay_5 "Manufacture day";
CM_ SG_ 2550398982 BATT_manufacturerName_6 "Manufacturer name string. Length prefixed strings will work for strict SMBus and SPI, how to handle for CAN?";
CM_ SG_ 2550398982 BATT_manufacturerAccess_6 "Content determined by the Smart Battery's manufacturer";
CM_ SG_ 2550398982 BATT_manufactureYear_6 "Manufacture year biased by 1980";
CM_ SG_ 2550398982 BATT_manufactureMonth_6 "Manufacture month";
CM_ SG_ 2550398982 BATT_manufactureDay_6 "Manufacture day";
CM_ SG_ 2550398983 BATT_manufacturerName_7 "Manufacturer name string. Length prefixed strings will work for strict SMBus and SPI, how to handle for CAN?";
CM_ SG_ 2550398983 BATT_manufacturerAccess_7 "Content determined by the Smart Battery's manufacturer";
CM_ SG_ 2550398983 BATT_manufactureYear_7 "Manufacture year biased by 1980";
CM_ SG_ 2550398983 BATT_manufactureMonth_7 "Manufacture month";
CM_ SG_ 2550398983 BATT_manufactureDay_7 "Manufacture day";
CM_ SG_ 2550398984 BATT_manufacturerName_8 "Manufacturer name string. Length prefixed strings will work for strict SMBus and SPI, how to handle for CAN?";
CM_ SG_ 2550398984 BATT_manufacturerAccess_8 "Content determined by the Smart Battery's manufacturer";
CM_ SG_ 2550398984 BATT_manufactureYear_8 "Manufacture year biased by 1980";
CM_ SG_ 2550398984 BATT_manufactureMonth_8 "Manufacture month";
CM_ SG_ 2550398984 BATT_manufactureDay_8 "Manufacture day";
CM_ SG_ 2550398985 BATT_manufacturerName_9 "Manufacturer name string. Length prefixed strings will work for strict SMBus and SPI, how to handle for CAN?";
CM_ SG_ 2550398985 BATT_manufacturerAccess_9 "Content determined by the Smart Battery's manufacturer";
CM_ SG_ 2550398985 BATT_manufactureYear_9 "Manufacture year biased by 1980";
CM_ SG_ 2550398985 BATT_manufactureMonth_9 "Manufacture month";
CM_ SG_ 2550398985 BATT_manufactureDay_9 "Manufacture day";
CM_ SG_ 2550398986 BATT_manufacturerName_10 "Manufacturer name string. Length prefixed strings will work for strict SMBus and SPI, how to handle for CAN?";
CM_ SG_ 2550398986 BATT_manufacturerAccess_10 "Content determined by the Smart Battery's manufacturer";
CM_ SG_ 2550398986 BATT_manufactureYear_10 "Manufacture year biased by 1980";
CM_ SG_ 2550398986 BATT_manufactureMonth_10 "Manufacture month";
CM_ SG_ 2550398986 BATT_manufactureDay_10 "Manufacture day";
CM_ SG_ 2550398987 BATT_manufacturerName_11 "Manufacturer name string. Length prefixed strings will work for strict SMBus and SPI, how to handle for CAN?";
CM_ SG_ 2550398987 BATT_manufacturerAccess_11 "Content determined by the Smart Battery's manufacturer";
CM_ SG_ 2550398987 BATT_manufactureYear_11 "Manufacture year biased by 1980";
CM_ SG_ 2550398987 BATT_manufactureMonth_11 "Manufacture month";
CM_ SG_ 2550398987 BATT_manufactureDay_11 "Manufacture day";
CM_ SG_ 2550661120 BATT_IGNLO_Status_0 "0 - Unkown
1 - Standby
2 - Drive
3 - Arbitration
";
CM_ SG_ 2550661120 BATT_serialNumber_0 "Unique serial number";
CM_ SG_ 2550661120 BATT_expectedModule_0 "Expected number of modules";
CM_ SG_ 2550661120 BATT_deviceChemistry_0 "Device chemistry.  Note strict SMBus handles this with a character string";
CM_ SG_ 2550661121 BATT_IGNLO_Status_1 "0 - Unkown
1 - Standby
2 - Drive
3 - Arbitration
";
CM_ SG_ 2550661121 BATT_serialNumber_1 "Unique serial number";
CM_ SG_ 2550661121 BATT_expectedModule_1 "Expected number of modules";
CM_ SG_ 2550661121 BATT_deviceChemistry_1 "Device chemistry.  Note strict SMBus handles this with a character string";
CM_ SG_ 2550661122 BATT_IGNLO_Status_2 "0 - Unkown
1 - Standby
2 - Drive
3 - Arbitration
";
CM_ SG_ 2550661122 BATT_serialNumber_2 "Unique serial number";
CM_ SG_ 2550661122 BATT_expectedModule_2 "Expected number of modules";
CM_ SG_ 2550661122 BATT_deviceChemistry_2 "Device chemistry.  Note strict SMBus handles this with a character string";
CM_ SG_ 2550661123 BATT_IGNLO_Status_3 "0 - Unkown
1 - Standby
2 - Drive
3 - Arbitration
";
CM_ SG_ 2550661123 BATT_serialNumber_3 "Unique serial number";
CM_ SG_ 2550661123 BATT_expectedModule_3 "Expected number of modules";
CM_ SG_ 2550661123 BATT_deviceChemistry_3 "Device chemistry.  Note strict SMBus handles this with a character string";
CM_ SG_ 2550661124 BATT_IGNLO_Status_4 "0 - Unkown
1 - Standby
2 - Drive
3 - Arbitration
";
CM_ SG_ 2550661124 BATT_serialNumber_4 "Unique serial number";
CM_ SG_ 2550661124 BATT_expectedModule_4 "Expected number of modules";
CM_ SG_ 2550661124 BATT_deviceChemistry_4 "Device chemistry.  Note strict SMBus handles this with a character string";
CM_ SG_ 2550661125 BATT_IGNLO_Status_5 "0 - Unkown
1 - Standby
2 - Drive
3 - Arbitration
";
CM_ SG_ 2550661125 BATT_serialNumber_5 "Unique serial number";
CM_ SG_ 2550661125 BATT_expectedModule_5 "Expected number of modules";
CM_ SG_ 2550661125 BATT_deviceChemistry_5 "Device chemistry.  Note strict SMBus handles this with a character string";
CM_ SG_ 2550661126 BATT_IGNLO_Status_6 "0 - Unkown
1 - Standby
2 - Drive
3 - Arbitration
";
CM_ SG_ 2550661126 BATT_serialNumber_6 "Unique serial number";
CM_ SG_ 2550661126 BATT_expectedModule_6 "Expected number of modules";
CM_ SG_ 2550661126 BATT_deviceChemistry_6 "Device chemistry.  Note strict SMBus handles this with a character string";
CM_ SG_ 2550661127 BATT_IGNLO_Status_7 "0 - Unkown
1 - Standby
2 - Drive
3 - Arbitration
";
CM_ SG_ 2550661127 BATT_serialNumber_7 "Unique serial number";
CM_ SG_ 2550661127 BATT_expectedModule_7 "Expected number of modules";
CM_ SG_ 2550661127 BATT_deviceChemistry_7 "Device chemistry.  Note strict SMBus handles this with a character string";
CM_ SG_ 2550661128 BATT_IGNLO_Status_8 "0 - Unkown
1 - Standby
2 - Drive
3 - Arbitration
";
CM_ SG_ 2550661128 BATT_serialNumber_8 "Unique serial number";
CM_ SG_ 2550661128 BATT_expectedModule_8 "Expected number of modules";
CM_ SG_ 2550661128 BATT_deviceChemistry_8 "Device chemistry.  Note strict SMBus handles this with a character string";
CM_ SG_ 2550661129 BATT_IGNLO_Status_9 "0 - Unkown
1 - Standby
2 - Drive
3 - Arbitration
";
CM_ SG_ 2550661129 BATT_serialNumber_9 "Unique serial number";
CM_ SG_ 2550661129 BATT_expectedModule_9 "Expected number of modules";
CM_ SG_ 2550661129 BATT_deviceChemistry_9 "Device chemistry.  Note strict SMBus handles this with a character string";
CM_ SG_ 2550661130 BATT_IGNLO_Status_10 "0 - Unkown
1 - Standby
2 - Drive
3 - Arbitration
";
CM_ SG_ 2550661130 BATT_serialNumber_10 "Unique serial number";
CM_ SG_ 2550661130 BATT_expectedModule_10 "Expected number of modules";
CM_ SG_ 2550661130 BATT_deviceChemistry_10 "Device chemistry.  Note strict SMBus handles this with a character string";
CM_ SG_ 2550661131 BATT_IGNLO_Status_11 "0 - Unkown
1 - Standby
2 - Drive
3 - Arbitration
";
CM_ SG_ 2550661131 BATT_serialNumber_11 "Unique serial number";
CM_ SG_ 2550661131 BATT_expectedModule_11 "Expected number of modules";
CM_ SG_ 2550661131 BATT_deviceChemistry_11 "Device chemistry.  Note strict SMBus handles this with a character string";

BA_DEF_ BO_  "GenMsgDiag" ENUM "No","Yes";
BA_DEF_ BO_  "GenMsgInstanced" STRING ;
BA_DEF_ SG_  "GenSigType" ENUM "Extended","Diagnostic","Standard","Modified";
BA_DEF_ BO_  "GenMsgCycleTime" INT 0 0;
BA_DEF_ SG_  "GenSigSNA" INT 0 65535;
BA_DEF_ SG_  "Access" ENUM "r","rw";
BA_DEF_DEF_  "GenMsgDiag" "No";
BA_DEF_DEF_  "GenMsgInstanced" "No";
BA_DEF_DEF_  "GenSigType" "Standard";
BA_DEF_DEF_  "GenMsgCycleTime" 0;
BA_DEF_DEF_  "GenSigSNA" 0;
BA_DEF_DEF_  "Access" "r";
BA_ "GenMsgDiag" BO_ 2550398976 1;
BA_ "GenMsgDiag" BO_ 2550398977 1;
BA_ "GenMsgDiag" BO_ 2550398978 1;
BA_ "GenMsgDiag" BO_ 2550398979 1;
BA_ "GenMsgDiag" BO_ 2550398980 1;
BA_ "GenMsgDiag" BO_ 2550398981 1;
BA_ "GenMsgDiag" BO_ 2550398982 1;
BA_ "GenMsgDiag" BO_ 2550398983 1;
BA_ "GenMsgDiag" BO_ 2550398984 1;
BA_ "GenMsgDiag" BO_ 2550398985 1;
BA_ "GenMsgDiag" BO_ 2550398986 1;
BA_ "GenMsgDiag" BO_ 2550398987 1;
BA_ "GenMsgInstanced" BO_ 2224291846 "False";
BA_ "GenMsgInstanced" BO_ 2224291847 "False";
BA_ "GenMsgInstanced" BO_ 2224291848 "False";
BA_ "GenMsgInstanced" BO_ 2224291849 "False";
BA_ "GenMsgInstanced" BO_ 2224291850 "False";
BA_ "GenMsgInstanced" BO_ 2224291851 "False";
BA_ "GenMsgInstanced" BO_ 2232680448 "False";
BA_ "GenMsgInstanced" BO_ 2232680449 "False";
BA_ "GenMsgInstanced" BO_ 2232680450 "False";
BA_ "GenMsgInstanced" BO_ 2232680451 "False";
BA_ "GenMsgInstanced" BO_ 2232680452 "False";
BA_ "GenMsgInstanced" BO_ 2232680453 "False";
BA_ "GenMsgInstanced" BO_ 2232680454 "False";
BA_ "GenMsgInstanced" BO_ 2232680455 "False";
BA_ "GenMsgInstanced" BO_ 2232680456 "False";
BA_ "GenMsgInstanced" BO_ 2232680457 "False";
BA_ "GenMsgInstanced" BO_ 2232680458 "False";
BA_ "GenMsgInstanced" BO_ 2232680459 "False";
BA_ "GenMsgInstanced" BO_ 2236874752 "False";
BA_ "GenMsgInstanced" BO_ 2236874753 "False";
BA_ "GenMsgInstanced" BO_ 2236874754 "False";
BA_ "GenMsgInstanced" BO_ 2236874755 "False";
BA_ "GenMsgInstanced" BO_ 2236874756 "False";
BA_ "GenMsgInstanced" BO_ 2236874757 "False";
BA_ "GenMsgInstanced" BO_ 2236874758 "False";
BA_ "GenMsgInstanced" BO_ 2236874759 "False";
BA_ "GenMsgInstanced" BO_ 2236874760 "False";
BA_ "GenMsgInstanced" BO_ 2236874761 "False";
BA_ "GenMsgInstanced" BO_ 2236874762 "False";
BA_ "GenMsgInstanced" BO_ 2236874763 "False";
BA_ "GenMsgInstanced" BO_ 2483290112 "False";
BA_ "GenMsgInstanced" BO_ 2483290113 "False";
BA_ "GenMsgInstanced" BO_ 2483290114 "False";
BA_ "GenMsgInstanced" BO_ 2483290115 "False";
BA_ "GenMsgInstanced" BO_ 2483290116 "False";
BA_ "GenMsgInstanced" BO_ 2483290117 "False";
BA_ "GenMsgInstanced" BO_ 2483290118 "False";
BA_ "GenMsgInstanced" BO_ 2483290119 "False";
BA_ "GenMsgInstanced" BO_ 2483290120 "False";
BA_ "GenMsgInstanced" BO_ 2483290121 "False";
BA_ "GenMsgInstanced" BO_ 2483290122 "False";
BA_ "GenMsgInstanced" BO_ 2483290123 "False";
BA_ "GenMsgInstanced" BO_ 2487484416 "False";
BA_ "GenMsgInstanced" BO_ 2487484417 "False";
BA_ "GenMsgInstanced" BO_ 2487484418 "False";
BA_ "GenMsgInstanced" BO_ 2487484419 "False";
BA_ "GenMsgInstanced" BO_ 2487484420 "False";
BA_ "GenMsgInstanced" BO_ 2487484421 "False";
BA_ "GenMsgInstanced" BO_ 2487484422 "False";
BA_ "GenMsgInstanced" BO_ 2487484423 "False";
BA_ "GenMsgInstanced" BO_ 2487484424 "False";
BA_ "GenMsgInstanced" BO_ 2487484425 "False";
BA_ "GenMsgInstanced" BO_ 2487484426 "False";
BA_ "GenMsgInstanced" BO_ 2487484427 "False";
BA_ "GenMsgInstanced" BO_ 2508193792 "False";
BA_ "GenMsgInstanced" BO_ 2508193793 "False";
BA_ "GenMsgInstanced" BO_ 2508193794 "False";
BA_ "GenMsgInstanced" BO_ 2508193795 "False";
BA_ "GenMsgInstanced" BO_ 2508193796 "False";
BA_ "GenMsgInstanced" BO_ 2508193797 "False";
BA_ "GenMsgInstanced" BO_ 2508193798 "False";
BA_ "GenMsgInstanced" BO_ 2508193799 "False";
BA_ "GenMsgInstanced" BO_ 2508193800 "False";
BA_ "GenMsgInstanced" BO_ 2508193801 "False";
BA_ "GenMsgInstanced" BO_ 2508193802 "False";
BA_ "GenMsgInstanced" BO_ 2508193803 "False";
BA_ "GenMsgInstanced" BO_ 2550398976 "False";
BA_ "GenMsgInstanced" BO_ 2550398977 "False";
BA_ "GenMsgInstanced" BO_ 2550398978 "False";
BA_ "GenMsgInstanced" BO_ 2550398979 "False";
BA_ "GenMsgInstanced" BO_ 2550398980 "False";
BA_ "GenMsgInstanced" BO_ 2550398981 "False";
BA_ "GenMsgInstanced" BO_ 2550398982 "False";
BA_ "GenMsgInstanced" BO_ 2550398983 "False";
BA_ "GenMsgInstanced" BO_ 2550398984 "False";
BA_ "GenMsgInstanced" BO_ 2550398985 "False";
BA_ "GenMsgInstanced" BO_ 2550398986 "False";
BA_ "GenMsgInstanced" BO_ 2550398987 "False";
BA_ "GenMsgInstanced" BO_ 2550661120 "False";
BA_ "GenMsgInstanced" BO_ 2550661121 "False";
BA_ "GenMsgInstanced" BO_ 2550661122 "False";
BA_ "GenMsgInstanced" BO_ 2550661123 "False";
BA_ "GenMsgInstanced" BO_ 2550661124 "False";
BA_ "GenMsgInstanced" BO_ 2550661125 "False";
BA_ "GenMsgInstanced" BO_ 2550661126 "False";
BA_ "GenMsgInstanced" BO_ 2550661127 "False";
BA_ "GenMsgInstanced" BO_ 2550661128 "False";
BA_ "GenMsgInstanced" BO_ 2550661129 "False";
BA_ "GenMsgInstanced" BO_ 2550661130 "False";
BA_ "GenMsgInstanced" BO_ 2550661131 "False";
BA_ "GenMsgInstanced" BO_ 2551447552 "False";
BA_ "GenMsgInstanced" BO_ 2551447553 "False";
BA_ "GenMsgInstanced" BO_ 2551447554 "False";
BA_ "GenMsgInstanced" BO_ 2551447555 "False";
BA_ "GenMsgInstanced" BO_ 2551447556 "False";
BA_ "GenMsgInstanced" BO_ 2551447557 "False";
BA_ "GenMsgInstanced" BO_ 2551447558 "False";
BA_ "GenMsgInstanced" BO_ 2551447559 "False";
BA_ "GenMsgInstanced" BO_ 2551447560 "False";
BA_ "GenMsgInstanced" BO_ 2551447561 "False";
BA_ "GenMsgInstanced" BO_ 2551447562 "False";
BA_ "GenMsgInstanced" BO_ 2551447563 "False";
BA_ "GenMsgCycleTime" BO_ 2224291846 100;
BA_ "GenMsgCycleTime" BO_ 2224291847 100;
BA_ "GenMsgCycleTime" BO_ 2224291848 100;
BA_ "GenMsgCycleTime" BO_ 2224291849 100;
BA_ "GenMsgCycleTime" BO_ 2224291850 100;
BA_ "GenMsgCycleTime" BO_ 2224291851 100;
BA_ "GenMsgCycleTime" BO_ 2483290112 100;
BA_ "GenMsgCycleTime" BO_ 2483290113 100;
BA_ "GenMsgCycleTime" BO_ 2483290114 100;
BA_ "GenMsgCycleTime" BO_ 2483290115 100;
BA_ "GenMsgCycleTime" BO_ 2483290116 100;
BA_ "GenMsgCycleTime" BO_ 2483290117 100;
BA_ "GenMsgCycleTime" BO_ 2483290118 100;
BA_ "GenMsgCycleTime" BO_ 2483290119 100;
BA_ "GenMsgCycleTime" BO_ 2483290120 100;
BA_ "GenMsgCycleTime" BO_ 2483290121 100;
BA_ "GenMsgCycleTime" BO_ 2483290122 100;
BA_ "GenMsgCycleTime" BO_ 2483290123 100;
BA_ "GenSigType" SG_ 2224291846 BATT_tModuleMax_6 0;
BA_ "GenSigType" SG_ 2224291846 BATT_tModuleMin_6 0;
BA_ "GenSigType" SG_ 2224291846 BATT_vBrickMinID_6 0;
BA_ "GenSigType" SG_ 2224291846 BATT_vBrickMaxID_6 0;
BA_ "GenSigType" SG_ 2224291846 BATT_tModuleMaxID_6 0;
BA_ "GenSigType" SG_ 2224291846 BATT_tModuleMinID_6 0;
BA_ "GenSigType" SG_ 2224291846 BATT_vBrickMin_6 0;
BA_ "GenSigType" SG_ 2224291846 BATT_vBrickMax_6 0;
BA_ "GenSigType" SG_ 2224291847 BATT_tModuleMinID_7 0;
BA_ "GenSigType" SG_ 2224291847 BATT_vBrickMaxID_7 0;
BA_ "GenSigType" SG_ 2224291847 BATT_tModuleMax_7 0;
BA_ "GenSigType" SG_ 2224291847 BATT_vBrickMinID_7 0;
BA_ "GenSigType" SG_ 2224291847 BATT_tModuleMin_7 0;
BA_ "GenSigType" SG_ 2224291847 BATT_tModuleMaxID_7 0;
BA_ "GenSigType" SG_ 2224291847 BATT_vBrickMax_7 0;
BA_ "GenSigType" SG_ 2224291847 BATT_vBrickMin_7 0;
BA_ "GenSigType" SG_ 2224291848 BATT_tModuleMax_8 0;
BA_ "GenSigType" SG_ 2224291848 BATT_tModuleMin_8 0;
BA_ "GenSigType" SG_ 2224291848 BATT_tModuleMinID_8 0;
BA_ "GenSigType" SG_ 2224291848 BATT_tModuleMaxID_8 0;
BA_ "GenSigType" SG_ 2224291848 BATT_vBrickMax_8 0;
BA_ "GenSigType" SG_ 2224291848 BATT_vBrickMin_8 0;
BA_ "GenSigType" SG_ 2224291848 BATT_vBrickMaxID_8 0;
BA_ "GenSigType" SG_ 2224291848 BATT_vBrickMinID_8 0;
BA_ "GenSigType" SG_ 2224291849 BATT_vBrickMax_9 0;
BA_ "GenSigType" SG_ 2224291849 BATT_vBrickMin_9 0;
BA_ "GenSigType" SG_ 2224291849 BATT_tModuleMaxID_9 0;
BA_ "GenSigType" SG_ 2224291849 BATT_tModuleMinID_9 0;
BA_ "GenSigType" SG_ 2224291849 BATT_vBrickMinID_9 0;
BA_ "GenSigType" SG_ 2224291849 BATT_vBrickMaxID_9 0;
BA_ "GenSigType" SG_ 2224291849 BATT_tModuleMin_9 0;
BA_ "GenSigType" SG_ 2224291849 BATT_tModuleMax_9 0;
BA_ "GenSigType" SG_ 2224291850 BATT_vBrickMax_10 0;
BA_ "GenSigType" SG_ 2224291850 BATT_tModuleMin_10 0;
BA_ "GenSigType" SG_ 2224291850 BATT_tModuleMax_10 0;
BA_ "GenSigType" SG_ 2224291850 BATT_vBrickMin_10 0;
BA_ "GenSigType" SG_ 2224291850 BATT_tModuleMaxID_10 0;
BA_ "GenSigType" SG_ 2224291850 BATT_tModuleMinID_10 0;
BA_ "GenSigType" SG_ 2224291850 BATT_vBrickMaxID_10 0;
BA_ "GenSigType" SG_ 2224291850 BATT_vBrickMinID_10 0;
BA_ "GenSigType" SG_ 2224291851 BATT_vBrickMin_11 0;
BA_ "GenSigType" SG_ 2224291851 BATT_vBrickMax_11 0;
BA_ "GenSigType" SG_ 2224291851 BATT_vBrickMinID_11 0;
BA_ "GenSigType" SG_ 2224291851 BATT_tModuleMin_11 0;
BA_ "GenSigType" SG_ 2224291851 BATT_vBrickMaxID_11 0;
BA_ "GenSigType" SG_ 2224291851 BATT_tModuleMax_11 0;
BA_ "GenSigType" SG_ 2224291851 BATT_tModuleMaxID_11 0;
BA_ "GenSigType" SG_ 2224291851 BATT_tModuleMinID_11 0;
BA_ "GenSigType" SG_ 2232680448 BATT_bootTotalFaultCnt_0 0;
BA_ "GenSigType" SG_ 2232680448 BATT_bootFaultCnt_0 0;
BA_ "GenSigType" SG_ 2232680448 BATT_bootloaderRevision_0 0;
BA_ "GenSigType" SG_ 2232680448 BATT_bootloaderMinor_0 0;
BA_ "GenSigType" SG_ 2232680448 BATT_bootloaderMajor_0 0;
BA_ "GenSigType" SG_ 2232680448 BATT_appRevision_0 0;
BA_ "GenSigType" SG_ 2232680448 BATT_appMinor_0 0;
BA_ "GenSigType" SG_ 2232680448 BATT_appMajor_0 0;
BA_ "GenSigType" SG_ 2232680449 BATT_bootTotalFaultCnt_1 0;
BA_ "GenSigType" SG_ 2232680449 BATT_bootFaultCnt_1 0;
BA_ "GenSigType" SG_ 2232680449 BATT_bootloaderRevision_1 0;
BA_ "GenSigType" SG_ 2232680449 BATT_bootloaderMinor_1 0;
BA_ "GenSigType" SG_ 2232680449 BATT_bootloaderMajor_1 0;
BA_ "GenSigType" SG_ 2232680449 BATT_appRevision_1 0;
BA_ "GenSigType" SG_ 2232680449 BATT_appMinor_1 0;
BA_ "GenSigType" SG_ 2232680449 BATT_appMajor_1 0;
BA_ "GenSigType" SG_ 2232680450 BATT_bootTotalFaultCnt_2 0;
BA_ "GenSigType" SG_ 2232680450 BATT_bootFaultCnt_2 0;
BA_ "GenSigType" SG_ 2232680450 BATT_bootloaderRevision_2 0;
BA_ "GenSigType" SG_ 2232680450 BATT_bootloaderMinor_2 0;
BA_ "GenSigType" SG_ 2232680450 BATT_bootloaderMajor_2 0;
BA_ "GenSigType" SG_ 2232680450 BATT_appRevision_2 0;
BA_ "GenSigType" SG_ 2232680450 BATT_appMinor_2 0;
BA_ "GenSigType" SG_ 2232680450 BATT_appMajor_2 0;
BA_ "GenSigType" SG_ 2232680451 BATT_bootTotalFaultCnt_3 0;
BA_ "GenSigType" SG_ 2232680451 BATT_bootFaultCnt_3 0;
BA_ "GenSigType" SG_ 2232680451 BATT_bootloaderRevision_3 0;
BA_ "GenSigType" SG_ 2232680451 BATT_bootloaderMinor_3 0;
BA_ "GenSigType" SG_ 2232680451 BATT_bootloaderMajor_3 0;
BA_ "GenSigType" SG_ 2232680451 BATT_appRevision_3 0;
BA_ "GenSigType" SG_ 2232680451 BATT_appMinor_3 0;
BA_ "GenSigType" SG_ 2232680451 BATT_appMajor_3 0;
BA_ "GenSigType" SG_ 2232680452 BATT_bootTotalFaultCnt_4 0;
BA_ "GenSigType" SG_ 2232680452 BATT_bootFaultCnt_4 0;
BA_ "GenSigType" SG_ 2232680452 BATT_bootloaderRevision_4 0;
BA_ "GenSigType" SG_ 2232680452 BATT_bootloaderMinor_4 0;
BA_ "GenSigType" SG_ 2232680452 BATT_bootloaderMajor_4 0;
BA_ "GenSigType" SG_ 2232680452 BATT_appRevision_4 0;
BA_ "GenSigType" SG_ 2232680452 BATT_appMinor_4 0;
BA_ "GenSigType" SG_ 2232680452 BATT_appMajor_4 0;
BA_ "GenSigType" SG_ 2232680453 BATT_bootTotalFaultCnt_5 0;
BA_ "GenSigType" SG_ 2232680453 BATT_bootFaultCnt_5 0;
BA_ "GenSigType" SG_ 2232680453 BATT_bootloaderRevision_5 0;
BA_ "GenSigType" SG_ 2232680453 BATT_bootloaderMinor_5 0;
BA_ "GenSigType" SG_ 2232680453 BATT_bootloaderMajor_5 0;
BA_ "GenSigType" SG_ 2232680453 BATT_appRevision_5 0;
BA_ "GenSigType" SG_ 2232680453 BATT_appMinor_5 0;
BA_ "GenSigType" SG_ 2232680453 BATT_appMajor_5 0;
BA_ "GenSigType" SG_ 2232680454 BATT_bootTotalFaultCnt_6 0;
BA_ "GenSigType" SG_ 2232680454 BATT_bootFaultCnt_6 0;
BA_ "GenSigType" SG_ 2232680454 BATT_bootloaderRevision_6 0;
BA_ "GenSigType" SG_ 2232680454 BATT_bootloaderMinor_6 0;
BA_ "GenSigType" SG_ 2232680454 BATT_bootloaderMajor_6 0;
BA_ "GenSigType" SG_ 2232680454 BATT_appRevision_6 0;
BA_ "GenSigType" SG_ 2232680454 BATT_appMinor_6 0;
BA_ "GenSigType" SG_ 2232680454 BATT_appMajor_6 0;
BA_ "GenSigType" SG_ 2232680455 BATT_bootTotalFaultCnt_7 0;
BA_ "GenSigType" SG_ 2232680455 BATT_bootFaultCnt_7 0;
BA_ "GenSigType" SG_ 2232680455 BATT_bootloaderRevision_7 0;
BA_ "GenSigType" SG_ 2232680455 BATT_bootloaderMinor_7 0;
BA_ "GenSigType" SG_ 2232680455 BATT_bootloaderMajor_7 0;
BA_ "GenSigType" SG_ 2232680455 BATT_appRevision_7 0;
BA_ "GenSigType" SG_ 2232680455 BATT_appMinor_7 0;
BA_ "GenSigType" SG_ 2232680455 BATT_appMajor_7 0;
BA_ "GenSigType" SG_ 2232680456 BATT_bootTotalFaultCnt_8 0;
BA_ "GenSigType" SG_ 2232680456 BATT_bootFaultCnt_8 0;
BA_ "GenSigType" SG_ 2232680456 BATT_bootloaderRevision_8 0;
BA_ "GenSigType" SG_ 2232680456 BATT_bootloaderMinor_8 0;
BA_ "GenSigType" SG_ 2232680456 BATT_bootloaderMajor_8 0;
BA_ "GenSigType" SG_ 2232680456 BATT_appRevision_8 0;
BA_ "GenSigType" SG_ 2232680456 BATT_appMinor_8 0;
BA_ "GenSigType" SG_ 2232680456 BATT_appMajor_8 0;
BA_ "GenSigType" SG_ 2232680457 BATT_bootTotalFaultCnt_9 0;
BA_ "GenSigType" SG_ 2232680457 BATT_bootFaultCnt_9 0;
BA_ "GenSigType" SG_ 2232680457 BATT_bootloaderRevision_9 0;
BA_ "GenSigType" SG_ 2232680457 BATT_bootloaderMinor_9 0;
BA_ "GenSigType" SG_ 2232680457 BATT_bootloaderMajor_9 0;
BA_ "GenSigType" SG_ 2232680457 BATT_appRevision_9 0;
BA_ "GenSigType" SG_ 2232680457 BATT_appMinor_9 0;
BA_ "GenSigType" SG_ 2232680457 BATT_appMajor_9 0;
BA_ "GenSigType" SG_ 2232680458 BATT_bootTotalFaultCnt_10 0;
BA_ "GenSigType" SG_ 2232680458 BATT_bootFaultCnt_10 0;
BA_ "GenSigType" SG_ 2232680458 BATT_bootloaderRevision_10 0;
BA_ "GenSigType" SG_ 2232680458 BATT_bootloaderMinor_10 0;
BA_ "GenSigType" SG_ 2232680458 BATT_bootloaderMajor_10 0;
BA_ "GenSigType" SG_ 2232680458 BATT_appRevision_10 0;
BA_ "GenSigType" SG_ 2232680458 BATT_appMinor_10 0;
BA_ "GenSigType" SG_ 2232680458 BATT_appMajor_10 0;
BA_ "GenSigType" SG_ 2232680459 BATT_bootTotalFaultCnt_11 0;
BA_ "GenSigType" SG_ 2232680459 BATT_bootFaultCnt_11 0;
BA_ "GenSigType" SG_ 2232680459 BATT_bootloaderRevision_11 0;
BA_ "GenSigType" SG_ 2232680459 BATT_bootloaderMinor_11 0;
BA_ "GenSigType" SG_ 2232680459 BATT_bootloaderMajor_11 0;
BA_ "GenSigType" SG_ 2232680459 BATT_appRevision_11 0;
BA_ "GenSigType" SG_ 2232680459 BATT_appMinor_11 0;
BA_ "GenSigType" SG_ 2232680459 BATT_appMajor_11 0;
BA_ "GenSigType" SG_ 2236874752 BATT_hardwareVersion_0 0;
BA_ "GenSigType" SG_ 2236874753 BATT_hardwareVersion_1 0;
BA_ "GenSigType" SG_ 2236874754 BATT_hardwareVersion_2 0;
BA_ "GenSigType" SG_ 2236874755 BATT_hardwareVersion_3 0;
BA_ "GenSigType" SG_ 2236874756 BATT_hardwareVersion_4 0;
BA_ "GenSigType" SG_ 2236874757 BATT_hardwareVersion_5 0;
BA_ "GenSigType" SG_ 2236874758 BATT_hardwareVersion_6 0;
BA_ "GenSigType" SG_ 2236874759 BATT_hardwareVersion_7 0;
BA_ "GenSigType" SG_ 2236874760 BATT_hardwareVersion_8 0;
BA_ "GenSigType" SG_ 2236874761 BATT_hardwareVersion_9 0;
BA_ "GenSigType" SG_ 2236874762 BATT_hardwareVersion_10 0;
BA_ "GenSigType" SG_ 2236874763 BATT_hardwareVersion_11 0;
BA_ "GenSigType" SG_ 2483290112 BATT_modStateRequested_0 0;
BA_ "GenSigType" SG_ 2483290112 BATT_prechargeState_0 0;
BA_ "GenSigType" SG_ 2483290112 BATT_fetPchgCommand_0 0;
BA_ "GenSigType" SG_ 2483290112 BATT_fetDsgCommand_0 0;
BA_ "GenSigType" SG_ 2483290112 BATT_fetChgCommand_0 0;
BA_ "GenSigType" SG_ 2483290112 BATT_fetDsgStatus_0 0;
BA_ "GenSigType" SG_ 2483290112 BATT_fetChgStatus_0 0;
BA_ "GenSigType" SG_ 2483290112 BATT_inhRegen_0 1;
BA_ "GenSigType" SG_ 2483290112 BATT_inhFullPower_0 1;
BA_ "GenSigType" SG_ 2483290112 BATT_inhDriveEntry_0 1;
BA_ "GenSigType" SG_ 2483290112 BATT_inhDrive_0 1;
BA_ "GenSigType" SG_ 2483290112 BATT_inhContPower_0 1;
BA_ "GenSigType" SG_ 2483290112 BATT_inhChargeEntry_0 1;
BA_ "GenSigType" SG_ 2483290112 BATT_inhCharge_0 1;
BA_ "GenSigType" SG_ 2483290112 BATT_modPackState_0 0;
BA_ "GenSigType" SG_ 2483290112 BATT_modChildState_0 0;
BA_ "GenSigType" SG_ 2483290112 BATT_modParentState_0 0;
BA_ "GenSigType" SG_ 2483290112 BATT_ArbitrationComplete_0 1;
BA_ "GenSigType" SG_ 2483290113 BATT_ArbitrationComplete_1 1;
BA_ "GenSigType" SG_ 2483290113 BATT_modStateRequested_1 0;
BA_ "GenSigType" SG_ 2483290113 BATT_prechargeState_1 0;
BA_ "GenSigType" SG_ 2483290113 BATT_fetPchgCommand_1 0;
BA_ "GenSigType" SG_ 2483290113 BATT_fetDsgCommand_1 0;
BA_ "GenSigType" SG_ 2483290113 BATT_fetChgCommand_1 0;
BA_ "GenSigType" SG_ 2483290113 BATT_fetDsgStatus_1 0;
BA_ "GenSigType" SG_ 2483290113 BATT_fetChgStatus_1 0;
BA_ "GenSigType" SG_ 2483290113 BATT_inhRegen_1 1;
BA_ "GenSigType" SG_ 2483290113 BATT_inhFullPower_1 1;
BA_ "GenSigType" SG_ 2483290113 BATT_inhDriveEntry_1 1;
BA_ "GenSigType" SG_ 2483290113 BATT_inhDrive_1 1;
BA_ "GenSigType" SG_ 2483290113 BATT_inhContPower_1 1;
BA_ "GenSigType" SG_ 2483290113 BATT_inhChargeEntry_1 1;
BA_ "GenSigType" SG_ 2483290113 BATT_inhCharge_1 1;
BA_ "GenSigType" SG_ 2483290113 BATT_modPackState_1 0;
BA_ "GenSigType" SG_ 2483290113 BATT_modChildState_1 0;
BA_ "GenSigType" SG_ 2483290113 BATT_modParentState_1 0;
BA_ "GenSigType" SG_ 2483290114 BATT_ArbitrationComplete_2 1;
BA_ "GenSigType" SG_ 2483290114 BATT_modStateRequested_2 0;
BA_ "GenSigType" SG_ 2483290114 BATT_prechargeState_2 0;
BA_ "GenSigType" SG_ 2483290114 BATT_fetPchgCommand_2 0;
BA_ "GenSigType" SG_ 2483290114 BATT_fetDsgCommand_2 0;
BA_ "GenSigType" SG_ 2483290114 BATT_fetChgCommand_2 0;
BA_ "GenSigType" SG_ 2483290114 BATT_fetDsgStatus_2 0;
BA_ "GenSigType" SG_ 2483290114 BATT_fetChgStatus_2 0;
BA_ "GenSigType" SG_ 2483290114 BATT_inhRegen_2 1;
BA_ "GenSigType" SG_ 2483290114 BATT_inhFullPower_2 1;
BA_ "GenSigType" SG_ 2483290114 BATT_inhDriveEntry_2 1;
BA_ "GenSigType" SG_ 2483290114 BATT_inhDrive_2 1;
BA_ "GenSigType" SG_ 2483290114 BATT_inhContPower_2 1;
BA_ "GenSigType" SG_ 2483290114 BATT_inhChargeEntry_2 1;
BA_ "GenSigType" SG_ 2483290114 BATT_inhCharge_2 1;
BA_ "GenSigType" SG_ 2483290114 BATT_modPackState_2 0;
BA_ "GenSigType" SG_ 2483290114 BATT_modChildState_2 0;
BA_ "GenSigType" SG_ 2483290114 BATT_modParentState_2 0;
BA_ "GenSigType" SG_ 2483290115 BATT_ArbitrationComplete_3 1;
BA_ "GenSigType" SG_ 2483290115 BATT_modStateRequested_3 0;
BA_ "GenSigType" SG_ 2483290115 BATT_prechargeState_3 0;
BA_ "GenSigType" SG_ 2483290115 BATT_fetPchgCommand_3 0;
BA_ "GenSigType" SG_ 2483290115 BATT_fetDsgCommand_3 0;
BA_ "GenSigType" SG_ 2483290115 BATT_fetChgCommand_3 0;
BA_ "GenSigType" SG_ 2483290115 BATT_fetDsgStatus_3 0;
BA_ "GenSigType" SG_ 2483290115 BATT_fetChgStatus_3 0;
BA_ "GenSigType" SG_ 2483290115 BATT_inhRegen_3 1;
BA_ "GenSigType" SG_ 2483290115 BATT_inhFullPower_3 1;
BA_ "GenSigType" SG_ 2483290115 BATT_inhDriveEntry_3 1;
BA_ "GenSigType" SG_ 2483290115 BATT_inhDrive_3 1;
BA_ "GenSigType" SG_ 2483290115 BATT_inhContPower_3 1;
BA_ "GenSigType" SG_ 2483290115 BATT_inhChargeEntry_3 1;
BA_ "GenSigType" SG_ 2483290115 BATT_inhCharge_3 1;
BA_ "GenSigType" SG_ 2483290115 BATT_modPackState_3 0;
BA_ "GenSigType" SG_ 2483290115 BATT_modChildState_3 0;
BA_ "GenSigType" SG_ 2483290115 BATT_modParentState_3 0;
BA_ "GenSigType" SG_ 2483290116 BATT_ArbitrationComplete_4 1;
BA_ "GenSigType" SG_ 2483290116 BATT_modStateRequested_4 0;
BA_ "GenSigType" SG_ 2483290116 BATT_prechargeState_4 0;
BA_ "GenSigType" SG_ 2483290116 BATT_fetPchgCommand_4 0;
BA_ "GenSigType" SG_ 2483290116 BATT_fetDsgCommand_4 0;
BA_ "GenSigType" SG_ 2483290116 BATT_fetChgCommand_4 0;
BA_ "GenSigType" SG_ 2483290116 BATT_fetDsgStatus_4 0;
BA_ "GenSigType" SG_ 2483290116 BATT_fetChgStatus_4 0;
BA_ "GenSigType" SG_ 2483290116 BATT_inhRegen_4 1;
BA_ "GenSigType" SG_ 2483290116 BATT_inhFullPower_4 1;
BA_ "GenSigType" SG_ 2483290116 BATT_inhDriveEntry_4 1;
BA_ "GenSigType" SG_ 2483290116 BATT_inhDrive_4 1;
BA_ "GenSigType" SG_ 2483290116 BATT_inhContPower_4 1;
BA_ "GenSigType" SG_ 2483290116 BATT_inhChargeEntry_4 1;
BA_ "GenSigType" SG_ 2483290116 BATT_inhCharge_4 1;
BA_ "GenSigType" SG_ 2483290116 BATT_modPackState_4 0;
BA_ "GenSigType" SG_ 2483290116 BATT_modChildState_4 0;
BA_ "GenSigType" SG_ 2483290116 BATT_modParentState_4 0;
BA_ "GenSigType" SG_ 2483290117 BATT_ArbitrationComplete_5 1;
BA_ "GenSigType" SG_ 2483290117 BATT_modStateRequested_5 0;
BA_ "GenSigType" SG_ 2483290117 BATT_prechargeState_5 0;
BA_ "GenSigType" SG_ 2483290117 BATT_fetPchgCommand_5 0;
BA_ "GenSigType" SG_ 2483290117 BATT_fetDsgCommand_5 0;
BA_ "GenSigType" SG_ 2483290117 BATT_fetChgCommand_5 0;
BA_ "GenSigType" SG_ 2483290117 BATT_fetDsgStatus_5 0;
BA_ "GenSigType" SG_ 2483290117 BATT_fetChgStatus_5 0;
BA_ "GenSigType" SG_ 2483290117 BATT_inhRegen_5 1;
BA_ "GenSigType" SG_ 2483290117 BATT_inhFullPower_5 1;
BA_ "GenSigType" SG_ 2483290117 BATT_inhDriveEntry_5 1;
BA_ "GenSigType" SG_ 2483290117 BATT_inhDrive_5 1;
BA_ "GenSigType" SG_ 2483290117 BATT_inhContPower_5 1;
BA_ "GenSigType" SG_ 2483290117 BATT_inhChargeEntry_5 1;
BA_ "GenSigType" SG_ 2483290117 BATT_inhCharge_5 1;
BA_ "GenSigType" SG_ 2483290117 BATT_modPackState_5 0;
BA_ "GenSigType" SG_ 2483290117 BATT_modChildState_5 0;
BA_ "GenSigType" SG_ 2483290117 BATT_modParentState_5 0;
BA_ "GenSigType" SG_ 2483290118 BATT_ArbitrationComplete_6 1;
BA_ "GenSigType" SG_ 2483290118 BATT_modStateRequested_6 0;
BA_ "GenSigType" SG_ 2483290118 BATT_prechargeState_6 0;
BA_ "GenSigType" SG_ 2483290118 BATT_fetPchgCommand_6 0;
BA_ "GenSigType" SG_ 2483290118 BATT_fetDsgCommand_6 0;
BA_ "GenSigType" SG_ 2483290118 BATT_fetChgCommand_6 0;
BA_ "GenSigType" SG_ 2483290118 BATT_fetDsgStatus_6 0;
BA_ "GenSigType" SG_ 2483290118 BATT_fetChgStatus_6 0;
BA_ "GenSigType" SG_ 2483290118 BATT_inhRegen_6 1;
BA_ "GenSigType" SG_ 2483290118 BATT_inhFullPower_6 1;
BA_ "GenSigType" SG_ 2483290118 BATT_inhDriveEntry_6 1;
BA_ "GenSigType" SG_ 2483290118 BATT_inhDrive_6 1;
BA_ "GenSigType" SG_ 2483290118 BATT_inhContPower_6 1;
BA_ "GenSigType" SG_ 2483290118 BATT_inhChargeEntry_6 1;
BA_ "GenSigType" SG_ 2483290118 BATT_inhCharge_6 1;
BA_ "GenSigType" SG_ 2483290118 BATT_modPackState_6 0;
BA_ "GenSigType" SG_ 2483290118 BATT_modChildState_6 0;
BA_ "GenSigType" SG_ 2483290118 BATT_modParentState_6 0;
BA_ "GenSigType" SG_ 2483290119 BATT_ArbitrationComplete_7 1;
BA_ "GenSigType" SG_ 2483290119 BATT_modStateRequested_7 0;
BA_ "GenSigType" SG_ 2483290119 BATT_prechargeState_7 0;
BA_ "GenSigType" SG_ 2483290119 BATT_fetPchgCommand_7 0;
BA_ "GenSigType" SG_ 2483290119 BATT_fetDsgCommand_7 0;
BA_ "GenSigType" SG_ 2483290119 BATT_fetChgCommand_7 0;
BA_ "GenSigType" SG_ 2483290119 BATT_fetDsgStatus_7 0;
BA_ "GenSigType" SG_ 2483290119 BATT_fetChgStatus_7 0;
BA_ "GenSigType" SG_ 2483290119 BATT_inhRegen_7 1;
BA_ "GenSigType" SG_ 2483290119 BATT_inhFullPower_7 1;
BA_ "GenSigType" SG_ 2483290119 BATT_inhDriveEntry_7 1;
BA_ "GenSigType" SG_ 2483290119 BATT_inhDrive_7 1;
BA_ "GenSigType" SG_ 2483290119 BATT_inhContPower_7 1;
BA_ "GenSigType" SG_ 2483290119 BATT_inhChargeEntry_7 1;
BA_ "GenSigType" SG_ 2483290119 BATT_inhCharge_7 1;
BA_ "GenSigType" SG_ 2483290119 BATT_modPackState_7 0;
BA_ "GenSigType" SG_ 2483290119 BATT_modChildState_7 0;
BA_ "GenSigType" SG_ 2483290119 BATT_modParentState_7 0;
BA_ "GenSigType" SG_ 2483290120 BATT_ArbitrationComplete_8 1;
BA_ "GenSigType" SG_ 2483290120 BATT_modStateRequested_8 0;
BA_ "GenSigType" SG_ 2483290120 BATT_prechargeState_8 0;
BA_ "GenSigType" SG_ 2483290120 BATT_fetPchgCommand_8 0;
BA_ "GenSigType" SG_ 2483290120 BATT_fetDsgCommand_8 0;
BA_ "GenSigType" SG_ 2483290120 BATT_fetChgCommand_8 0;
BA_ "GenSigType" SG_ 2483290120 BATT_fetDsgStatus_8 0;
BA_ "GenSigType" SG_ 2483290120 BATT_fetChgStatus_8 0;
BA_ "GenSigType" SG_ 2483290120 BATT_inhRegen_8 1;
BA_ "GenSigType" SG_ 2483290120 BATT_inhFullPower_8 1;
BA_ "GenSigType" SG_ 2483290120 BATT_inhDriveEntry_8 1;
BA_ "GenSigType" SG_ 2483290120 BATT_inhDrive_8 1;
BA_ "GenSigType" SG_ 2483290120 BATT_inhContPower_8 1;
BA_ "GenSigType" SG_ 2483290120 BATT_inhChargeEntry_8 1;
BA_ "GenSigType" SG_ 2483290120 BATT_inhCharge_8 1;
BA_ "GenSigType" SG_ 2483290120 BATT_modPackState_8 0;
BA_ "GenSigType" SG_ 2483290120 BATT_modChildState_8 0;
BA_ "GenSigType" SG_ 2483290120 BATT_modParentState_8 0;
BA_ "GenSigType" SG_ 2483290121 BATT_ArbitrationComplete_9 1;
BA_ "GenSigType" SG_ 2483290121 BATT_modStateRequested_9 0;
BA_ "GenSigType" SG_ 2483290121 BATT_prechargeState_9 0;
BA_ "GenSigType" SG_ 2483290121 BATT_fetPchgCommand_9 0;
BA_ "GenSigType" SG_ 2483290121 BATT_fetDsgCommand_9 0;
BA_ "GenSigType" SG_ 2483290121 BATT_fetChgCommand_9 0;
BA_ "GenSigType" SG_ 2483290121 BATT_fetDsgStatus_9 0;
BA_ "GenSigType" SG_ 2483290121 BATT_fetChgStatus_9 0;
BA_ "GenSigType" SG_ 2483290121 BATT_inhRegen_9 1;
BA_ "GenSigType" SG_ 2483290121 BATT_inhFullPower_9 1;
BA_ "GenSigType" SG_ 2483290121 BATT_inhDriveEntry_9 1;
BA_ "GenSigType" SG_ 2483290121 BATT_inhDrive_9 1;
BA_ "GenSigType" SG_ 2483290121 BATT_inhContPower_9 1;
BA_ "GenSigType" SG_ 2483290121 BATT_inhChargeEntry_9 1;
BA_ "GenSigType" SG_ 2483290121 BATT_inhCharge_9 1;
BA_ "GenSigType" SG_ 2483290121 BATT_modPackState_9 0;
BA_ "GenSigType" SG_ 2483290121 BATT_modChildState_9 0;
BA_ "GenSigType" SG_ 2483290121 BATT_modParentState_9 0;
BA_ "GenSigType" SG_ 2483290122 BATT_ArbitrationComplete_10 1;
BA_ "GenSigType" SG_ 2483290122 BATT_modStateRequested_10 0;
BA_ "GenSigType" SG_ 2483290122 BATT_prechargeState_10 0;
BA_ "GenSigType" SG_ 2483290122 BATT_fetPchgCommand_10 0;
BA_ "GenSigType" SG_ 2483290122 BATT_fetDsgCommand_10 0;
BA_ "GenSigType" SG_ 2483290122 BATT_fetChgCommand_10 0;
BA_ "GenSigType" SG_ 2483290122 BATT_fetDsgStatus_10 0;
BA_ "GenSigType" SG_ 2483290122 BATT_fetChgStatus_10 0;
BA_ "GenSigType" SG_ 2483290122 BATT_inhRegen_10 1;
BA_ "GenSigType" SG_ 2483290122 BATT_inhFullPower_10 1;
BA_ "GenSigType" SG_ 2483290122 BATT_inhDriveEntry_10 1;
BA_ "GenSigType" SG_ 2483290122 BATT_inhDrive_10 1;
BA_ "GenSigType" SG_ 2483290122 BATT_inhContPower_10 1;
BA_ "GenSigType" SG_ 2483290122 BATT_inhChargeEntry_10 1;
BA_ "GenSigType" SG_ 2483290122 BATT_inhCharge_10 1;
BA_ "GenSigType" SG_ 2483290122 BATT_modPackState_10 0;
BA_ "GenSigType" SG_ 2483290122 BATT_modChildState_10 0;
BA_ "GenSigType" SG_ 2483290122 BATT_modParentState_10 0;
BA_ "GenSigType" SG_ 2483290123 BATT_ArbitrationComplete_11 1;
BA_ "GenSigType" SG_ 2483290123 BATT_modStateRequested_11 0;
BA_ "GenSigType" SG_ 2483290123 BATT_prechargeState_11 0;
BA_ "GenSigType" SG_ 2483290123 BATT_fetPchgCommand_11 0;
BA_ "GenSigType" SG_ 2483290123 BATT_fetDsgCommand_11 0;
BA_ "GenSigType" SG_ 2483290123 BATT_fetChgCommand_11 0;
BA_ "GenSigType" SG_ 2483290123 BATT_fetDsgStatus_11 0;
BA_ "GenSigType" SG_ 2483290123 BATT_fetChgStatus_11 0;
BA_ "GenSigType" SG_ 2483290123 BATT_inhRegen_11 1;
BA_ "GenSigType" SG_ 2483290123 BATT_inhFullPower_11 1;
BA_ "GenSigType" SG_ 2483290123 BATT_inhDriveEntry_11 1;
BA_ "GenSigType" SG_ 2483290123 BATT_inhDrive_11 1;
BA_ "GenSigType" SG_ 2483290123 BATT_inhContPower_11 1;
BA_ "GenSigType" SG_ 2483290123 BATT_inhChargeEntry_11 1;
BA_ "GenSigType" SG_ 2483290123 BATT_inhCharge_11 1;
BA_ "GenSigType" SG_ 2483290123 BATT_modPackState_11 0;
BA_ "GenSigType" SG_ 2483290123 BATT_modChildState_11 0;
BA_ "GenSigType" SG_ 2483290123 BATT_modParentState_11 0;
BA_ "GenSigType" SG_ 2508193792 BATT_appRevision_bootup_0 0;
BA_ "GenSigType" SG_ 2508193792 BATT_appMajor_bootup_0 0;
BA_ "GenSigType" SG_ 2508193792 BATT_bootloaderRevision_bootup_0 0;
BA_ "GenSigType" SG_ 2508193792 BATT_bootloaderMinor_bootup_0 0;
BA_ "GenSigType" SG_ 2508193792 BATT_bootloaderMajor_bootup_0 0;
BA_ "GenSigType" SG_ 2508193792 BATT_appMinor_bootup_0 0;
BA_ "GenSigType" SG_ 2508193793 BATT_appMinor_bootup_1 0;
BA_ "GenSigType" SG_ 2508193793 BATT_appRevision_bootup_1 0;
BA_ "GenSigType" SG_ 2508193793 BATT_appMajor_bootup_1 0;
BA_ "GenSigType" SG_ 2508193793 BATT_bootloaderMajor_bootup_1 0;
BA_ "GenSigType" SG_ 2508193793 BATT_bootloaderMinor_bootup_1 0;
BA_ "GenSigType" SG_ 2508193793 BATT_bootloaderRevision_bootup_1 0;
BA_ "GenSigType" SG_ 2508193794 BATT_bootloaderMajor_bootup_2 0;
BA_ "GenSigType" SG_ 2508193794 BATT_bootloaderMinor_bootup_2 0;
BA_ "GenSigType" SG_ 2508193794 BATT_bootloaderRevision_bootup_2 0;
BA_ "GenSigType" SG_ 2508193794 BATT_appMinor_bootup_2 0;
BA_ "GenSigType" SG_ 2508193794 BATT_appMajor_bootup_2 0;
BA_ "GenSigType" SG_ 2508193794 BATT_appRevision_bootup_2 0;
BA_ "GenSigType" SG_ 2508193795 BATT_appMajor_bootup_3 0;
BA_ "GenSigType" SG_ 2508193795 BATT_appMinor_bootup_3 0;
BA_ "GenSigType" SG_ 2508193795 BATT_bootloaderMinor_bootup_3 0;
BA_ "GenSigType" SG_ 2508193795 BATT_bootloaderRevision_bootup_3 0;
BA_ "GenSigType" SG_ 2508193795 BATT_bootloaderMajor_bootup_3 0;
BA_ "GenSigType" SG_ 2508193795 BATT_appRevision_bootup_3 0;
BA_ "GenSigType" SG_ 2508193796 BATT_bootloaderRevision_bootup_4 0;
BA_ "GenSigType" SG_ 2508193796 BATT_appMajor_bootup_4 0;
BA_ "GenSigType" SG_ 2508193796 BATT_appRevision_bootup_4 0;
BA_ "GenSigType" SG_ 2508193796 BATT_appMinor_bootup_4 0;
BA_ "GenSigType" SG_ 2508193796 BATT_bootloaderMinor_bootup_4 0;
BA_ "GenSigType" SG_ 2508193796 BATT_bootloaderMajor_bootup_4 0;
BA_ "GenSigType" SG_ 2508193797 BATT_appMinor_bootup_5 0;
BA_ "GenSigType" SG_ 2508193797 BATT_appRevision_bootup_5 0;
BA_ "GenSigType" SG_ 2508193797 BATT_appMajor_bootup_5 0;
BA_ "GenSigType" SG_ 2508193797 BATT_bootloaderMajor_bootup_5 0;
BA_ "GenSigType" SG_ 2508193797 BATT_bootloaderMinor_bootup_5 0;
BA_ "GenSigType" SG_ 2508193797 BATT_bootloaderRevision_bootup_5 0;
BA_ "GenSigType" SG_ 2508193798 BATT_bootloaderRevision_bootup_6 0;
BA_ "GenSigType" SG_ 2508193798 BATT_appMajor_bootup_6 0;
BA_ "GenSigType" SG_ 2508193798 BATT_appMinor_bootup_6 0;
BA_ "GenSigType" SG_ 2508193798 BATT_bootloaderMajor_bootup_6 0;
BA_ "GenSigType" SG_ 2508193798 BATT_appRevision_bootup_6 0;
BA_ "GenSigType" SG_ 2508193798 BATT_bootloaderMinor_bootup_6 0;
BA_ "GenSigType" SG_ 2508193799 BATT_appMajor_bootup_7 0;
BA_ "GenSigType" SG_ 2508193799 BATT_appMinor_bootup_7 0;
BA_ "GenSigType" SG_ 2508193799 BATT_bootloaderMajor_bootup_7 0;
BA_ "GenSigType" SG_ 2508193799 BATT_bootloaderMinor_bootup_7 0;
BA_ "GenSigType" SG_ 2508193799 BATT_appRevision_bootup_7 0;
BA_ "GenSigType" SG_ 2508193799 BATT_bootloaderRevision_bootup_7 0;
BA_ "GenSigType" SG_ 2508193800 BATT_bootloaderRevision_bootup_8 0;
BA_ "GenSigType" SG_ 2508193800 BATT_bootloaderMinor_bootup_8 0;
BA_ "GenSigType" SG_ 2508193800 BATT_bootloaderMajor_bootup_8 0;
BA_ "GenSigType" SG_ 2508193800 BATT_appRevision_bootup_8 0;
BA_ "GenSigType" SG_ 2508193800 BATT_appMinor_bootup_8 0;
BA_ "GenSigType" SG_ 2508193800 BATT_appMajor_bootup_8 0;
BA_ "GenSigType" SG_ 2508193801 BATT_bootloaderRevision_bootup_9 0;
BA_ "GenSigType" SG_ 2508193801 BATT_bootloaderMinor_bootup_9 0;
BA_ "GenSigType" SG_ 2508193801 BATT_bootloaderMajor_bootup_9 0;
BA_ "GenSigType" SG_ 2508193801 BATT_appRevision_bootup_9 0;
BA_ "GenSigType" SG_ 2508193801 BATT_appMinor_bootup_9 0;
BA_ "GenSigType" SG_ 2508193801 BATT_appMajor_bootup_9 0;
BA_ "GenSigType" SG_ 2508193802 BATT_bootloaderRevision_bootup_10 0;
BA_ "GenSigType" SG_ 2508193802 BATT_bootloaderMinor_bootup_10 0;
BA_ "GenSigType" SG_ 2508193802 BATT_bootloaderMajor_bootup_10 0;
BA_ "GenSigType" SG_ 2508193802 BATT_appRevision_bootup_10 0;
BA_ "GenSigType" SG_ 2508193802 BATT_appMinor_bootup_10 0;
BA_ "GenSigType" SG_ 2508193802 BATT_appMajor_bootup_10 0;
BA_ "GenSigType" SG_ 2508193803 BATT_bootloaderMinor_bootup_11 0;
BA_ "GenSigType" SG_ 2508193803 BATT_bootloaderMajor_bootup_11 0;
BA_ "GenSigType" SG_ 2508193803 BATT_appRevision_bootup_11 0;
BA_ "GenSigType" SG_ 2508193803 BATT_appMinor_bootup_11 0;
BA_ "GenSigType" SG_ 2508193803 BATT_appMajor_bootup_11 0;
BA_ "GenSigType" SG_ 2508193803 BATT_bootloaderRevision_bootup_11 0;
BA_ "GenSigType" SG_ 2550661120 BATT_IGNLO_Status_0 1;
BA_ "GenSigType" SG_ 2550661121 BATT_IGNLO_Status_1 1;
BA_ "GenSigType" SG_ 2550661122 BATT_IGNLO_Status_2 1;
BA_ "GenSigType" SG_ 2550661123 BATT_IGNLO_Status_3 1;
BA_ "GenSigType" SG_ 2550661124 BATT_IGNLO_Status_4 1;
BA_ "GenSigType" SG_ 2550661125 BATT_IGNLO_Status_5 1;
BA_ "GenSigType" SG_ 2550661126 BATT_IGNLO_Status_6 1;
BA_ "GenSigType" SG_ 2550661127 BATT_IGNLO_Status_7 1;
BA_ "GenSigType" SG_ 2550661128 BATT_IGNLO_Status_8 1;
BA_ "GenSigType" SG_ 2550661129 BATT_IGNLO_Status_9 1;
BA_ "GenSigType" SG_ 2550661130 BATT_IGNLO_Status_10 1;
BA_ "GenSigType" SG_ 2550661131 BATT_IGNLO_Status_11 1;
BA_ "GenSigSNA" SG_ 2224291846 BATT_tModuleMax_6 2047;
BA_ "GenSigSNA" SG_ 2224291846 BATT_tModuleMin_6 2047;
BA_ "GenSigSNA" SG_ 2224291846 BATT_vBrickMinID_6 15;
BA_ "GenSigSNA" SG_ 2224291846 BATT_vBrickMaxID_6 15;
BA_ "GenSigSNA" SG_ 2224291846 BATT_tModuleMaxID_6 15;
BA_ "GenSigSNA" SG_ 2224291846 BATT_tModuleMinID_6 15;
BA_ "GenSigSNA" SG_ 2224291846 BATT_vBrickMin_6 4095;
BA_ "GenSigSNA" SG_ 2224291846 BATT_vBrickMax_6 4095;
BA_ "GenSigSNA" SG_ 2224291847 BATT_tModuleMinID_7 15;
BA_ "GenSigSNA" SG_ 2224291847 BATT_vBrickMaxID_7 15;
BA_ "GenSigSNA" SG_ 2224291847 BATT_tModuleMax_7 2047;
BA_ "GenSigSNA" SG_ 2224291847 BATT_vBrickMinID_7 15;
BA_ "GenSigSNA" SG_ 2224291847 BATT_tModuleMin_7 2047;
BA_ "GenSigSNA" SG_ 2224291847 BATT_tModuleMaxID_7 15;
BA_ "GenSigSNA" SG_ 2224291847 BATT_vBrickMax_7 4095;
BA_ "GenSigSNA" SG_ 2224291847 BATT_vBrickMin_7 4095;
BA_ "GenSigSNA" SG_ 2224291848 BATT_tModuleMax_8 2047;
BA_ "GenSigSNA" SG_ 2224291848 BATT_tModuleMin_8 2047;
BA_ "GenSigSNA" SG_ 2224291848 BATT_tModuleMinID_8 15;
BA_ "GenSigSNA" SG_ 2224291848 BATT_tModuleMaxID_8 15;
BA_ "GenSigSNA" SG_ 2224291848 BATT_vBrickMax_8 4095;
BA_ "GenSigSNA" SG_ 2224291848 BATT_vBrickMin_8 4095;
BA_ "GenSigSNA" SG_ 2224291848 BATT_vBrickMaxID_8 15;
BA_ "GenSigSNA" SG_ 2224291848 BATT_vBrickMinID_8 15;
BA_ "GenSigSNA" SG_ 2224291849 BATT_vBrickMax_9 4095;
BA_ "GenSigSNA" SG_ 2224291849 BATT_vBrickMin_9 4095;
BA_ "GenSigSNA" SG_ 2224291849 BATT_tModuleMaxID_9 15;
BA_ "GenSigSNA" SG_ 2224291849 BATT_tModuleMinID_9 15;
BA_ "GenSigSNA" SG_ 2224291849 BATT_vBrickMinID_9 15;
BA_ "GenSigSNA" SG_ 2224291849 BATT_vBrickMaxID_9 15;
BA_ "GenSigSNA" SG_ 2224291849 BATT_tModuleMin_9 2047;
BA_ "GenSigSNA" SG_ 2224291849 BATT_tModuleMax_9 2047;
BA_ "GenSigSNA" SG_ 2224291850 BATT_vBrickMax_10 4095;
BA_ "GenSigSNA" SG_ 2224291850 BATT_tModuleMin_10 2047;
BA_ "GenSigSNA" SG_ 2224291850 BATT_tModuleMax_10 2047;
BA_ "GenSigSNA" SG_ 2224291850 BATT_vBrickMin_10 4095;
BA_ "GenSigSNA" SG_ 2224291850 BATT_tModuleMaxID_10 15;
BA_ "GenSigSNA" SG_ 2224291850 BATT_tModuleMinID_10 15;
BA_ "GenSigSNA" SG_ 2224291850 BATT_vBrickMaxID_10 15;
BA_ "GenSigSNA" SG_ 2224291850 BATT_vBrickMinID_10 15;
BA_ "GenSigSNA" SG_ 2224291851 BATT_vBrickMin_11 4095;
BA_ "GenSigSNA" SG_ 2224291851 BATT_vBrickMax_11 4095;
BA_ "GenSigSNA" SG_ 2224291851 BATT_vBrickMinID_11 15;
BA_ "GenSigSNA" SG_ 2224291851 BATT_tModuleMin_11 2047;
BA_ "GenSigSNA" SG_ 2224291851 BATT_vBrickMaxID_11 15;
BA_ "GenSigSNA" SG_ 2224291851 BATT_tModuleMax_11 2047;
BA_ "GenSigSNA" SG_ 2224291851 BATT_tModuleMaxID_11 15;
BA_ "GenSigSNA" SG_ 2224291851 BATT_tModuleMinID_11 15;
BA_ "Access" SG_ 2550398976 BATT_manufacturerAccess_0 1;
BA_ "Access" SG_ 2550398977 BATT_manufacturerAccess_1 1;
BA_ "Access" SG_ 2550398978 BATT_manufacturerAccess_2 1;
BA_ "Access" SG_ 2550398979 BATT_manufacturerAccess_3 1;
BA_ "Access" SG_ 2550398980 BATT_manufacturerAccess_4 1;
BA_ "Access" SG_ 2550398981 BATT_manufacturerAccess_5 1;
BA_ "Access" SG_ 2550398982 BATT_manufacturerAccess_6 1;
BA_ "Access" SG_ 2550398983 BATT_manufacturerAccess_7 1;
BA_ "Access" SG_ 2550398984 BATT_manufacturerAccess_8 1;
BA_ "Access" SG_ 2550398985 BATT_manufacturerAccess_9 1;
BA_ "Access" SG_ 2550398986 BATT_manufacturerAccess_10 1;
BA_ "Access" SG_ 2550398987 BATT_manufacturerAccess_11 1;
BA_ "Access" SG_ 2550661120 BATT_serialNumber_0 1;
BA_ "Access" SG_ 2550661121 BATT_serialNumber_1 1;
BA_ "Access" SG_ 2550661122 BATT_serialNumber_2 1;
BA_ "Access" SG_ 2550661123 BATT_serialNumber_3 1;
BA_ "Access" SG_ 2550661124 BATT_serialNumber_4 1;
BA_ "Access" SG_ 2550661125 BATT_serialNumber_5 1;
BA_ "Access" SG_ 2550661126 BATT_serialNumber_6 1;
BA_ "Access" SG_ 2550661127 BATT_serialNumber_7 1;
BA_ "Access" SG_ 2550661128 BATT_serialNumber_8 1;
BA_ "Access" SG_ 2550661129 BATT_serialNumber_9 1;
BA_ "Access" SG_ 2550661130 BATT_serialNumber_10 1;
BA_ "Access" SG_ 2550661131 BATT_serialNumber_11 1;
VAL_ 2224291846 BATT_tModuleMax_6  2047 "SNA"  ;
VAL_ 2224291846 BATT_tModuleMin_6  2047 "SNA"  ;
VAL_ 2224291846 BATT_vBrickMinID_6  15 "SNA"  ;
VAL_ 2224291846 BATT_vBrickMaxID_6  15 "SNA"  ;
VAL_ 2224291846 BATT_tModuleMaxID_6  15 "SNA"  ;
VAL_ 2224291846 BATT_tModuleMinID_6  15 "SNA"  ;
VAL_ 2224291846 BATT_vBrickMin_6  4095 "SNA"  ;
VAL_ 2224291846 BATT_vBrickMax_6  4095 "SNA"  ;
VAL_ 2224291847 BATT_tModuleMinID_7  15 "SNA"  ;
VAL_ 2224291847 BATT_vBrickMaxID_7  15 "SNA"  ;
VAL_ 2224291847 BATT_tModuleMax_7  2047 "SNA"  ;
VAL_ 2224291847 BATT_vBrickMinID_7  15 "SNA"  ;
VAL_ 2224291847 BATT_tModuleMin_7  2047 "SNA"  ;
VAL_ 2224291847 BATT_tModuleMaxID_7  15 "SNA"  ;
VAL_ 2224291847 BATT_vBrickMax_7  4095 "SNA"  ;
VAL_ 2224291847 BATT_vBrickMin_7  4095 "SNA"  ;
VAL_ 2224291848 BATT_tModuleMax_8  2047 "SNA"  ;
VAL_ 2224291848 BATT_tModuleMin_8  2047 "SNA"  ;
VAL_ 2224291848 BATT_tModuleMinID_8  15 "SNA"  ;
VAL_ 2224291848 BATT_tModuleMaxID_8  15 "SNA"  ;
VAL_ 2224291848 BATT_vBrickMax_8  4095 "SNA"  ;
VAL_ 2224291848 BATT_vBrickMin_8  4095 "SNA"  ;
VAL_ 2224291848 BATT_vBrickMaxID_8  15 "SNA"  ;
VAL_ 2224291848 BATT_vBrickMinID_8  15 "SNA"  ;
VAL_ 2224291849 BATT_vBrickMax_9  4095 "SNA"  ;
VAL_ 2224291849 BATT_vBrickMin_9  4095 "SNA"  ;
VAL_ 2224291849 BATT_tModuleMaxID_9  15 "SNA"  ;
VAL_ 2224291849 BATT_tModuleMinID_9  15 "SNA"  ;
VAL_ 2224291849 BATT_vBrickMinID_9  15 "SNA"  ;
VAL_ 2224291849 BATT_vBrickMaxID_9  15 "SNA"  ;
VAL_ 2224291849 BATT_tModuleMin_9  2047 "SNA"  ;
VAL_ 2224291849 BATT_tModuleMax_9  2047 "SNA"  ;
VAL_ 2224291850 BATT_vBrickMax_10  4095 "SNA"  ;
VAL_ 2224291850 BATT_tModuleMin_10  2047 "SNA"  ;
VAL_ 2224291850 BATT_tModuleMax_10  2047 "SNA"  ;
VAL_ 2224291850 BATT_vBrickMin_10  4095 "SNA"  ;
VAL_ 2224291850 BATT_tModuleMaxID_10  15 "SNA"  ;
VAL_ 2224291850 BATT_tModuleMinID_10  15 "SNA"  ;
VAL_ 2224291850 BATT_vBrickMaxID_10  15 "SNA"  ;
VAL_ 2224291850 BATT_vBrickMinID_10  15 "SNA"  ;
VAL_ 2224291851 BATT_vBrickMin_11  4095 "SNA"  ;
VAL_ 2224291851 BATT_vBrickMax_11  4095 "SNA"  ;
VAL_ 2224291851 BATT_vBrickMinID_11  15 "SNA"  ;
VAL_ 2224291851 BATT_tModuleMin_11  2047 "SNA"  ;
VAL_ 2224291851 BATT_vBrickMaxID_11  15 "SNA"  ;
VAL_ 2224291851 BATT_tModuleMax_11  2047 "SNA"  ;
VAL_ 2224291851 BATT_tModuleMaxID_11  15 "SNA"  ;
VAL_ 2224291851 BATT_tModuleMinID_11  15 "SNA"  ;
VAL_ 2483290112 BATT_modStateRequested_0  4 "Connect"  3 "Disconnect"  2 "Charge"  1 "Drive"  0 "Standby"  ;
VAL_ 2483290112 BATT_prechargeState_0  6 "Fault"  5 "Complete"  4 "Idle"  3 "P0F1"  2 "P1F1"  1 "P1F0"  0 "P0F0"  ;
VAL_ 2483290112 BATT_fetPchgCommand_0  1 "Close"  0 "Open"  ;
VAL_ 2483290112 BATT_fetDsgCommand_0  1 "Close"  0 "Open"  ;
VAL_ 2483290112 BATT_fetChgCommand_0  1 "Close"  0 "Open"  ;
VAL_ 2483290112 BATT_fetDsgStatus_0  8 "Welded"  7 "OpenPending"  6 "FailToClose"  5 "FailToOpen"  4 "Closing"  3 "Opening"  2 "Closed"  1 "Open"  0 "Unknown"  ;
VAL_ 2483290112 BATT_fetChgStatus_0  8 "Welded"  7 "OpenPending"  6 "FailToClose"  5 "FailToOpen"  4 "Closing"  3 "Opening"  2 "Closed"  1 "Open"  0 "Unknown"  ;
VAL_ 2483290112 BATT_modPackState_0  10 "Disconnect"  9 "ConnectCharge"  8 "ConnectDrive"  7 "SelectCharge"  6 "SelectDrive"  5 "ChargeStandbyConnect"  4 "Reserved"  3 "Charge"  2 "Drive"  1 "StandbyReady"  0 "StandbyNotReady"  ;
VAL_ 2483290112 BATT_modChildState_0  12 "connectbusjoin"  11 "connectbusprecharge"  10 "softdisconnectbus"  9 "disconnectbus"  8 "chargenormal"  7 "drivenormal"  6 "driverampdown"  5 "drivelimp"  4 "standbyready"  3 "standbyfault"  2 "standbynotready"  1 "standbysleeping"  0 "standbysleep"  ;
VAL_ 2483290112 BATT_modParentState_0  4 "Connect"  3 "Disconnect"  2 "Charge"  1 "Drive"  0 "Standby"  ;
VAL_ 2483290112 BATT_modDataValid_0  1 "Valid"  0 "Not Valid"  ;
VAL_ 2483290113 BATT_modStateRequested_1  4 "Connect"  3 "Disconnect"  2 "Charge"  1 "Drive"  0 "Standby"  ;
VAL_ 2483290113 BATT_modDataValid_1  1 "Valid"  0 "Not Valid"  ;
VAL_ 2483290113 BATT_prechargeState_1  6 "Fault"  5 "Complete"  4 "Idle"  3 "P0F1"  2 "P1F1"  1 "P1F0"  0 "P0F0"  ;
VAL_ 2483290113 BATT_fetPchgCommand_1  1 "Close"  0 "Open"  ;
VAL_ 2483290113 BATT_fetDsgCommand_1  1 "Close"  0 "Open"  ;
VAL_ 2483290113 BATT_fetChgCommand_1  1 "Close"  0 "Open"  ;
VAL_ 2483290113 BATT_fetDsgStatus_1  8 "Welded"  7 "OpenPending"  6 "FailToClose"  5 "FailToOpen"  4 "Closing"  3 "Opening"  2 "Closed"  1 "Open"  0 "Unknown"  ;
VAL_ 2483290113 BATT_fetChgStatus_1  8 "Welded"  7 "OpenPending"  6 "FailToClose"  5 "FailToOpen"  4 "Closing"  3 "Opening"  2 "Closed"  1 "Open"  0 "Unknown"  ;
VAL_ 2483290113 BATT_modPackState_1  10 "Disconnect"  9 "ConnectCharge"  8 "ConnectDrive"  7 "SelectCharge"  6 "SelectDrive"  5 "ChargeStandbyConnect"  4 "Reserved"  3 "Charge"  2 "Drive"  1 "StandbyReady"  0 "StandbyNotReady"  ;
VAL_ 2483290113 BATT_modChildState_1  12 "connectbusjoin"  11 "connectbusprecharge"  10 "softdisconnectbus"  9 "disconnectbus"  8 "chargenormal"  7 "drivenormal"  6 "driverampdown"  5 "drivelimp"  4 "standbyready"  3 "standbyfault"  2 "standbynotready"  1 "standbysleeping"  0 "standbysleep"  ;
VAL_ 2483290113 BATT_modParentState_1  4 "Connect"  3 "Disconnect"  2 "Charge"  1 "Drive"  0 "Standby"  ;
VAL_ 2483290114 BATT_modStateRequested_2  4 "Connect"  3 "Disconnect"  2 "Charge"  1 "Drive"  0 "Standby"  ;
VAL_ 2483290114 BATT_modDataValid_2  1 "Valid"  0 "Not Valid"  ;
VAL_ 2483290114 BATT_prechargeState_2  6 "Fault"  5 "Complete"  4 "Idle"  3 "P0F1"  2 "P1F1"  1 "P1F0"  0 "P0F0"  ;
VAL_ 2483290114 BATT_fetPchgCommand_2  1 "Close"  0 "Open"  ;
VAL_ 2483290114 BATT_fetDsgCommand_2  1 "Close"  0 "Open"  ;
VAL_ 2483290114 BATT_fetChgCommand_2  1 "Close"  0 "Open"  ;
VAL_ 2483290114 BATT_fetDsgStatus_2  8 "Welded"  7 "OpenPending"  6 "FailToClose"  5 "FailToOpen"  4 "Closing"  3 "Opening"  2 "Closed"  1 "Open"  0 "Unknown"  ;
VAL_ 2483290114 BATT_fetChgStatus_2  8 "Welded"  7 "OpenPending"  6 "FailToClose"  5 "FailToOpen"  4 "Closing"  3 "Opening"  2 "Closed"  1 "Open"  0 "Unknown"  ;
VAL_ 2483290114 BATT_modPackState_2  10 "Disconnect"  9 "ConnectCharge"  8 "ConnectDrive"  7 "SelectCharge"  6 "SelectDrive"  5 "ChargeStandbyConnect"  4 "Reserved"  3 "Charge"  2 "Drive"  1 "StandbyReady"  0 "StandbyNotReady"  ;
VAL_ 2483290114 BATT_modChildState_2  12 "connectbusjoin"  11 "connectbusprecharge"  10 "softdisconnectbus"  9 "disconnectbus"  8 "chargenormal"  7 "drivenormal"  6 "driverampdown"  5 "drivelimp"  4 "standbyready"  3 "standbyfault"  2 "standbynotready"  1 "standbysleeping"  0 "standbysleep"  ;
VAL_ 2483290114 BATT_modParentState_2  4 "Connect"  3 "Disconnect"  2 "Charge"  1 "Drive"  0 "Standby"  ;
VAL_ 2483290115 BATT_modStateRequested_3  4 "Connect"  3 "Disconnect"  2 "Charge"  1 "Drive"  0 "Standby"  ;
VAL_ 2483290115 BATT_modDataValid_3  1 "Valid"  0 "Not Valid"  ;
VAL_ 2483290115 BATT_prechargeState_3  6 "Fault"  5 "Complete"  4 "Idle"  3 "P0F1"  2 "P1F1"  1 "P1F0"  0 "P0F0"  ;
VAL_ 2483290115 BATT_fetPchgCommand_3  1 "Close"  0 "Open"  ;
VAL_ 2483290115 BATT_fetDsgCommand_3  1 "Close"  0 "Open"  ;
VAL_ 2483290115 BATT_fetChgCommand_3  1 "Close"  0 "Open"  ;
VAL_ 2483290115 BATT_fetDsgStatus_3  8 "Welded"  7 "OpenPending"  6 "FailToClose"  5 "FailToOpen"  4 "Closing"  3 "Opening"  2 "Closed"  1 "Open"  0 "Unknown"  ;
VAL_ 2483290115 BATT_fetChgStatus_3  8 "Welded"  7 "OpenPending"  6 "FailToClose"  5 "FailToOpen"  4 "Closing"  3 "Opening"  2 "Closed"  1 "Open"  0 "Unknown"  ;
VAL_ 2483290115 BATT_modPackState_3  10 "Disconnect"  9 "ConnectCharge"  8 "ConnectDrive"  7 "SelectCharge"  6 "SelectDrive"  5 "ChargeStandbyConnect"  4 "Reserved"  3 "Charge"  2 "Drive"  1 "StandbyReady"  0 "StandbyNotReady"  ;
VAL_ 2483290115 BATT_modChildState_3  12 "connectbusjoin"  11 "connectbusprecharge"  10 "softdisconnectbus"  9 "disconnectbus"  8 "chargenormal"  7 "drivenormal"  6 "driverampdown"  5 "drivelimp"  4 "standbyready"  3 "standbyfault"  2 "standbynotready"  1 "standbysleeping"  0 "standbysleep"  ;
VAL_ 2483290115 BATT_modParentState_3  4 "Connect"  3 "Disconnect"  2 "Charge"  1 "Drive"  0 "Standby"  ;
VAL_ 2483290116 BATT_modStateRequested_4  4 "Connect"  3 "Disconnect"  2 "Charge"  1 "Drive"  0 "Standby"  ;
VAL_ 2483290116 BATT_modDataValid_4  1 "Valid"  0 "Not Valid"  ;
VAL_ 2483290116 BATT_prechargeState_4  6 "Fault"  5 "Complete"  4 "Idle"  3 "P0F1"  2 "P1F1"  1 "P1F0"  0 "P0F0"  ;
VAL_ 2483290116 BATT_fetPchgCommand_4  1 "Close"  0 "Open"  ;
VAL_ 2483290116 BATT_fetDsgCommand_4  1 "Close"  0 "Open"  ;
VAL_ 2483290116 BATT_fetChgCommand_4  1 "Close"  0 "Open"  ;
VAL_ 2483290116 BATT_fetDsgStatus_4  8 "Welded"  7 "OpenPending"  6 "FailToClose"  5 "FailToOpen"  4 "Closing"  3 "Opening"  2 "Closed"  1 "Open"  0 "Unknown"  ;
VAL_ 2483290116 BATT_fetChgStatus_4  8 "Welded"  7 "OpenPending"  6 "FailToClose"  5 "FailToOpen"  4 "Closing"  3 "Opening"  2 "Closed"  1 "Open"  0 "Unknown"  ;
VAL_ 2483290116 BATT_modPackState_4  10 "Disconnect"  9 "ConnectCharge"  8 "ConnectDrive"  7 "SelectCharge"  6 "SelectDrive"  5 "ChargeStandbyConnect"  4 "Reserved"  3 "Charge"  2 "Drive"  1 "StandbyReady"  0 "StandbyNotReady"  ;
VAL_ 2483290116 BATT_modChildState_4  12 "connectbusjoin"  11 "connectbusprecharge"  10 "softdisconnectbus"  9 "disconnectbus"  8 "chargenormal"  7 "drivenormal"  6 "driverampdown"  5 "drivelimp"  4 "standbyready"  3 "standbyfault"  2 "standbynotready"  1 "standbysleeping"  0 "standbysleep"  ;
VAL_ 2483290116 BATT_modParentState_4  4 "Connect"  3 "Disconnect"  2 "Charge"  1 "Drive"  0 "Standby"  ;
VAL_ 2483290117 BATT_modStateRequested_5  4 "Connect"  3 "Disconnect"  2 "Charge"  1 "Drive"  0 "Standby"  ;
VAL_ 2483290117 BATT_modDataValid_5  1 "Valid"  0 "Not Valid"  ;
VAL_ 2483290117 BATT_prechargeState_5  6 "Fault"  5 "Complete"  4 "Idle"  3 "P0F1"  2 "P1F1"  1 "P1F0"  0 "P0F0"  ;
VAL_ 2483290117 BATT_fetPchgCommand_5  1 "Close"  0 "Open"  ;
VAL_ 2483290117 BATT_fetDsgCommand_5  1 "Close"  0 "Open"  ;
VAL_ 2483290117 BATT_fetChgCommand_5  1 "Close"  0 "Open"  ;
VAL_ 2483290117 BATT_fetDsgStatus_5  8 "Welded"  7 "OpenPending"  6 "FailToClose"  5 "FailToOpen"  4 "Closing"  3 "Opening"  2 "Closed"  1 "Open"  0 "Unknown"  ;
VAL_ 2483290117 BATT_fetChgStatus_5  8 "Welded"  7 "OpenPending"  6 "FailToClose"  5 "FailToOpen"  4 "Closing"  3 "Opening"  2 "Closed"  1 "Open"  0 "Unknown"  ;
VAL_ 2483290117 BATT_modPackState_5  10 "Disconnect"  9 "ConnectCharge"  8 "ConnectDrive"  7 "SelectCharge"  6 "SelectDrive"  5 "ChargeStandbyConnect"  4 "Reserved"  3 "Charge"  2 "Drive"  1 "StandbyReady"  0 "StandbyNotReady"  ;
VAL_ 2483290117 BATT_modChildState_5  12 "connectbusjoin"  11 "connectbusprecharge"  10 "softdisconnectbus"  9 "disconnectbus"  8 "chargenormal"  7 "drivenormal"  6 "driverampdown"  5 "drivelimp"  4 "standbyready"  3 "standbyfault"  2 "standbynotready"  1 "standbysleeping"  0 "standbysleep"  ;
VAL_ 2483290117 BATT_modParentState_5  4 "Connect"  3 "Disconnect"  2 "Charge"  1 "Drive"  0 "Standby"  ;
VAL_ 2483290118 BATT_modStateRequested_6  4 "Connect"  3 "Disconnect"  2 "Charge"  1 "Drive"  0 "Standby"  ;
VAL_ 2483290118 BATT_modDataValid_6  1 "Valid"  0 "Not Valid"  ;
VAL_ 2483290118 BATT_prechargeState_6  6 "Fault"  5 "Complete"  4 "Idle"  3 "P0F1"  2 "P1F1"  1 "P1F0"  0 "P0F0"  ;
VAL_ 2483290118 BATT_fetPchgCommand_6  1 "Close"  0 "Open"  ;
VAL_ 2483290118 BATT_fetDsgCommand_6  1 "Close"  0 "Open"  ;
VAL_ 2483290118 BATT_fetChgCommand_6  1 "Close"  0 "Open"  ;
VAL_ 2483290118 BATT_fetDsgStatus_6  8 "Welded"  7 "OpenPending"  6 "FailToClose"  5 "FailToOpen"  4 "Closing"  3 "Opening"  2 "Closed"  1 "Open"  0 "Unknown"  ;
VAL_ 2483290118 BATT_fetChgStatus_6  8 "Welded"  7 "OpenPending"  6 "FailToClose"  5 "FailToOpen"  4 "Closing"  3 "Opening"  2 "Closed"  1 "Open"  0 "Unknown"  ;
VAL_ 2483290118 BATT_modPackState_6  10 "Disconnect"  9 "ConnectCharge"  8 "ConnectDrive"  7 "SelectCharge"  6 "SelectDrive"  5 "ChargeStandbyConnect"  4 "Reserved"  3 "Charge"  2 "Drive"  1 "StandbyReady"  0 "StandbyNotReady"  ;
VAL_ 2483290118 BATT_modChildState_6  12 "connectbusjoin"  11 "connectbusprecharge"  10 "softdisconnectbus"  9 "disconnectbus"  8 "chargenormal"  7 "drivenormal"  6 "driverampdown"  5 "drivelimp"  4 "standbyready"  3 "standbyfault"  2 "standbynotready"  1 "standbysleeping"  0 "standbysleep"  ;
VAL_ 2483290118 BATT_modParentState_6  4 "Connect"  3 "Disconnect"  2 "Charge"  1 "Drive"  0 "Standby"  ;
VAL_ 2483290119 BATT_modStateRequested_7  4 "Connect"  3 "Disconnect"  2 "Charge"  1 "Drive"  0 "Standby"  ;
VAL_ 2483290119 BATT_modDataValid_7  1 "Valid"  0 "Not Valid"  ;
VAL_ 2483290119 BATT_prechargeState_7  6 "Fault"  5 "Complete"  4 "Idle"  3 "P0F1"  2 "P1F1"  1 "P1F0"  0 "P0F0"  ;
VAL_ 2483290119 BATT_fetPchgCommand_7  1 "Close"  0 "Open"  ;
VAL_ 2483290119 BATT_fetDsgCommand_7  1 "Close"  0 "Open"  ;
VAL_ 2483290119 BATT_fetChgCommand_7  1 "Close"  0 "Open"  ;
VAL_ 2483290119 BATT_fetDsgStatus_7  8 "Welded"  7 "OpenPending"  6 "FailToClose"  5 "FailToOpen"  4 "Closing"  3 "Opening"  2 "Closed"  1 "Open"  0 "Unknown"  ;
VAL_ 2483290119 BATT_fetChgStatus_7  8 "Welded"  7 "OpenPending"  6 "FailToClose"  5 "FailToOpen"  4 "Closing"  3 "Opening"  2 "Closed"  1 "Open"  0 "Unknown"  ;
VAL_ 2483290119 BATT_modPackState_7  10 "Disconnect"  9 "ConnectCharge"  8 "ConnectDrive"  7 "SelectCharge"  6 "SelectDrive"  5 "ChargeStandbyConnect"  4 "Reserved"  3 "Charge"  2 "Drive"  1 "StandbyReady"  0 "StandbyNotReady"  ;
VAL_ 2483290119 BATT_modChildState_7  12 "connectbusjoin"  11 "connectbusprecharge"  10 "softdisconnectbus"  9 "disconnectbus"  8 "chargenormal"  7 "drivenormal"  6 "driverampdown"  5 "drivelimp"  4 "standbyready"  3 "standbyfault"  2 "standbynotready"  1 "standbysleeping"  0 "standbysleep"  ;
VAL_ 2483290119 BATT_modParentState_7  4 "Connect"  3 "Disconnect"  2 "Charge"  1 "Drive"  0 "Standby"  ;
VAL_ 2483290120 BATT_modStateRequested_8  4 "Connect"  3 "Disconnect"  2 "Charge"  1 "Drive"  0 "Standby"  ;
VAL_ 2483290120 BATT_modDataValid_8  1 "Valid"  0 "Not Valid"  ;
VAL_ 2483290120 BATT_prechargeState_8  6 "Fault"  5 "Complete"  4 "Idle"  3 "P0F1"  2 "P1F1"  1 "P1F0"  0 "P0F0"  ;
VAL_ 2483290120 BATT_fetPchgCommand_8  1 "Close"  0 "Open"  ;
VAL_ 2483290120 BATT_fetDsgCommand_8  1 "Close"  0 "Open"  ;
VAL_ 2483290120 BATT_fetChgCommand_8  1 "Close"  0 "Open"  ;
VAL_ 2483290120 BATT_fetDsgStatus_8  8 "Welded"  7 "OpenPending"  6 "FailToClose"  5 "FailToOpen"  4 "Closing"  3 "Opening"  2 "Closed"  1 "Open"  0 "Unknown"  ;
VAL_ 2483290120 BATT_fetChgStatus_8  8 "Welded"  7 "OpenPending"  6 "FailToClose"  5 "FailToOpen"  4 "Closing"  3 "Opening"  2 "Closed"  1 "Open"  0 "Unknown"  ;
VAL_ 2483290120 BATT_modPackState_8  10 "Disconnect"  9 "ConnectCharge"  8 "ConnectDrive"  7 "SelectCharge"  6 "SelectDrive"  5 "ChargeStandbyConnect"  4 "Reserved"  3 "Charge"  2 "Drive"  1 "StandbyReady"  0 "StandbyNotReady"  ;
VAL_ 2483290120 BATT_modChildState_8  12 "connectbusjoin"  11 "connectbusprecharge"  10 "softdisconnectbus"  9 "disconnectbus"  8 "chargenormal"  7 "drivenormal"  6 "driverampdown"  5 "drivelimp"  4 "standbyready"  3 "standbyfault"  2 "standbynotready"  1 "standbysleeping"  0 "standbysleep"  ;
VAL_ 2483290120 BATT_modParentState_8  4 "Connect"  3 "Disconnect"  2 "Charge"  1 "Drive"  0 "Standby"  ;
VAL_ 2483290121 BATT_modStateRequested_9  4 "Connect"  3 "Disconnect"  2 "Charge"  1 "Drive"  0 "Standby"  ;
VAL_ 2483290121 BATT_modDataValid_9  1 "Valid"  0 "Not Valid"  ;
VAL_ 2483290121 BATT_prechargeState_9  6 "Fault"  5 "Complete"  4 "Idle"  3 "P0F1"  2 "P1F1"  1 "P1F0"  0 "P0F0"  ;
VAL_ 2483290121 BATT_fetPchgCommand_9  1 "Close"  0 "Open"  ;
VAL_ 2483290121 BATT_fetDsgCommand_9  1 "Close"  0 "Open"  ;
VAL_ 2483290121 BATT_fetChgCommand_9  1 "Close"  0 "Open"  ;
VAL_ 2483290121 BATT_fetDsgStatus_9  8 "Welded"  7 "OpenPending"  6 "FailToClose"  5 "FailToOpen"  4 "Closing"  3 "Opening"  2 "Closed"  1 "Open"  0 "Unknown"  ;
VAL_ 2483290121 BATT_fetChgStatus_9  8 "Welded"  7 "OpenPending"  6 "FailToClose"  5 "FailToOpen"  4 "Closing"  3 "Opening"  2 "Closed"  1 "Open"  0 "Unknown"  ;
VAL_ 2483290121 BATT_modPackState_9  10 "Disconnect"  9 "ConnectCharge"  8 "ConnectDrive"  7 "SelectCharge"  6 "SelectDrive"  5 "ChargeStandbyConnect"  4 "Reserved"  3 "Charge"  2 "Drive"  1 "StandbyReady"  0 "StandbyNotReady"  ;
VAL_ 2483290121 BATT_modChildState_9  12 "connectbusjoin"  11 "connectbusprecharge"  10 "softdisconnectbus"  9 "disconnectbus"  8 "chargenormal"  7 "drivenormal"  6 "driverampdown"  5 "drivelimp"  4 "standbyready"  3 "standbyfault"  2 "standbynotready"  1 "standbysleeping"  0 "standbysleep"  ;
VAL_ 2483290121 BATT_modParentState_9  4 "Connect"  3 "Disconnect"  2 "Charge"  1 "Drive"  0 "Standby"  ;
VAL_ 2483290122 BATT_modStateRequested_10  4 "Connect"  3 "Disconnect"  2 "Charge"  1 "Drive"  0 "Standby"  ;
VAL_ 2483290122 BATT_modDataValid_10  1 "Valid"  0 "Not Valid"  ;
VAL_ 2483290122 BATT_prechargeState_10  6 "Fault"  5 "Complete"  4 "Idle"  3 "P0F1"  2 "P1F1"  1 "P1F0"  0 "P0F0"  ;
VAL_ 2483290122 BATT_fetPchgCommand_10  1 "Close"  0 "Open"  ;
VAL_ 2483290122 BATT_fetDsgCommand_10  1 "Close"  0 "Open"  ;
VAL_ 2483290122 BATT_fetChgCommand_10  1 "Close"  0 "Open"  ;
VAL_ 2483290122 BATT_fetDsgStatus_10  8 "Welded"  7 "OpenPending"  6 "FailToClose"  5 "FailToOpen"  4 "Closing"  3 "Opening"  2 "Closed"  1 "Open"  0 "Unknown"  ;
VAL_ 2483290122 BATT_fetChgStatus_10  8 "Welded"  7 "OpenPending"  6 "FailToClose"  5 "FailToOpen"  4 "Closing"  3 "Opening"  2 "Closed"  1 "Open"  0 "Unknown"  ;
VAL_ 2483290122 BATT_modPackState_10  10 "Disconnect"  9 "ConnectCharge"  8 "ConnectDrive"  7 "SelectCharge"  6 "SelectDrive"  5 "ChargeStandbyConnect"  4 "Reserved"  3 "Charge"  2 "Drive"  1 "StandbyReady"  0 "StandbyNotReady"  ;
VAL_ 2483290122 BATT_modChildState_10  12 "connectbusjoin"  11 "connectbusprecharge"  10 "softdisconnectbus"  9 "disconnectbus"  8 "chargenormal"  7 "drivenormal"  6 "driverampdown"  5 "drivelimp"  4 "standbyready"  3 "standbyfault"  2 "standbynotready"  1 "standbysleeping"  0 "standbysleep"  ;
VAL_ 2483290122 BATT_modParentState_10  4 "Connect"  3 "Disconnect"  2 "Charge"  1 "Drive"  0 "Standby"  ;
VAL_ 2483290123 BATT_modStateRequested_11  4 "Connect"  3 "Disconnect"  2 "Charge"  1 "Drive"  0 "Standby"  ;
VAL_ 2483290123 BATT_modDataValid_11  1 "Valid"  0 "Not Valid"  ;
VAL_ 2483290123 BATT_prechargeState_11  6 "Fault"  5 "Complete"  4 "Idle"  3 "P0F1"  2 "P1F1"  1 "P1F0"  0 "P0F0"  ;
VAL_ 2483290123 BATT_fetPchgCommand_11  1 "Close"  0 "Open"  ;
VAL_ 2483290123 BATT_fetDsgCommand_11  1 "Close"  0 "Open"  ;
VAL_ 2483290123 BATT_fetChgCommand_11  1 "Close"  0 "Open"  ;
VAL_ 2483290123 BATT_fetDsgStatus_11  8 "Welded"  7 "OpenPending"  6 "FailToClose"  5 "FailToOpen"  4 "Closing"  3 "Opening"  2 "Closed"  1 "Open"  0 "Unknown"  ;
VAL_ 2483290123 BATT_fetChgStatus_11  8 "Welded"  7 "OpenPending"  6 "FailToClose"  5 "FailToOpen"  4 "Closing"  3 "Opening"  2 "Closed"  1 "Open"  0 "Unknown"  ;
VAL_ 2483290123 BATT_modPackState_11  10 "Disconnect"  9 "ConnectCharge"  8 "ConnectDrive"  7 "SelectCharge"  6 "SelectDrive"  5 "ChargeStandbyConnect"  4 "Reserved"  3 "Charge"  2 "Drive"  1 "StandbyReady"  0 "StandbyNotReady"  ;
VAL_ 2483290123 BATT_modChildState_11  12 "connectbusjoin"  11 "connectbusprecharge"  10 "softdisconnectbus"  9 "disconnectbus"  8 "chargenormal"  7 "drivenormal"  6 "driverampdown"  5 "drivelimp"  4 "standbyready"  3 "standbyfault"  2 "standbynotready"  1 "standbysleeping"  0 "standbysleep"  ;
VAL_ 2483290123 BATT_modParentState_11  4 "Connect"  3 "Disconnect"  2 "Charge"  1 "Drive"  0 "Standby"  ;
VAL_ 2550661120 BATT_deviceChemistry_0  7 "LiP"  6 "ZnAr"  5 "RAM"  4 "NiZn"  3 "NiMH"  2 "NiCd"  1 "LION"  0 "PbAc"  ;
VAL_ 2550661121 BATT_deviceChemistry_1  7 "LiP"  6 "ZnAr"  5 "RAM"  4 "NiZn"  3 "NiMH"  2 "NiCd"  1 "LION"  0 "PbAc"  ;
VAL_ 2550661122 BATT_deviceChemistry_2  7 "LiP"  6 "ZnAr"  5 "RAM"  4 "NiZn"  3 "NiMH"  2 "NiCd"  1 "LION"  0 "PbAc"  ;
VAL_ 2550661123 BATT_deviceChemistry_3  7 "LiP"  6 "ZnAr"  5 "RAM"  4 "NiZn"  3 "NiMH"  2 "NiCd"  1 "LION"  0 "PbAc"  ;
VAL_ 2550661124 BATT_deviceChemistry_4  7 "LiP"  6 "ZnAr"  5 "RAM"  4 "NiZn"  3 "NiMH"  2 "NiCd"  1 "LION"  0 "PbAc"  ;
VAL_ 2550661125 BATT_deviceChemistry_5  7 "LiP"  6 "ZnAr"  5 "RAM"  4 "NiZn"  3 "NiMH"  2 "NiCd"  1 "LION"  0 "PbAc"  ;
VAL_ 2550661126 BATT_deviceChemistry_6  7 "LiP"  6 "ZnAr"  5 "RAM"  4 "NiZn"  3 "NiMH"  2 "NiCd"  1 "LION"  0 "PbAc"  ;
VAL_ 2550661127 BATT_deviceChemistry_7  7 "LiP"  6 "ZnAr"  5 "RAM"  4 "NiZn"  3 "NiMH"  2 "NiCd"  1 "LION"  0 "PbAc"  ;
VAL_ 2550661128 BATT_deviceChemistry_8  7 "LiP"  6 "ZnAr"  5 "RAM"  4 "NiZn"  3 "NiMH"  2 "NiCd"  1 "LION"  0 "PbAc"  ;
VAL_ 2550661129 BATT_deviceChemistry_9  7 "LiP"  6 "ZnAr"  5 "RAM"  4 "NiZn"  3 "NiMH"  2 "NiCd"  1 "LION"  0 "PbAc"  ;
VAL_ 2550661130 BATT_deviceChemistry_10  7 "LiP"  6 "ZnAr"  5 "RAM"  4 "NiZn"  3 "NiMH"  2 "NiCd"  1 "LION"  0 "PbAc"  ;
VAL_ 2550661131 BATT_deviceChemistry_11  7 "LiP"  6 "ZnAr"  5 "RAM"  4 "NiZn"  3 "NiMH"  2 "NiCd"  1 "LION"  0 "PbAc"  ;
